VERSION ""

NS_ :

BS_:

BU_: Turbocharger OnBoardDataLogger OffBoardDiagnosticTool2 OffBoardDiagnosticTool1 FileServer ParkingBrakeController SeatControl2 FanDriveController SteeringColumnUnit CommunicationUnitRadio CommunicationUnitSatellite CommunicationUnitCellular PropulsionBatteryCharger ChassisController2 ChassisController1 EngineValveControl AuxiliaryHeater2 AuxiliaryHeater1 ClutchUnit RampControl InformationSystem1 SuspensionSystemController2 OilSensor VehicleDynamicStability ExhaustEmissionController TransmissionDisplay2 TransmissionDisplay1 ClimateControl2 WaterPumpController RearAxleSteeringController LightingOperatorControl SeatController1 IgnitionController2 IgnitionController1 TirePressureController CabController2 CabController1 PneumaticSystemController SuspensionSystemController1 HydraulicPumpController EnduranceBrakingSystem RetarderExhaustEngine2 OnBoardDiagnosticUnit HeadwayController RetarderExhaustEngine1 CabDisplay1 ManagementComputer VirtualTerminal OffVehicleGateway PowerTakeOffFront HitchControl AuxiliaryValveControl BodyController TractorTrailerBridge1 StarterSystem ElectricalSystem VehicleSecurity VehicleNavigation AerodynamicControl ElectricalChargingSystem ClimateControl1 TripRecorder InstrumentCluster SuspensionDriveAxle2 SuspensionDriveAxle1 SuspensionSteerAxle SteeringController FuelSystem CruiseControl RetarderDriveline RetarderEngine BrakesDriveAxle2 BrakesDriveAxle1 BrakesSystemController BrakesSteerAxle AxleDrive2 AxleDrive1 AxleSteering PowerTakeOff ShiftConsoleSecondary ShiftConsolePrimary Transmission2 Transmission1 Engine2 Engine1

BO_ 0000000000 DoS: 8 Vector__XXX
 SG_ DenialofService : 0|16@1+ (0.0025,0) [0|160.6375] "%" Vector__XXX

BO_ 3221225472 VECTOR__INDEPENDENT_SIG_MSG: 0 Vector__XXX
 SG_ TrailerWeight : 0|16@1+ (2,0) [0|128510] "kg" Vector__XXX
 SG_ ReferenceTirePressSetting : 0|8@1+ (8,0) [0|2000] "kPa" Vector__XXX
 SG_ ReferenceTirePress : 0|8@1+ (8,0) [0|2000] "kPa" Vector__XXX
 SG_ TirePressThresholdDetection : 0|3@1+ (1,0) [0|7] "" Vector__XXX
 SG_ TireAirLeakageRate : 0|16@1+ (0.1,0) [0|6425.5] "Pa/s" Vector__XXX
 SG_ CTIWheelEndElectricalFault : 0|2@1+ (1,0) [0|3] "" Vector__XXX
 SG_ CTITireStatus : 0|2@1+ (1,0) [0|3] "" Vector__XXX
 SG_ CTIWheelSensorStatus : 0|2@1+ (1,0) [0|3] "" Vector__XXX
 SG_ TireTemp : 0|16@1+ (0.03125,-273) [-273|1734.96875] "deg C" Vector__XXX
 SG_ TirePress : 0|8@1+ (4,0) [0|1000] "kPa" Vector__XXX

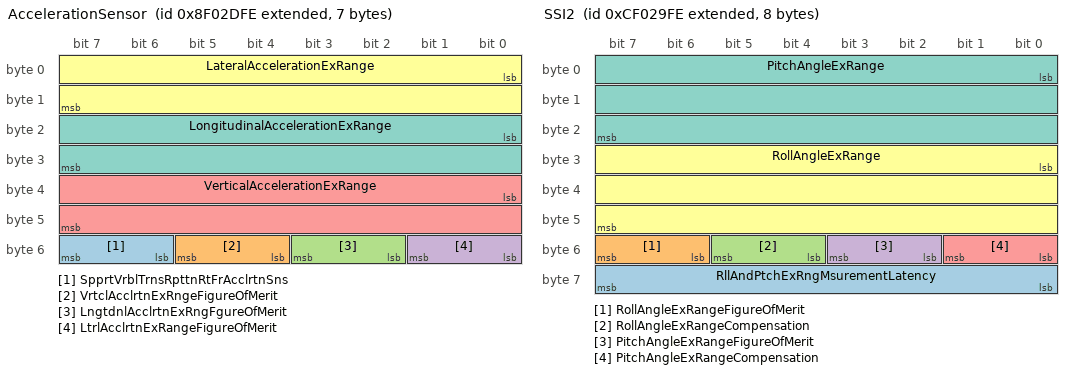
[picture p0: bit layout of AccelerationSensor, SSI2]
BO_ 2297441790 AccelerationSensor: 7 Vector__XXX
 SG_ SpprtVrblTrnsRpttnRtFrAcclrtnSns : 54|2@1+ (1,0) [0|3] "" Vector__XXX
 SG_ VrtclAcclrtnExRngeFigureOfMerit : 52|2@1+ (1,0) [0|3] "" Vector__XXX
 SG_ LngtdnlAcclrtnExRngFgureOfMerit : 50|2@1+ (1,0) [0|3] "" Vector__XXX
 SG_ LtrlAcclrtnExRangeFigureOfMerit : 48|2@1+ (1,0) [0|3] "" Vector__XXX
 SG_ VerticalAccelerationExRange : 32|16@1+ (0.01,-320) [-320|322.55] "m/s/s" Vector__XXX
 SG_ LateralAccelerationExRange : 0|16@1+ (0.01,-320) [-320|322.55] "m/s/s" Vector__XXX
 SG_ LongitudinalAccelerationExRange : 16|16@1+ (0.01,-320) [-320|322.55] "m/s/s" Vector__XXX

BO_ 2566712062 VEP4: 8 Vector__XXX
 SG_ HybrdBatteryPackRemainingCharge : 0|16@1+ (0.0025,0) [0|160.6375] "%" Vector__XXX

BO_ 2364549630 SSI2: 8 Vector__XXX
 SG_ RllAndPtchExRngMsurementLatency : 56|8@1+ (0.5,0) [0|125] "ms" Vector__XXX
 SG_ RollAngleExRangeFigureOfMerit : 54|2@1+ (1,0) [0|3] "" Vector__XXX
 SG_ RollAngleExRangeCompensation : 52|2@1+ (1,0) [0|3] "" Vector__XXX
 SG_ PitchAngleExRangeFigureOfMerit : 50|2@1+ (1,0) [0|3] "" Vector__XXX
 SG_ PitchAngleExRangeCompensation : 48|2@1+ (1,0) [0|3] "" Vector__XXX
 SG_ RollAngleExRange : 24|24@1+ (3.0517578125E-005,-250) [-250|250.9999] "deg" Vector__XXX
 SG_ PitchAngleExRange : 0|24@1+ (3.0517578125E-005,-250) [-250|250.9999] "deg" Vector__XXX

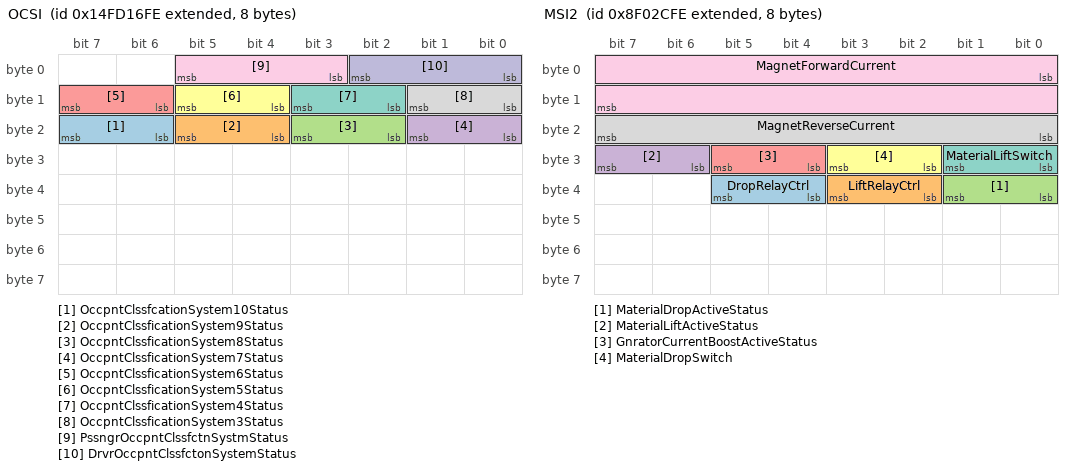
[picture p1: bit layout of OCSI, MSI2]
BO_ 2499614462 OCSI: 8 Vector__XXX
 SG_ OccpntClssfcationSystem10Status : 22|2@1+ (1,0) [0|3] "" Vector__XXX
 SG_ OccpntClssficationSystem9Status : 20|2@1+ (1,0) [0|3] "" Vector__XXX
 SG_ OccpntClssficationSystem8Status : 18|2@1+ (1,0) [0|3] "" Vector__XXX
 SG_ OccpntClssficationSystem7Status : 16|2@1+ (1,0) [0|3] "" Vector__XXX
 SG_ OccpntClssficationSystem6Status : 14|2@1+ (1,0) [0|3] "" Vector__XXX
 SG_ OccpntClssficationSystem5Status : 12|2@1+ (1,0) [0|3] "" Vector__XXX
 SG_ OccpntClssficationSystem4Status : 10|2@1+ (1,0) [0|3] "" Vector__XXX
 SG_ OccpntClssficationSystem3Status : 8|2@1+ (1,0) [0|3] "" Vector__XXX
 SG_ PssngrOccpntClssfctnSystmStatus : 3|3@1+ (1,0) [0|7] "" Vector__XXX
 SG_ DrvrOccpntClssfctonSystemStatus : 0|3@1+ (1,0) [0|7] "" Vector__XXX

BO_ 2560098046 NCS: 8 Vector__XXX
 SG_ CabNoiseCtrlTuningStatus : 2|4@1+ (1,0) [0|15] "" Vector__XXX
 SG_ CabNoiseCtrlStatus : 0|2@1+ (1,0) [0|3] "" Vector__XXX

BO_ 2560163582 NC1: 8 Vector__XXX
 SG_ CabNoiseCtrlTuningState : 2|3@1+ (1,0) [0|7] "" Vector__XXX
 SG_ CabNoiseCtrlState : 0|2@1+ (1,0) [0|3] "" Vector__XXX

BO_ 2297441534 MSI2: 8 Vector__XXX
 SG_ DropRelayCtrl : 36|2@1+ (1,0) [0|3] "" Vector__XXX
 SG_ LiftRelayCtrl : 34|2@1+ (1,0) [0|3] "" Vector__XXX
 SG_ MaterialDropActiveStatus : 32|2@1+ (1,0) [0|3] "" Vector__XXX
 SG_ MaterialLiftActiveStatus : 30|2@1+ (1,0) [0|3] "" Vector__XXX
 SG_ GnratorCurrentBoostActiveStatus : 28|2@1+ (1,0) [0|3] "" Vector__XXX
 SG_ MaterialDropSwitch : 26|2@1+ (1,0) [0|3] "" Vector__XXX
 SG_ MaterialLiftSwitch : 24|2@1+ (1,0) [0|3] "" Vector__XXX
 SG_ MagnetReverseCurrent : 16|8@1+ (1,0) [0|250] "A" Vector__XXX
 SG_ MagnetForwardCurrent : 0|16@1+ (1,0) [0|64255] "Amps" Vector__XXX

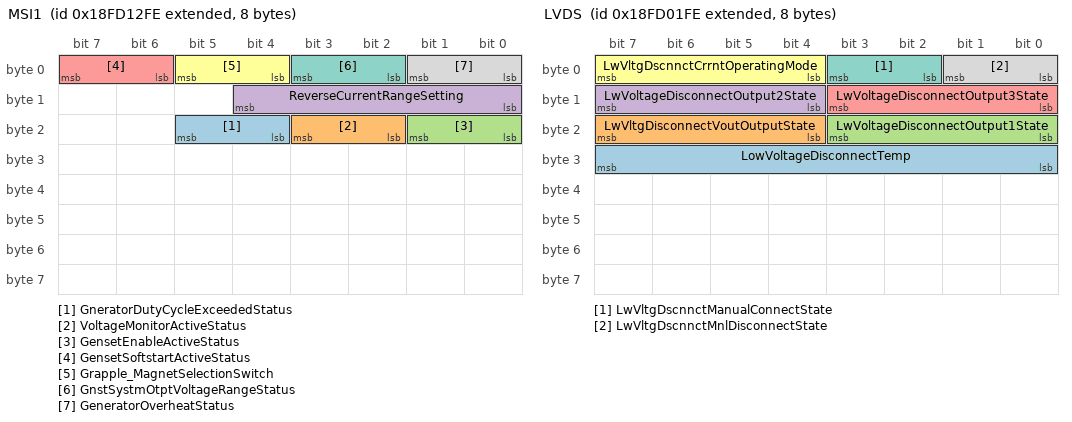
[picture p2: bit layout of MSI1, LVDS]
BO_ 2566722302 MSI1: 8 Vector__XXX
 SG_ GneratorDutyCycleExceededStatus : 20|2@1+ (1,0) [0|3] "" Vector__XXX
 SG_ VoltageMonitorActiveStatus : 18|2@1+ (1,0) [0|3] "" Vector__XXX
 SG_ GensetEnableActiveStatus : 16|2@1+ (1,0) [0|3] "" Vector__XXX
 SG_ ReverseCurrentRangeSetting : 8|5@1+ (1,0) [0|31] "" Vector__XXX
 SG_ GensetSoftstartActiveStatus : 6|2@1+ (1,0) [0|3] "" Vector__XXX
 SG_ Grapple_MagnetSelectionSwitch : 4|2@1+ (1,0) [0|3] "" Vector__XXX
 SG_ GnstSystmOtptVoltageRangeStatus : 2|2@1+ (1,0) [0|3] "" Vector__XXX
 SG_ GeneratorOverheatStatus : 0|2@1+ (1,0) [0|3] "" Vector__XXX

BO_ 2566722558 MSCI: 8 Vector__XXX
 SG_ MagnetRatedPower : 8|16@1+ (0.5,0) [0|32127.5] "kW" Vector__XXX
 SG_ MagnetBoostTime : 0|8@1+ (0.25,0) [0|62.5] "s" Vector__XXX

BO_ 2560032510 LVDSOM: 8 Vector__XXX
 SG_ LwVltgDscnnctDsredOperatingMode : 0|4@1+ (1,0) [0|15] "" Vector__XXX

BO_ 2566717950 LVDS: 8 Vector__XXX
 SG_ LowVoltageDisconnectTemp : 24|8@1+ (1,-40) [-40|210] "deg C" Vector__XXX
 SG_ LwVltgDisconnectVoutOutputState : 20|4@1+ (1,0) [0|15] "" Vector__XXX
 SG_ LwVoltageDisconnectOutput1State : 16|4@1+ (1,0) [0|15] "" Vector__XXX
 SG_ LwVoltageDisconnectOutput2State : 12|4@1+ (1,0) [0|15] "" Vector__XXX
 SG_ LwVoltageDisconnectOutput3State : 8|4@1+ (1,0) [0|15] "" Vector__XXX
 SG_ LwVltgDscnnctCrrntOperatingMode : 4|4@1+ (1,0) [0|15] "" Vector__XXX
 SG_ LwVltgDscnnctManualConnectState : 2|2@1+ (1,0) [0|3] "" Vector__XXX
 SG_ LwVltgDscnnctMnlDisconnectState : 0|2@1+ (1,0) [0|3] "" Vector__XXX

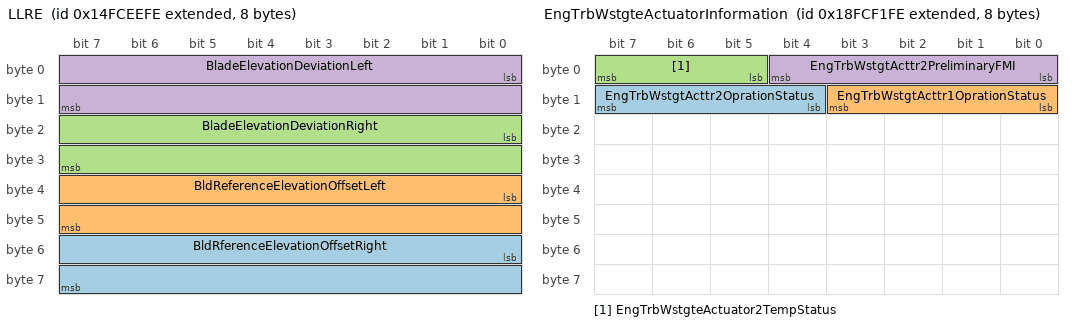
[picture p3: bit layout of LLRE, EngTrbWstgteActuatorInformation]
BO_ 2499604222 LLRE: 8 Vector__XXX
 SG_ BldRferenceElevationOffsetRight : 48|16@1+ (1,-32000) [-32000|32255] "mm" Vector__XXX
 SG_ BldReferenceElevationOffsetLeft : 32|16@1+ (1,-32000) [-32000|32255] "mm" Vector__XXX
 SG_ BladeElevationDeviationRight : 16|16@1+ (1,-32000) [-32000|32255] "mm" Vector__XXX
 SG_ BladeElevationDeviationLeft : 0|16@1+ (1,-32000) [-32000|32255] "mm" Vector__XXX

BO_ 2358902526 JLCM: 8 Vector__XXX
 SG_ Joystick3Lamp10Cmd : 58|2@1+ (1,0) [0|3] "" Vector__XXX
 SG_ Joystick3Lamp9Cmd : 56|2@1+ (1,0) [0|3] "" Vector__XXX
 SG_ Joystick3Lamp8Cmd : 54|2@1+ (1,0) [0|3] "" Vector__XXX
 SG_ Joystick3Lamp7Cmd : 52|2@1+ (1,0) [0|3] "" Vector__XXX
 SG_ Joystick3Lamp6Cmd : 50|2@1+ (1,0) [0|3] "" Vector__XXX
 SG_ Joystick3Lamp5Cmd : 48|2@1+ (1,0) [0|3] "" Vector__XXX
 SG_ Joystick3Lamp4Cmd : 46|2@1+ (1,0) [0|3] "" Vector__XXX
 SG_ Joystick3Lamp3Cmd : 44|2@1+ (1,0) [0|3] "" Vector__XXX
 SG_ Joystick3Lamp2Cmd : 42|2@1+ (1,0) [0|3] "" Vector__XXX
 SG_ Joystick3Lamp1Cmd : 40|2@1+ (1,0) [0|3] "" Vector__XXX
 SG_ Joystick2Lamp10Cmd : 38|2@1+ (1,0) [0|3] "" Vector__XXX
 SG_ Joystick2Lamp9Cmd : 36|2@1+ (1,0) [0|3] "" Vector__XXX
 SG_ Joystick2Lamp8Cmd : 34|2@1+ (1,0) [0|3] "" Vector__XXX
 SG_ Joystick2Lamp7Cmd : 32|2@1+ (1,0) [0|3] "" Vector__XXX
 SG_ Joystick2Lamp6Cmd : 30|2@1+ (1,0) [0|3] "" Vector__XXX
 SG_ Joystick2Lamp5Cmd : 28|2@1+ (1,0) [0|3] "" Vector__XXX
 SG_ Joystick2Lamp4Cmd : 26|2@1+ (1,0) [0|3] "" Vector__XXX
 SG_ Joystick2Lamp3Cmd : 24|2@1+ (1,0) [0|3] "" Vector__XXX
 SG_ Joystick2Lamp2Cmd : 22|2@1+ (1,0) [0|3] "" Vector__XXX
 SG_ Joystick2Lamp1Cmd : 20|2@1+ (1,0) [0|3] "" Vector__XXX
 SG_ Joystick1Lamp10Cmd : 18|2@1+ (1,0) [0|3] "" Vector__XXX
 SG_ Joystick1Lamp9Cmd : 16|2@1+ (1,0) [0|3] "" Vector__XXX
 SG_ Joystick1Lamp8Cmd : 14|2@1+ (1,0) [0|3] "" Vector__XXX
 SG_ Joystick1Lamp7Cmd : 12|2@1+ (1,0) [0|3] "" Vector__XXX
 SG_ Joystick1Lamp6Cmd : 10|2@1+ (1,0) [0|3] "" Vector__XXX
 SG_ Joystick1Lamp5Cmd : 8|2@1+ (1,0) [0|3] "" Vector__XXX
 SG_ Joystick1Lamp4Cmd : 6|2@1+ (1,0) [0|3] "" Vector__XXX
 SG_ Joystick1Lamp3Cmd : 4|2@1+ (1,0) [0|3] "" Vector__XXX
 SG_ Joystick1Lamp2Cmd : 2|2@1+ (1,0) [0|3] "" Vector__XXX
 SG_ Joystick1Lamp1Cmd : 0|2@1+ (1,0) [0|3] "" Vector__XXX

BO_ 2566711550 IVAC: 8 Vector__XXX
 SG_ IntkVlvActtnSystmOlPrss2SlndCtrl : 2|2@1+ (1,0) [0|3] "" Vector__XXX
 SG_ IntkVlvActtnSystmOlPrss1SlndCtrl : 0|2@1+ (1,0) [0|3] "" Vector__XXX

BO_ 2633832958 ILI: 200 Vector__XXX
 SG_ SpecialIgnitorLoop90Resistance : 1584|16@1+ (0.1,0) [0|6425.5] "ohm" Vector__XXX
 SG_ SpecialIgnitorLoop89Resistance : 1568|16@1+ (0.1,0) [0|6425.5] "ohm" Vector__XXX
 SG_ SpecialIgnitorLoop88Resistance : 1552|16@1+ (0.1,0) [0|6425.5] "ohm" Vector__XXX
 SG_ SpecialIgnitorLoop87Resistance : 1536|16@1+ (0.1,0) [0|6425.5] "ohm" Vector__XXX
 SG_ SpecialIgnitorLoop86Resistance : 1520|16@1+ (0.1,0) [0|6425.5] "ohm" Vector__XXX
 SG_ SpecialIgnitorLoop85Resistance : 1504|16@1+ (0.1,0) [0|6425.5] "ohm" Vector__XXX
 SG_ SpecialIgnitorLoop84Resistance : 1488|16@1+ (0.1,0) [0|6425.5] "ohm" Vector__XXX
 SG_ SpecialIgnitorLoop83Resistance : 1472|16@1+ (0.1,0) [0|6425.5] "ohm" Vector__XXX
 SG_ SpecialIgnitorLoop82Resistance : 1456|16@1+ (0.1,0) [0|6425.5] "ohm" Vector__XXX
 SG_ SpecialIgnitorLoop81Resistance : 1440|16@1+ (0.1,0) [0|6425.5] "ohm" Vector__XXX
 SG_ SpecialIgnitorLoop80Resistance : 1424|16@1+ (0.1,0) [0|6425.5] "ohm" Vector__XXX
 SG_ SpecialIgnitorLoop79Resistance : 1408|16@1+ (0.1,0) [0|6425.5] "ohm" Vector__XXX
 SG_ SpecialIgnitorLoop78Resistance : 1392|16@1+ (0.1,0) [0|6425.5] "ohm" Vector__XXX
 SG_ SpecialIgnitorLoop77Resistance : 1376|16@1+ (0.1,0) [0|6425.5] "ohm" Vector__XXX
 SG_ SpecialIgnitorLoop76Resistance : 1360|16@1+ (0.1,0) [0|6425.5] "ohm" Vector__XXX
 SG_ SpecialIgnitorLoop75Resistance : 1344|16@1+ (0.1,0) [0|6425.5] "ohm" Vector__XXX
 SG_ SpecialIgnitorLoop74Resistance : 1328|16@1+ (0.1,0) [0|6425.5] "ohm" Vector__XXX
 SG_ SpecialIgnitorLoop73Resistance : 1312|16@1+ (0.1,0) [0|6425.5] "ohm" Vector__XXX
 SG_ SpecialIgnitorLoop72Resistance : 1296|16@1+ (0.1,0) [0|6425.5] "ohm" Vector__XXX
 SG_ SpecialIgnitorLoop71Resistance : 1280|16@1+ (0.1,0) [0|6425.5] "ohm" Vector__XXX
 SG_ SpecialIgnitorLoop70Resistance : 1264|16@1+ (0.1,0) [0|6425.5] "ohm" Vector__XXX
 SG_ SpecialIgnitorLoop69Resistance : 1248|16@1+ (0.1,0) [0|6425.5] "ohm" Vector__XXX
 SG_ SpecialIgnitorLoop68Resistance : 1232|16@1+ (0.1,0) [0|6425.5] "ohm" Vector__XXX
 SG_ SpecialIgnitorLoop67Resistance : 1216|16@1+ (0.1,0) [0|6425.5] "ohm" Vector__XXX
 SG_ SpecialIgnitorLoop66Resistance : 1200|16@1+ (0.1,0) [0|6425.5] "ohm" Vector__XXX
 SG_ SpecialIgnitorLoop65Resistance : 1184|16@1+ (0.1,0) [0|6425.5] "ohm" Vector__XXX
 SG_ SpecialIgnitorLoop64Resistance : 1168|16@1+ (0.1,0) [0|6425.5] "ohm" Vector__XXX
 SG_ SpecialIgnitorLoop63Resistance : 1152|16@1+ (0.1,0) [0|6425.5] "ohm" Vector__XXX
 SG_ SpecialIgnitorLoop61Resistance : 1120|16@1+ (0.1,0) [0|6425.5] "ohm" Vector__XXX
 SG_ SpecialIgnitorLoop60Resistance : 1104|16@1+ (0.1,0) [0|6425.5] "ohm" Vector__XXX
 SG_ SpecialIgnitorLoop59Resistance : 1088|16@1+ (0.1,0) [0|6425.5] "ohm" Vector__XXX
 SG_ SpecialIgnitorLoop58Resistance : 1072|16@1+ (0.1,0) [0|6425.5] "ohm" Vector__XXX
 SG_ SpecialIgnitorLoop57Resistance : 1056|16@1+ (0.1,0) [0|6425.5] "ohm" Vector__XXX
 SG_ SpecialIgnitorLoop56Resistance : 1040|16@1+ (0.1,0) [0|6425.5] "ohm" Vector__XXX
 SG_ SpecialIgnitorLoop55Resistance : 1024|16@1+ (0.1,0) [0|6425.5] "ohm" Vector__XXX
 SG_ SpecialIgnitorLoop54Resistance : 1008|16@1+ (0.1,0) [0|6425.5] "ohm" Vector__XXX
 SG_ SpecialIgnitorLoop53Resistance : 992|16@1+ (0.1,0) [0|6425.5] "ohm" Vector__XXX
 SG_ SpecialIgnitorLoop52Resistance : 976|16@1+ (0.1,0) [0|6425.5] "ohm" Vector__XXX
 SG_ SpecialIgnitorLoop51Resistance : 960|16@1+ (0.1,0) [0|6425.5] "ohm" Vector__XXX
 SG_ SpecialIgnitorLoop50Resistance : 944|16@1+ (0.1,0) [0|6425.5] "ohm" Vector__XXX
 SG_ SpecialIgnitorLoop49Resistance : 928|16@1+ (0.1,0) [0|6425.5] "ohm" Vector__XXX
 SG_ SpecialIgnitorLoop48Resistance : 912|16@1+ (0.1,0) [0|6425.5] "ohm" Vector__XXX
 SG_ SpecialIgnitorLoop47Resistance : 896|16@1+ (0.1,0) [0|6425.5] "ohm" Vector__XXX
 SG_ SpecialIgnitorLoop46Resistance : 880|16@1+ (0.1,0) [0|6425.5] "ohm" Vector__XXX
 SG_ SpecialIgnitorLoop45Resistance : 864|16@1+ (0.1,0) [0|6425.5] "ohm" Vector__XXX
 SG_ SpecialIgnitorLoop44Resistance : 848|16@1+ (0.1,0) [0|6425.5] "ohm" Vector__XXX
 SG_ SpecialIgnitorLoop43Resistance : 832|16@1+ (0.1,0) [0|6425.5] "ohm" Vector__XXX
 SG_ SpecialIgnitorLoop42Resistance : 816|16@1+ (0.1,0) [0|6425.5] "ohm" Vector__XXX
 SG_ SpecialIgnitorLoop41Resistance : 800|16@1+ (0.1,0) [0|6425.5] "ohm" Vector__XXX
 SG_ SpecialIgnitorLoop40Resistance : 784|16@1+ (0.1,0) [0|6425.5] "ohm" Vector__XXX
 SG_ SpecialIgnitorLoop39Resistance : 768|16@1+ (0.1,0) [0|6425.5] "ohm" Vector__XXX
 SG_ SpecialIgnitorLoop38Resistance : 752|16@1+ (0.1,0) [0|6425.5] "ohm" Vector__XXX
 SG_ SpecialIgnitorLoop37Resistance : 736|16@1+ (0.1,0) [0|6425.5] "ohm" Vector__XXX
 SG_ SpecialIgnitorLoop36Resistance : 720|16@1+ (0.1,0) [0|6425.5] "ohm" Vector__XXX
 SG_ SpecialIgnitorLoop35Resistance : 704|16@1+ (0.1,0) [0|6425.5] "ohm" Vector__XXX
 SG_ SpecialIgnitorLoop34Resistance : 688|16@1+ (0.1,0) [0|6425.5] "ohm" Vector__XXX
 SG_ SpecialIgnitorLoop33Resistance : 672|16@1+ (0.1,0) [0|6425.5] "ohm" Vector__XXX
 SG_ SpecialIgnitorLoop32Resistance : 656|16@1+ (0.1,0) [0|6425.5] "ohm" Vector__XXX
 SG_ SpecialIgnitorLoop31Resistance : 640|16@1+ (0.1,0) [0|6425.5] "ohm" Vector__XXX
 SG_ SpecialIgnitorLoop30Resistance : 624|16@1+ (0.1,0) [0|6425.5] "ohm" Vector__XXX
 SG_ SpecialIgnitorLoop29Resistance : 608|16@1+ (0.1,0) [0|6425.5] "ohm" Vector__XXX
 SG_ SpecialIgnitorLoop28Resistance : 592|16@1+ (0.1,0) [0|6425.5] "ohm" Vector__XXX
 SG_ SpecialIgnitorLoop27Resistance : 576|16@1+ (0.1,0) [0|6425.5] "ohm" Vector__XXX
 SG_ SpecialIgnitorLoop26Resistance : 560|16@1+ (0.1,0) [0|6425.5] "ohm" Vector__XXX
 SG_ SpecialIgnitorLoop25Resistance : 544|16@1+ (0.1,0) [0|6425.5] "ohm" Vector__XXX
 SG_ SpecialIgnitorLoop24Resistance : 528|16@1+ (0.1,0) [0|6425.5] "ohm" Vector__XXX
 SG_ SpecialIgnitorLoop23Resistance : 512|16@1+ (0.1,0) [0|6425.5] "ohm" Vector__XXX
 SG_ SpecialIgnitorLoop22Resistance : 496|16@1+ (0.1,0) [0|6425.5] "ohm" Vector__XXX
 SG_ SpecialIgnitorLoop21Resistance : 480|16@1+ (0.1,0) [0|6425.5] "ohm" Vector__XXX
 SG_ SpecialIgnitorLoop20Resistance : 464|16@1+ (0.1,0) [0|6425.5] "ohm" Vector__XXX
 SG_ SpecialIgnitorLoop19Resistance : 448|16@1+ (0.1,0) [0|6425.5] "ohm" Vector__XXX
 SG_ SpecialIgnitorLoop18Resistance : 432|16@1+ (0.1,0) [0|6425.5] "ohm" Vector__XXX
 SG_ SpecialIgnitorLoop17Resistance : 416|16@1+ (0.1,0) [0|6425.5] "ohm" Vector__XXX
 SG_ SpecialIgnitorLoop16Resistance : 400|16@1+ (0.1,0) [0|6425.5] "ohm" Vector__XXX
 SG_ SpecialIgnitorLoop15Resistance : 384|16@1+ (0.1,0) [0|6425.5] "ohm" Vector__XXX
 SG_ SpecialIgnitorLoop14Resistance : 368|16@1+ (0.1,0) [0|6425.5] "ohm" Vector__XXX
 SG_ SpecialIgnitorLoop13Resistance : 352|16@1+ (0.1,0) [0|6425.5] "ohm" Vector__XXX
 SG_ SpecialIgnitorLoop12Resistance : 336|16@1+ (0.1,0) [0|6425.5] "ohm" Vector__XXX
 SG_ SpecialIgnitorLoop11Resistance : 320|16@1+ (0.1,0) [0|6425.5] "ohm" Vector__XXX
 SG_ SpecialIgnitorLoop10Resistance : 304|16@1+ (0.1,0) [0|6425.5] "ohm" Vector__XXX
 SG_ SpecialIgnitorLoop9Resistance : 288|16@1+ (0.1,0) [0|6425.5] "ohm" Vector__XXX
 SG_ SpecialIgnitorLoop8Resistance : 272|16@1+ (0.1,0) [0|6425.5] "ohm" Vector__XXX
 SG_ SpecialIgnitorLoop7Resistance : 256|16@1+ (0.1,0) [0|6425.5] "ohm" Vector__XXX
 SG_ SpecialIgnitorLoop6Resistance : 240|16@1+ (0.1,0) [0|6425.5] "ohm" Vector__XXX
 SG_ SpecialIgnitorLoop5Resistance : 224|16@1+ (0.1,0) [0|6425.5] "ohm" Vector__XXX
 SG_ SpecialIgnitorLoop4Resistance : 208|16@1+ (0.1,0) [0|6425.5] "ohm" Vector__XXX
 SG_ SpecialIgnitorLoop3Resistance : 192|16@1+ (0.1,0) [0|6425.5] "ohm" Vector__XXX
 SG_ SpecialIgnitorLoop2Resistance : 176|16@1+ (0.1,0) [0|6425.5] "ohm" Vector__XXX
 SG_ SpecialIgnitorLoop1Resistance : 160|16@1+ (0.1,0) [0|6425.5] "ohm" Vector__XXX
 SG_ SdBgIgnitorLoop2RightResistance : 144|16@1+ (0.1,0) [0|6425.5] "ohm" Vector__XXX
 SG_ SdBgIgnitorLoop1RightResistance : 128|16@1+ (0.1,0) [0|6425.5] "ohm" Vector__XXX
 SG_ SdBagIgnitorLoop2LeftResistance : 112|16@1+ (0.1,0) [0|6425.5] "ohm" Vector__XXX
 SG_ SdBagIgnitorLoop1LeftResistance : 96|16@1+ (0.1,0) [0|6425.5] "ohm" Vector__XXX
 SG_ PssngrBltTnsnrIgntrLpResistance : 80|16@1+ (0.1,0) [0|6425.5] "ohm" Vector__XXX
 SG_ DrvrBltTnsnrIgntrLoopResistance : 64|16@1+ (0.1,0) [0|6425.5] "ohm" Vector__XXX
 SG_ PssngrArbgIgntrLp2ndStgRsstance : 48|16@1+ (0.1,0) [0|6425.5] "ohm" Vector__XXX
 SG_ DrvrArbgIgntrLp2ndStgResistance : 32|16@1+ (0.1,0) [0|6425.5] "ohm" Vector__XXX
 SG_ PssngrArbgIgntrLp1stStgRsstance : 16|16@1+ (0.1,0) [0|6425.5] "ohm" Vector__XXX
 SG_ DrvrArbgIgntrLp1stStgResistance : 0|16@1+ (0.1,0) [0|6425.5] "ohm" Vector__XXX

BO_ 2566719998 HRLFC: 8 Vector__XXX
 SG_ HighResolutionEngTotalFuelUsed : 32|32@1+ (0.001,0) [0|4211081.215] "L" Vector__XXX
 SG_ HighResolutionEngTripFuel : 0|32@1+ (0.001,0) [0|4211081.215] "L" Vector__XXX

BO_ 2565877502 EngTrboWastegateActuatorCtrlCmd: 8 Vector__XXX
 SG_ EngTurboWastegateActuator2Cmd : 16|16@1+ (0.0025,0) [0|160.6375] "%" Vector__XXX
 SG_ EngTurboWastegateActuator1Cmd : 0|16@1+ (0.0025,0) [0|160.6375] "%" Vector__XXX

BO_ 2566713854 EngTrbWstgteActuatorInformation: 8 Vector__XXX
 SG_ EngTrbWstgtActtr2OprationStatus : 12|4@1+ (1,0) [0|15] "" Vector__XXX
 SG_ EngTrbWstgtActtr1OprationStatus : 8|4@1+ (1,0) [0|15] "" Vector__XXX
 SG_ EngTrbWstgteActuator2TempStatus : 5|3@1+ (1,0) [0|7] "" Vector__XXX
 SG_ EngTrbWstgtActtr2PreliminaryFMI : 0|5@1+ (1,0) [0|31] "" Vector__XXX

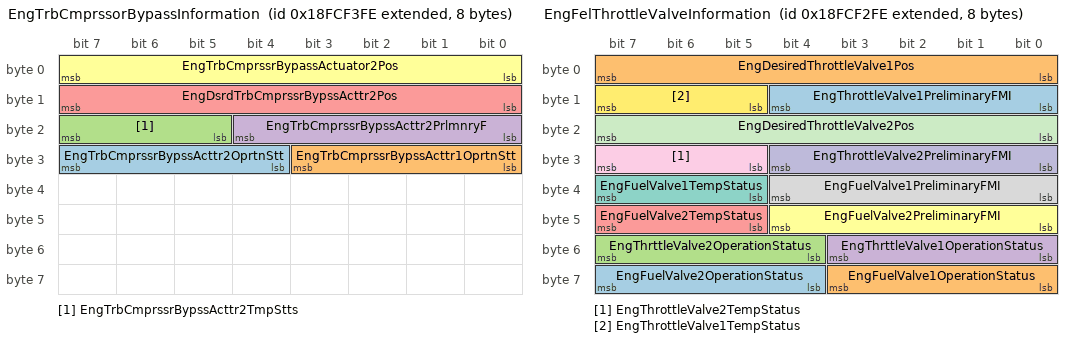
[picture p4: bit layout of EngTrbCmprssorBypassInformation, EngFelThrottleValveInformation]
BO_ 2566714366 EngTrbCmprssorBypassInformation: 8 Vector__XXX
 SG_ EngTrbCmprssrBypssActtr2OprtnStt : 28|4@1+ (1,0) [0|15] "" Vector__XXX
 SG_ EngTrbCmprssrBypssActtr1OprtnStt : 24|4@1+ (1,0) [0|15] "" Vector__XXX
 SG_ EngTrbCmprssrBypssActtr2TmpStts : 21|3@1+ (1,0) [0|7] "" Vector__XXX
 SG_ EngTrbCmprssrBypssActtr2PrlmnryF : 16|5@1+ (1,0) [0|31] "" Vector__XXX
 SG_ EngDsrdTrbCmprssrBypssActtr2Pos : 8|8@1+ (0.4,0) [0|100] "%" Vector__XXX
 SG_ EngTrbCmprssrBypassActuator2Pos : 0|8@1+ (0.4,0) [0|100] "%" Vector__XXX

BO_ 2566714110 EngFelThrottleValveInformation: 8 Vector__XXX
 SG_ EngFuelValve2OperationStatus : 60|4@1+ (1,0) [0|15] "" Vector__XXX
 SG_ EngFuelValve1OperationStatus : 56|4@1+ (1,0) [0|15] "" Vector__XXX
 SG_ EngThrttleValve2OperationStatus : 52|4@1+ (1,0) [0|15] "" Vector__XXX
 SG_ EngThrttleValve1OperationStatus : 48|4@1+ (1,0) [0|15] "" Vector__XXX
 SG_ EngFuelValve2TempStatus : 45|3@1+ (1,0) [0|7] "" Vector__XXX
 SG_ EngFuelValve2PreliminaryFMI : 40|5@1+ (1,0) [0|31] "" Vector__XXX
 SG_ EngFuelValve1TempStatus : 37|3@1+ (1,0) [0|7] "" Vector__XXX
 SG_ EngFuelValve1PreliminaryFMI : 32|5@1+ (1,0) [0|31] "" Vector__XXX
 SG_ EngThrottleValve2TempStatus : 29|3@1+ (1,0) [0|7] "" Vector__XXX
 SG_ EngThrottleValve2PreliminaryFMI : 24|5@1+ (1,0) [0|31] "" Vector__XXX
 SG_ EngDesiredThrottleValve2Pos : 16|8@1+ (0.4,0) [0|100] "%" Vector__XXX
 SG_ EngThrottleValve1TempStatus : 13|3@1+ (1,0) [0|7] "" Vector__XXX
 SG_ EngThrottleValve1PreliminaryFMI : 8|5@1+ (1,0) [0|31] "" Vector__XXX
 SG_ EngDesiredThrottleValve1Pos : 0|8@1+ (0.4,0) [0|100] "%" Vector__XXX

BO_ 2566717438 ET5: 8 Vector__XXX
 SG_ EngExhstGsRcrcltn2MxrIntakeTemp : 16|16@1+ (0.03125,-273) [-273|1734.96875] "deg C" Vector__XXX
 SG_ EngExhaustGasRecirculation2Temp : 0|16@1+ (0.03125,-273) [-273|1734.96875] "deg C" Vector__XXX

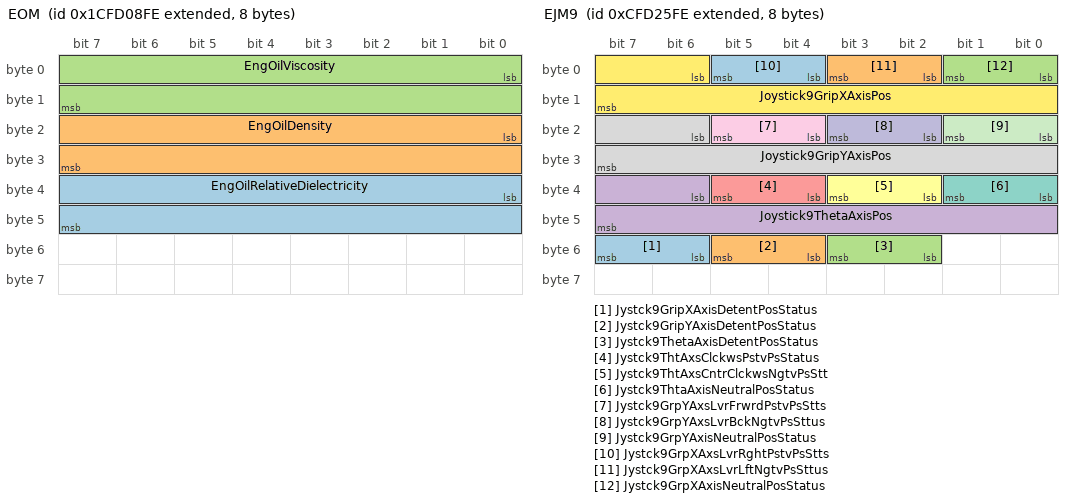
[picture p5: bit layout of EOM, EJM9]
BO_ 2633828606 EOM: 8 Vector__XXX
 SG_ EngOilRelativeDielectricity : 32|16@1+ (0.0001220703125,0) [0|7.844] "" Vector__XXX
 SG_ EngOilDensity : 16|16@1+ (3.052E-005,0) [0|1.961] "g/cc" Vector__XXX
 SG_ EngOilViscosity : 0|16@1+ (0.015625,0) [0|1003.984375] "Cp" Vector__XXX

BO_ 2499607550 EMAP: 8 Vector__XXX
 SG_ EngExhstMnfldBnk2FlwBlncVlvActtr : 16|16@1+ (0.0025,0) [0|160.6375] "%" Vector__XXX
 SG_ EngExhstMnfldBnk1FlwBlncVlvActtr : 0|16@1+ (0.0025,0) [0|160.6375] "%" Vector__XXX

BO_ 2633825534 EMAC: 8 Vector__XXX
 SG_ EngExhstMnfldBnk2FlwBlncVlv_0000 : 16|16@1+ (0.0025,0) [0|160.6375] "%" Vector__XXX
 SG_ EngExhstMnfldBnk1FlwBlncVlv_0000 : 0|16@1+ (0.0025,0) [0|160.6375] "%" Vector__XXX

BO_ 2365400574 EJM9: 8 Vector__XXX
 SG_ Jystck9GripXAxisDetentPosStatus : 54|2@1+ (1,0) [0|3] "" Vector__XXX
 SG_ Jystck9GripYAxisDetentPosStatus : 52|2@1+ (1,0) [0|3] "" Vector__XXX
 SG_ Jystck9ThetaAxisDetentPosStatus : 50|2@1+ (1,0) [0|3] "" Vector__XXX
 SG_ Joystick9ThetaAxisPos : 38|10@1+ (0.1,0) [0|102] "%" Vector__XXX
 SG_ Jystck9ThtAxsClckwsPstvPsStatus : 36|2@1+ (1,0) [0|3] "" Vector__XXX
 SG_ Jystck9ThtAxsCntrClckwsNgtvPsStt : 34|2@1+ (1,0) [0|3] "" Vector__XXX
 SG_ Jystck9ThtaAxisNeutralPosStatus : 32|2@1+ (1,0) [0|3] "" Vector__XXX
 SG_ Joystick9GripYAxisPos : 22|10@1+ (0.1,0) [0|102] "%" Vector__XXX
 SG_ Jystck9GrpYAxsLvrFrwrdPstvPsStts : 20|2@1+ (1,0) [0|3] "" Vector__XXX
 SG_ Jystck9GrpYAxsLvrBckNgtvPsSttus : 18|2@1+ (1,0) [0|3] "" Vector__XXX
 SG_ Jystck9GrpYAxisNeutralPosStatus : 16|2@1+ (1,0) [0|3] "" Vector__XXX
 SG_ Joystick9GripXAxisPos : 6|10@1+ (0.1,0) [0|102] "%" Vector__XXX
 SG_ Jystck9GrpXAxsLvrRghtPstvPsStts : 4|2@1+ (1,0) [0|3] "" Vector__XXX
 SG_ Jystck9GrpXAxsLvrLftNgtvPsSttus : 2|2@1+ (1,0) [0|3] "" Vector__XXX
 SG_ Jystck9GrpXAxisNeutralPosStatus : 0|2@1+ (1,0) [0|3] "" Vector__XXX

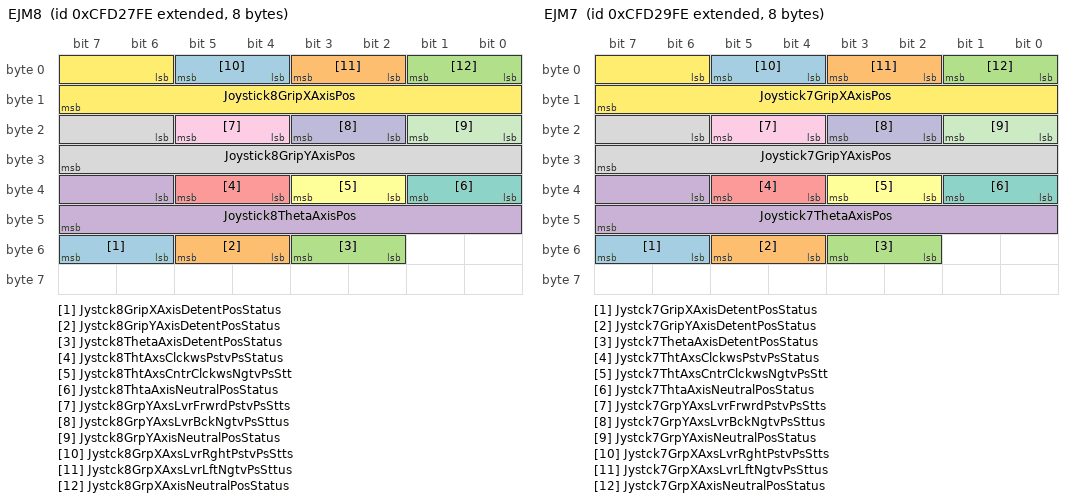
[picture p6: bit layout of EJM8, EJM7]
BO_ 2365401086 EJM8: 8 Vector__XXX
 SG_ Jystck8GripXAxisDetentPosStatus : 54|2@1+ (1,0) [0|3] "" Vector__XXX
 SG_ Jystck8GripYAxisDetentPosStatus : 52|2@1+ (1,0) [0|3] "" Vector__XXX
 SG_ Jystck8ThetaAxisDetentPosStatus : 50|2@1+ (1,0) [0|3] "" Vector__XXX
 SG_ Joystick8ThetaAxisPos : 38|10@1+ (0.1,0) [0|102] "%" Vector__XXX
 SG_ Jystck8ThtAxsClckwsPstvPsStatus : 36|2@1+ (1,0) [0|3] "" Vector__XXX
 SG_ Jystck8ThtAxsCntrClckwsNgtvPsStt : 34|2@1+ (1,0) [0|3] "" Vector__XXX
 SG_ Jystck8ThtaAxisNeutralPosStatus : 32|2@1+ (1,0) [0|3] "" Vector__XXX
 SG_ Joystick8GripYAxisPos : 22|10@1+ (0.1,0) [0|102] "%" Vector__XXX
 SG_ Jystck8GrpYAxsLvrFrwrdPstvPsStts : 20|2@1+ (1,0) [0|3] "" Vector__XXX
 SG_ Jystck8GrpYAxsLvrBckNgtvPsSttus : 18|2@1+ (1,0) [0|3] "" Vector__XXX
 SG_ Jystck8GrpYAxisNeutralPosStatus : 16|2@1+ (1,0) [0|3] "" Vector__XXX
 SG_ Joystick8GripXAxisPos : 6|10@1+ (0.1,0) [0|102] "%" Vector__XXX
 SG_ Jystck8GrpXAxsLvrRghtPstvPsStts : 4|2@1+ (1,0) [0|3] "" Vector__XXX
 SG_ Jystck8GrpXAxsLvrLftNgtvPsSttus : 2|2@1+ (1,0) [0|3] "" Vector__XXX
 SG_ Jystck8GrpXAxisNeutralPosStatus : 0|2@1+ (1,0) [0|3] "" Vector__XXX

BO_ 2365401598 EJM7: 8 Vector__XXX
 SG_ Jystck7GripXAxisDetentPosStatus : 54|2@1+ (1,0) [0|3] "" Vector__XXX
 SG_ Jystck7GripYAxisDetentPosStatus : 52|2@1+ (1,0) [0|3] "" Vector__XXX
 SG_ Jystck7ThetaAxisDetentPosStatus : 50|2@1+ (1,0) [0|3] "" Vector__XXX
 SG_ Joystick7ThetaAxisPos : 38|10@1+ (0.1,0) [0|102] "%" Vector__XXX
 SG_ Jystck7ThtAxsClckwsPstvPsStatus : 36|2@1+ (1,0) [0|3] "" Vector__XXX
 SG_ Jystck7ThtAxsCntrClckwsNgtvPsStt : 34|2@1+ (1,0) [0|3] "" Vector__XXX
 SG_ Jystck7ThtaAxisNeutralPosStatus : 32|2@1+ (1,0) [0|3] "" Vector__XXX
 SG_ Joystick7GripYAxisPos : 22|10@1+ (0.1,0) [0|102] "%" Vector__XXX
 SG_ Jystck7GrpYAxsLvrFrwrdPstvPsStts : 20|2@1+ (1,0) [0|3] "" Vector__XXX
 SG_ Jystck7GrpYAxsLvrBckNgtvPsSttus : 18|2@1+ (1,0) [0|3] "" Vector__XXX
 SG_ Jystck7GrpYAxisNeutralPosStatus : 16|2@1+ (1,0) [0|3] "" Vector__XXX
 SG_ Joystick7GripXAxisPos : 6|10@1+ (0.1,0) [0|102] "%" Vector__XXX
 SG_ Jystck7GrpXAxsLvrRghtPstvPsStts : 4|2@1+ (1,0) [0|3] "" Vector__XXX
 SG_ Jystck7GrpXAxsLvrLftNgtvPsSttus : 2|2@1+ (1,0) [0|3] "" Vector__XXX
 SG_ Jystck7GrpXAxisNeutralPosStatus : 0|2@1+ (1,0) [0|3] "" Vector__XXX

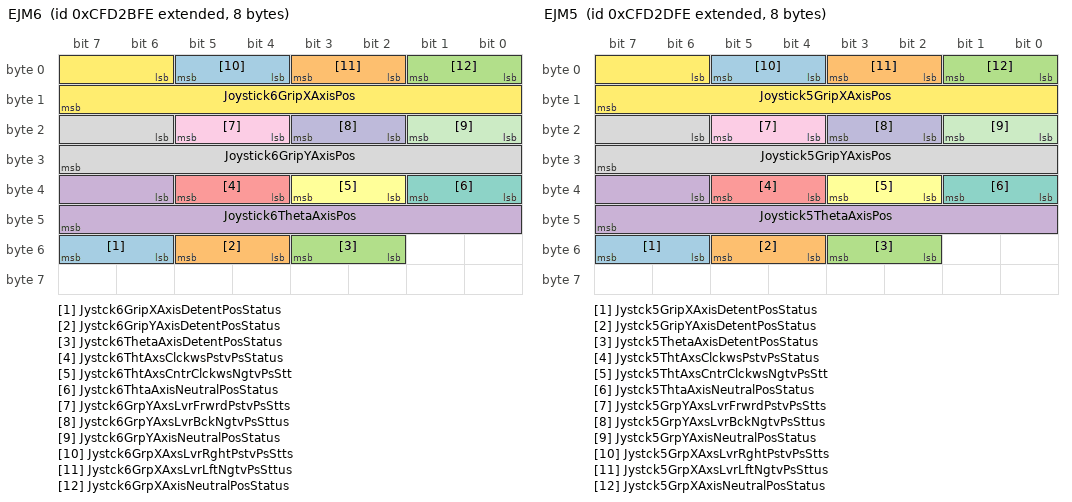
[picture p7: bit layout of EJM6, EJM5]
BO_ 2365402110 EJM6: 8 Vector__XXX
 SG_ Jystck6GripXAxisDetentPosStatus : 54|2@1+ (1,0) [0|3] "" Vector__XXX
 SG_ Jystck6GripYAxisDetentPosStatus : 52|2@1+ (1,0) [0|3] "" Vector__XXX
 SG_ Jystck6ThetaAxisDetentPosStatus : 50|2@1+ (1,0) [0|3] "" Vector__XXX
 SG_ Joystick6ThetaAxisPos : 38|10@1+ (0.1,0) [0|102] "%" Vector__XXX
 SG_ Jystck6ThtAxsClckwsPstvPsStatus : 36|2@1+ (1,0) [0|3] "" Vector__XXX
 SG_ Jystck6ThtAxsCntrClckwsNgtvPsStt : 34|2@1+ (1,0) [0|3] "" Vector__XXX
 SG_ Jystck6ThtaAxisNeutralPosStatus : 32|2@1+ (1,0) [0|3] "" Vector__XXX
 SG_ Joystick6GripYAxisPos : 22|10@1+ (0.1,0) [0|102] "%" Vector__XXX
 SG_ Jystck6GrpYAxsLvrFrwrdPstvPsStts : 20|2@1+ (1,0) [0|3] "" Vector__XXX
 SG_ Jystck6GrpYAxsLvrBckNgtvPsSttus : 18|2@1+ (1,0) [0|3] "" Vector__XXX
 SG_ Jystck6GrpYAxisNeutralPosStatus : 16|2@1+ (1,0) [0|3] "" Vector__XXX
 SG_ Joystick6GripXAxisPos : 6|10@1+ (0.1,0) [0|102] "%" Vector__XXX
 SG_ Jystck6GrpXAxsLvrRghtPstvPsStts : 4|2@1+ (1,0) [0|3] "" Vector__XXX
 SG_ Jystck6GrpXAxsLvrLftNgtvPsSttus : 2|2@1+ (1,0) [0|3] "" Vector__XXX
 SG_ Jystck6GrpXAxisNeutralPosStatus : 0|2@1+ (1,0) [0|3] "" Vector__XXX

BO_ 2365402622 EJM5: 8 Vector__XXX
 SG_ Jystck5GripXAxisDetentPosStatus : 54|2@1+ (1,0) [0|3] "" Vector__XXX
 SG_ Jystck5GripYAxisDetentPosStatus : 52|2@1+ (1,0) [0|3] "" Vector__XXX
 SG_ Jystck5ThetaAxisDetentPosStatus : 50|2@1+ (1,0) [0|3] "" Vector__XXX
 SG_ Joystick5ThetaAxisPos : 38|10@1+ (0.1,0) [0|102] "%" Vector__XXX
 SG_ Jystck5ThtAxsClckwsPstvPsStatus : 36|2@1+ (1,0) [0|3] "" Vector__XXX
 SG_ Jystck5ThtAxsCntrClckwsNgtvPsStt : 34|2@1+ (1,0) [0|3] "" Vector__XXX
 SG_ Jystck5ThtaAxisNeutralPosStatus : 32|2@1+ (1,0) [0|3] "" Vector__XXX
 SG_ Joystick5GripYAxisPos : 22|10@1+ (0.1,0) [0|102] "%" Vector__XXX
 SG_ Jystck5GrpYAxsLvrFrwrdPstvPsStts : 20|2@1+ (1,0) [0|3] "" Vector__XXX
 SG_ Jystck5GrpYAxsLvrBckNgtvPsSttus : 18|2@1+ (1,0) [0|3] "" Vector__XXX
 SG_ Jystck5GrpYAxisNeutralPosStatus : 16|2@1+ (1,0) [0|3] "" Vector__XXX
 SG_ Joystick5GripXAxisPos : 6|10@1+ (0.1,0) [0|102] "%" Vector__XXX
 SG_ Jystck5GrpXAxsLvrRghtPstvPsStts : 4|2@1+ (1,0) [0|3] "" Vector__XXX
 SG_ Jystck5GrpXAxsLvrLftNgtvPsSttus : 2|2@1+ (1,0) [0|3] "" Vector__XXX
 SG_ Jystck5GrpXAxisNeutralPosStatus : 0|2@1+ (1,0) [0|3] "" Vector__XXX

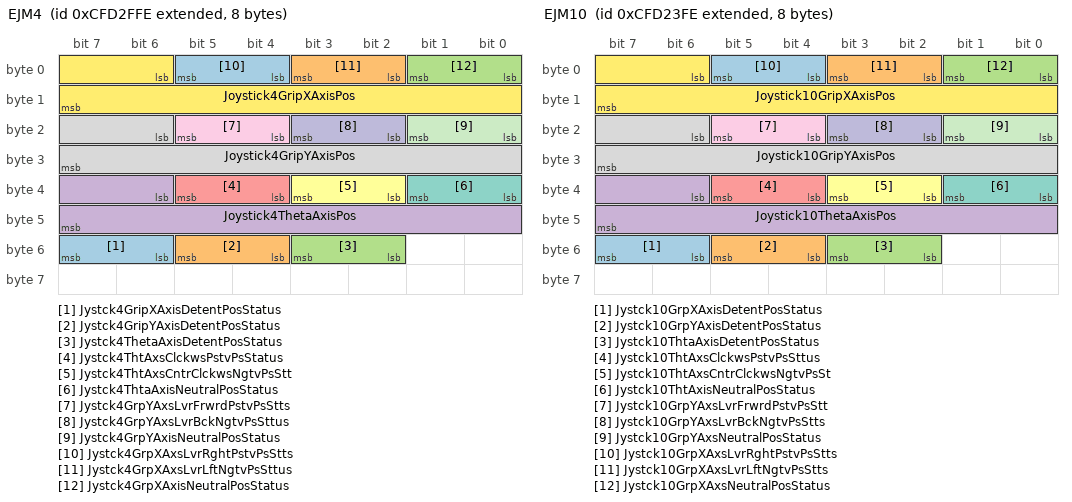
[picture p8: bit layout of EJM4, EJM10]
BO_ 2365403134 EJM4: 8 Vector__XXX
 SG_ Jystck4GripXAxisDetentPosStatus : 54|2@1+ (1,0) [0|3] "" Vector__XXX
 SG_ Jystck4GripYAxisDetentPosStatus : 52|2@1+ (1,0) [0|3] "" Vector__XXX
 SG_ Jystck4ThetaAxisDetentPosStatus : 50|2@1+ (1,0) [0|3] "" Vector__XXX
 SG_ Joystick4ThetaAxisPos : 38|10@1+ (0.1,0) [0|102] "%" Vector__XXX
 SG_ Jystck4ThtAxsClckwsPstvPsStatus : 36|2@1+ (1,0) [0|3] "" Vector__XXX
 SG_ Jystck4ThtAxsCntrClckwsNgtvPsStt : 34|2@1+ (1,0) [0|3] "" Vector__XXX
 SG_ Jystck4ThtaAxisNeutralPosStatus : 32|2@1+ (1,0) [0|3] "" Vector__XXX
 SG_ Joystick4GripYAxisPos : 22|10@1+ (0.1,0) [0|102] "%" Vector__XXX
 SG_ Jystck4GrpYAxsLvrFrwrdPstvPsStts : 20|2@1+ (1,0) [0|3] "" Vector__XXX
 SG_ Jystck4GrpYAxsLvrBckNgtvPsSttus : 18|2@1+ (1,0) [0|3] "" Vector__XXX
 SG_ Jystck4GrpYAxisNeutralPosStatus : 16|2@1+ (1,0) [0|3] "" Vector__XXX
 SG_ Joystick4GripXAxisPos : 6|10@1+ (0.1,0) [0|102] "%" Vector__XXX
 SG_ Jystck4GrpXAxsLvrRghtPstvPsStts : 4|2@1+ (1,0) [0|3] "" Vector__XXX
 SG_ Jystck4GrpXAxsLvrLftNgtvPsSttus : 2|2@1+ (1,0) [0|3] "" Vector__XXX
 SG_ Jystck4GrpXAxisNeutralPosStatus : 0|2@1+ (1,0) [0|3] "" Vector__XXX

BO_ 2365400062 EJM10: 8 Vector__XXX
 SG_ Jystck10GrpXAxisDetentPosStatus : 54|2@1+ (1,0) [0|3] "" Vector__XXX
 SG_ Jystck10GrpYAxisDetentPosStatus : 52|2@1+ (1,0) [0|3] "" Vector__XXX
 SG_ Jystck10ThtaAxisDetentPosStatus : 50|2@1+ (1,0) [0|3] "" Vector__XXX
 SG_ Joystick10ThetaAxisPos : 38|10@1+ (0.1,0) [0|102] "%" Vector__XXX
 SG_ Jystck10ThtAxsClckwsPstvPsSttus : 36|2@1+ (1,0) [0|3] "" Vector__XXX
 SG_ Jystck10ThtAxsCntrClckwsNgtvPsSt : 34|2@1+ (1,0) [0|3] "" Vector__XXX
 SG_ Jystck10ThtAxisNeutralPosStatus : 32|2@1+ (1,0) [0|3] "" Vector__XXX
 SG_ Joystick10GripYAxisPos : 22|10@1+ (0.1,0) [0|102] "%" Vector__XXX
 SG_ Jystck10GrpYAxsLvrFrwrdPstvPsStt : 20|2@1+ (1,0) [0|3] "" Vector__XXX
 SG_ Jystck10GrpYAxsLvrBckNgtvPsStts : 18|2@1+ (1,0) [0|3] "" Vector__XXX
 SG_ Jystck10GrpYAxsNeutralPosStatus : 16|2@1+ (1,0) [0|3] "" Vector__XXX
 SG_ Joystick10GripXAxisPos : 6|10@1+ (0.1,0) [0|102] "%" Vector__XXX
 SG_ Jystck10GrpXAxsLvrRghtPstvPsStts : 4|2@1+ (1,0) [0|3] "" Vector__XXX
 SG_ Jystck10GrpXAxsLvrLftNgtvPsStts : 2|2@1+ (1,0) [0|3] "" Vector__XXX
 SG_ Jystck10GrpXAxsNeutralPosStatus : 0|2@1+ (1,0) [0|3] "" Vector__XXX

BO_ 2566713598 EFS2: 8 Vector__XXX
 SG_ EngFuelFilterIntakeAbsPress : 0|8@1+ (2,0) [0|500] "kPa" Vector__XXX

BO_ 2499604478 EFL_P11: 8 Vector__XXX
 SG_ EngExhstGsRcrcltn1IntkeAbsPress : 0|16@1+ (0.1,0) [0|6425.5] "kPa" Vector__XXX

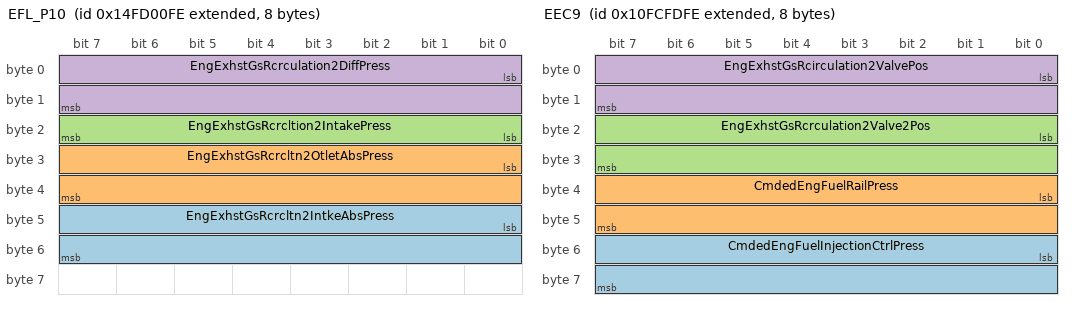
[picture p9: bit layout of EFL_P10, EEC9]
BO_ 2499608830 EFL_P10: 8 Vector__XXX
 SG_ EngExhstGsRcrcltn2IntkeAbsPress : 40|16@1+ (0.1,0) [0|6425.5] "kPa" Vector__XXX
 SG_ EngExhstGsRcrcltn2OtletAbsPress : 24|16@1+ (0.1,0) [0|6425.5] "kPa" Vector__XXX
 SG_ EngExhstGsRcrcltion2IntakePress : 16|8@1+ (2,0) [0|500] "kPa" Vector__XXX
 SG_ EngExhstGsRcrculation2DiffPress : 0|16@1+ (0.0078125,-250) [-250|251.99] "kPa" Vector__XXX

BO_ 2432499198 EEC9: 8 Vector__XXX
 SG_ CmdedEngFuelInjectionCtrlPress : 48|16@1+ (0.00390625,0) [0|251] "MPa" Vector__XXX
 SG_ CmdedEngFuelRailPress : 32|16@1+ (0.00390625,0) [0|251] "MPa" Vector__XXX
 SG_ EngExhstGsRcrculation2Valve2Pos : 16|16@1+ (0.0025,0) [0|160.6375] "%" Vector__XXX
 SG_ EngExhstGsRcirculation2ValvePos : 0|16@1+ (0.0025,0) [0|160.6375] "%" Vector__XXX

BO_ 2633825022 EEC11: 8 Vector__XXX
 SG_ EngExhstGsRcrclation2Valve2Ctrl : 16|16@1+ (0.0025,0) [0|160.6375] "%" Vector__XXX
 SG_ EngExhstGsRcrculation2ValveCtrl : 0|16@1+ (0.0025,0) [0|160.6375] "%" Vector__XXX

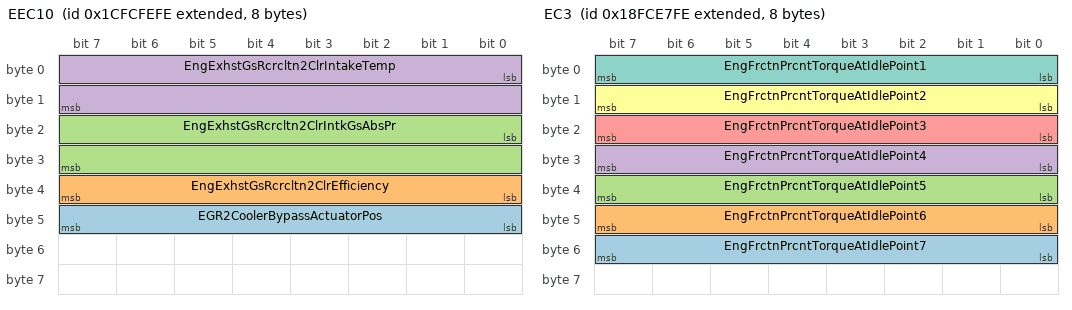
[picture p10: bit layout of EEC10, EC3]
BO_ 2633826046 EEC10: 8 Vector__XXX
 SG_ EGR2CoolerBypassActuatorPos : 40|8@1+ (0.4,0) [0|100] "%" Vector__XXX
 SG_ EngExhstGsRcrcltn2ClrEfficiency : 32|8@1+ (0.4,0) [0|100] "%" Vector__XXX
 SG_ EngExhstGsRcrcltn2ClrIntkGsAbsPr : 16|16@1+ (0.5,0) [0|32127.5] "kPa" Vector__XXX
 SG_ EngExhstGsRcrcltn2ClrIntakeTemp : 0|16@1+ (0.03125,-273) [-273|1734.96875] "deg C" Vector__XXX

BO_ 2566711294 EC3: 8 Vector__XXX
 SG_ EngFrctnPrcntTorqueAtIdlePoint7 : 48|8@1+ (1,-125) [-125|125] "%" Vector__XXX
 SG_ EngFrctnPrcntTorqueAtIdlePoint6 : 40|8@1+ (1,-125) [-125|125] "%" Vector__XXX
 SG_ EngFrctnPrcntTorqueAtIdlePoint5 : 32|8@1+ (1,-125) [-125|125] "%" Vector__XXX
 SG_ EngFrctnPrcntTorqueAtIdlePoint4 : 24|8@1+ (1,-125) [-125|125] "%" Vector__XXX
 SG_ EngFrctnPrcntTorqueAtIdlePoint3 : 16|8@1+ (1,-125) [-125|125] "%" Vector__XXX
 SG_ EngFrctnPrcntTorqueAtIdlePoint2 : 8|8@1+ (1,-125) [-125|125] "%" Vector__XXX
 SG_ EngFrctnPrcntTorqueAtIdlePoint1 : 0|8@1+ (1,-125) [-125|125] "%" Vector__XXX

BO_ 2566749438 DPFC1: 8 Vector__XXX
 SG_ DslPrtcltFltrActvRgnrtnFrcdStts : 53|3@1+ (1,0) [0|7] "" Vector__XXX
 SG_ ExhaustSystemHighTempLampCmd : 50|3@1+ (1,0) [0|7] "" Vector__XXX
 SG_ DslPrtcltFltrAtmtcActvRgnrtnIntt : 48|2@1+ (1,0) [0|3] "" Vector__XXX
 SG_ DslPrtcltFltrActvRgnrtnInhbtdDTV : 46|2@1+ (1,0) [0|3] "" Vector__XXX
 SG_ DslPrtcltFltrActvRgnrtnInhbtdDTE : 44|2@1+ (1,0) [0|3] "" Vector__XXX
 SG_ DslPrtcltFltrActvRgnrtnInhbtdDTP : 42|2@1+ (1,0) [0|3] "" Vector__XXX
 SG_ DslPrtcltFltrActvRgnrtnInhbtdDTT : 40|2@1+ (1,0) [0|3] "" Vector__XXX
 SG_ DslPrtcltFltrActvRgnrtnInhbtdDTS : 38|2@1+ (1,0) [0|3] "" Vector__XXX
 SG_ DslPrtcltFltrActvRgnrtnInhb_0000 : 36|2@1+ (1,0) [0|3] "" Vector__XXX
 SG_ DslPrtcltFltrActvRgnrtnInhbtdDTL : 34|2@1+ (1,0) [0|3] "" Vector__XXX
 SG_ DslPrtcltFltrActvRgnrtnInhb_0001 : 32|2@1+ (1,0) [0|3] "" Vector__XXX
 SG_ DslPrtcltFltrActvRgnrtnInhb_0002 : 30|2@1+ (1,0) [0|3] "" Vector__XXX
 SG_ DslPrtcltFltrActvRgnrtnInhbtdDTO : 28|2@1+ (1,0) [0|3] "" Vector__XXX
 SG_ DslPrtcltFltrActvRgnrtnInhbtdDTA : 26|2@1+ (1,0) [0|3] "" Vector__XXX
 SG_ DslPrtcltFltrActvRgnrtnInhb_0003 : 24|2@1+ (1,0) [0|3] "" Vector__XXX
 SG_ DslPrtcltFltrActvRgnrtnInhb_0004 : 22|2@1+ (1,0) [0|3] "" Vector__XXX
 SG_ DslPrtcltFltrActvRgnrtnInhbtdDTC : 20|2@1+ (1,0) [0|3] "" Vector__XXX
 SG_ DslPrtcltFltrActvRgnrtnInhbtdDTI : 18|2@1+ (1,0) [0|3] "" Vector__XXX
 SG_ DslPrtcltFltrActvRgnrtnInhbtdStt : 16|2@1+ (1,0) [0|3] "" Vector__XXX
 SG_ DieselParticulateFilterStatus : 12|3@1+ (1,0) [0|7] "" Vector__XXX
 SG_ DslPrtcltFltrActvRgnrtionStatus : 10|2@1+ (1,0) [0|3] "" Vector__XXX
 SG_ DslPrtcltFltrPssvRgnrtionStatus : 8|2@1+ (1,0) [0|3] "" Vector__XXX
 SG_ DieselParticulateFilterLampCmd : 0|3@1+ (1,0) [0|7] "" Vector__XXX

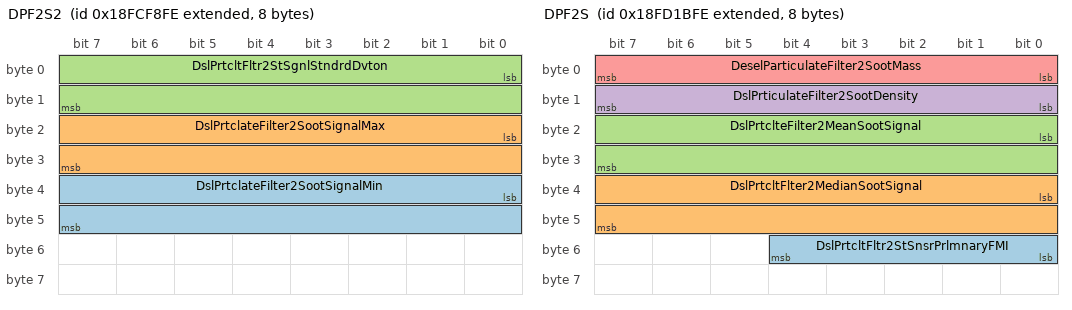
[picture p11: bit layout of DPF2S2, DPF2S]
BO_ 2566715646 DPF2S2: 8 Vector__XXX
 SG_ DslPrtclateFilter2SootSignalMin : 32|16@1+ (0.0025,0) [0|160.6375] "%" Vector__XXX
 SG_ DslPrtclateFilter2SootSignalMax : 16|16@1+ (0.0025,0) [0|160.6375] "%" Vector__XXX
 SG_ DslPrtcltFltr2StSgnlStndrdDvton : 0|16@1+ (0.0025,0) [0|160.6375] "%" Vector__XXX

BO_ 2566724606 DPF2S: 8 Vector__XXX
 SG_ DslPrtcltFltr2StSnsrPrlmnaryFMI : 48|5@1+ (1,0) [0|31] "" Vector__XXX
 SG_ DslPrtcltFlter2MedianSootSignal : 32|16@1+ (0.0025,0) [0|160.6375] "%" Vector__XXX
 SG_ DslPrtclteFilter2MeanSootSignal : 16|16@1+ (0.0025,0) [0|160.6375] "%" Vector__XXX
 SG_ DslPrticulateFilter2SootDensity : 8|8@1+ (0.08,0) [0|20] "g/L" Vector__XXX
 SG_ DeselParticulateFilter2SootMass : 0|8@1+ (4,0) [0|1000] "g" Vector__XXX

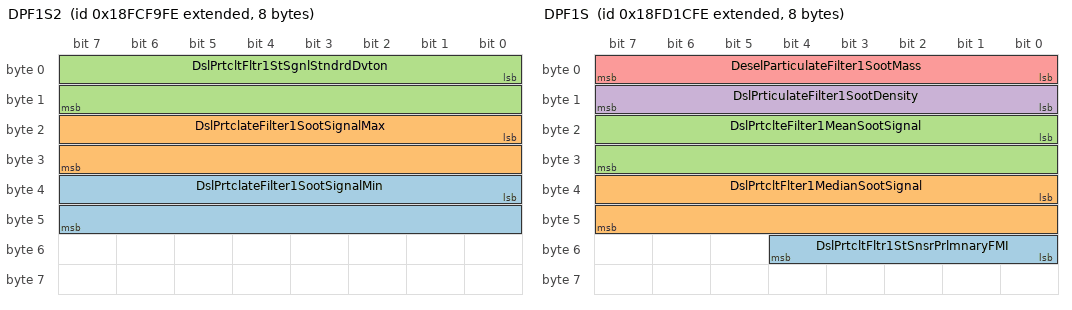
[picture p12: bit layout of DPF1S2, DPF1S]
BO_ 2566715902 DPF1S2: 8 Vector__XXX
 SG_ DslPrtclateFilter1SootSignalMin : 32|16@1+ (0.0025,0) [0|160.6375] "%" Vector__XXX
 SG_ DslPrtclateFilter1SootSignalMax : 16|16@1+ (0.0025,0) [0|160.6375] "%" Vector__XXX
 SG_ DslPrtcltFltr1StSgnlStndrdDvton : 0|16@1+ (0.0025,0) [0|160.6375] "%" Vector__XXX

BO_ 2566724862 DPF1S: 8 Vector__XXX
 SG_ DslPrtcltFltr1StSnsrPrlmnaryFMI : 48|5@1+ (1,0) [0|31] "" Vector__XXX
 SG_ DslPrtcltFlter1MedianSootSignal : 32|16@1+ (0.0025,0) [0|160.6375] "%" Vector__XXX
 SG_ DslPrtclteFilter1MeanSootSignal : 16|16@1+ (0.0025,0) [0|160.6375] "%" Vector__XXX
 SG_ DslPrticulateFilter1SootDensity : 8|8@1+ (0.08,0) [0|20] "g/L" Vector__XXX
 SG_ DeselParticulateFilter1SootMass : 0|8@1+ (4,0) [0|1000] "g" Vector__XXX

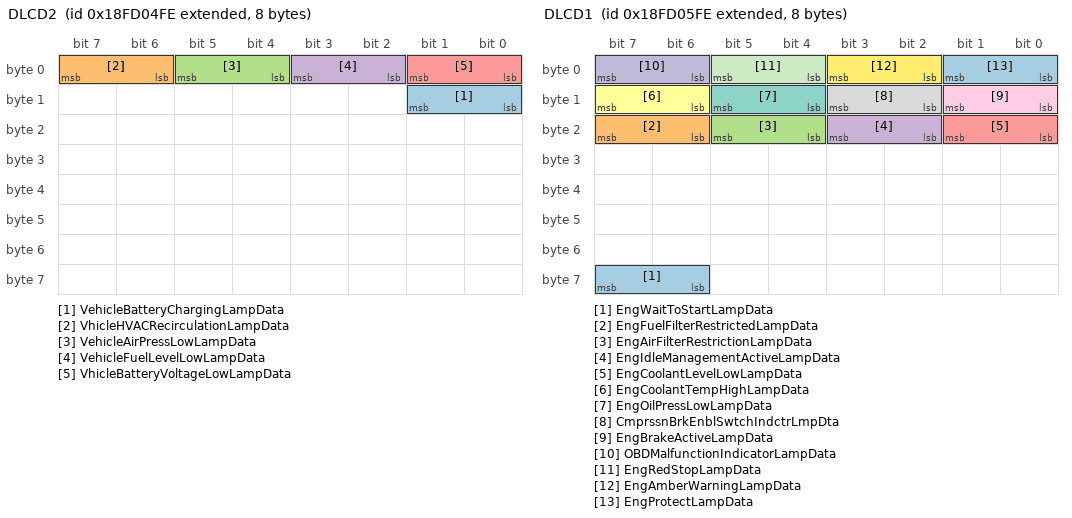
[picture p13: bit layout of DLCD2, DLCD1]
BO_ 2566718718 DLCD2: 8 Vector__XXX
 SG_ VehicleBatteryChargingLampData : 8|2@1+ (1,0) [0|3] "" Vector__XXX
 SG_ VhicleHVACRecirculationLampData : 6|2@1+ (1,0) [0|3] "" Vector__XXX
 SG_ VehicleAirPressLowLampData : 4|2@1+ (1,0) [0|3] "" Vector__XXX
 SG_ VehicleFuelLevelLowLampData : 2|2@1+ (1,0) [0|3] "" Vector__XXX
 SG_ VhicleBatteryVoltageLowLampData : 0|2@1+ (1,0) [0|3] "" Vector__XXX

BO_ 2566718974 DLCD1: 8 Vector__XXX
 SG_ EngWaitToStartLampData : 62|2@1+ (1,0) [0|3] "" Vector__XXX
 SG_ EngFuelFilterRestrictedLampData : 22|2@1+ (1,0) [0|3] "" Vector__XXX
 SG_ EngAirFilterRestrictionLampData : 20|2@1+ (1,0) [0|3] "" Vector__XXX
 SG_ EngIdleManagementActiveLampData : 18|2@1+ (1,0) [0|3] "" Vector__XXX
 SG_ EngCoolantLevelLowLampData : 16|2@1+ (1,0) [0|3] "" Vector__XXX
 SG_ EngCoolantTempHighLampData : 14|2@1+ (1,0) [0|3] "" Vector__XXX
 SG_ EngOilPressLowLampData : 12|2@1+ (1,0) [0|3] "" Vector__XXX
 SG_ CmprssnBrkEnblSwtchIndctrLmpDta : 10|2@1+ (1,0) [0|3] "" Vector__XXX
 SG_ EngBrakeActiveLampData : 8|2@1+ (1,0) [0|3] "" Vector__XXX
 SG_ OBDMalfunctionIndicatorLampData : 6|2@1+ (1,0) [0|3] "" Vector__XXX
 SG_ EngRedStopLampData : 4|2@1+ (1,0) [0|3] "" Vector__XXX
 SG_ EngAmberWarningLampData : 2|2@1+ (1,0) [0|3] "" Vector__XXX
 SG_ EngProtectLampData : 0|2@1+ (1,0) [0|3] "" Vector__XXX

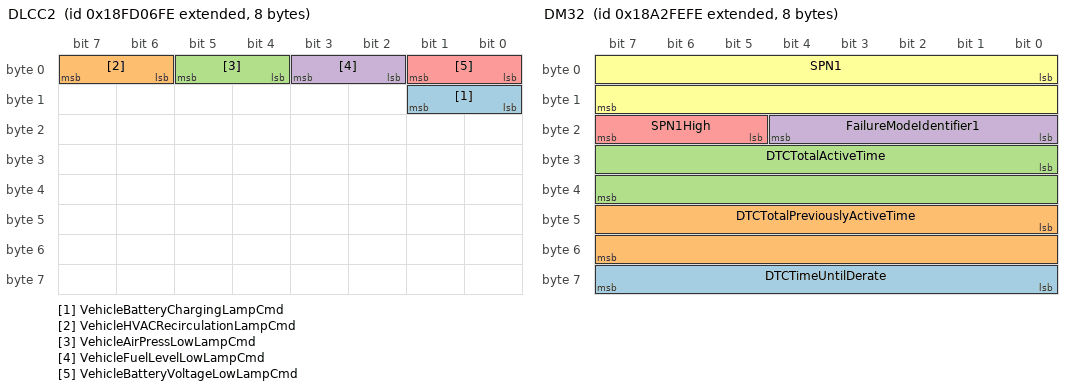
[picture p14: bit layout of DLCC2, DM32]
BO_ 2566719230 DLCC2: 8 Vector__XXX
 SG_ VehicleBatteryChargingLampCmd : 8|2@1+ (1,0) [0|3] "" Vector__XXX
 SG_ VehicleHVACRecirculationLampCmd : 6|2@1+ (1,0) [0|3] "" Vector__XXX
 SG_ VehicleAirPressLowLampCmd : 4|2@1+ (1,0) [0|3] "" Vector__XXX
 SG_ VehicleFuelLevelLowLampCmd : 2|2@1+ (1,0) [0|3] "" Vector__XXX
 SG_ VehicleBatteryVoltageLowLampCmd : 0|2@1+ (1,0) [0|3] "" Vector__XXX

BO_ 2560818942 DM32: 8 Vector__XXX
 SG_ DTCTimeUntilDerate : 56|8@1+ (0.25,0) [0|62.5] "hr" Vector__XXX
 SG_ DTCTotalPreviouslyActiveTime : 40|16@1+ (0.2,0) [0|12851] "hr" Vector__XXX
 SG_ DTCTotalActiveTime : 24|16@1+ (0.2,0) [0|12851] "hr" Vector__XXX
 SG_ FailureModeIdentifier1 : 16|5@1+ (1,0) [0|0] "" Vector__XXX
 SG_ SPN1High : 21|3@1+ (1,0) [0|7] "" Vector__XXX
 SG_ SPN1 : 0|16@1+ (1,0) [0|65536] "" Vector__XXX

CM_ BO_ 3221225472 "This is a message for not used signals, created by Vector CANdb++ DBC OLE DB Provider.";
CM_ SG_ 3221225472 TrailerWeight "Total mass of freight-carrying vehicle designed to be pulled by truck, including the weight of the contents.";
CM_ SG_ 3221225472 ReferenceTirePressSetting "Reference value of the tire pressure setting as basis for the tire pressure monitoring";
CM_ SG_ 3221225472 ReferenceTirePress "Reference value of the tire pressure as basis for the tire pressure monitoring";
CM_ SG_ 3221225472 TirePressThresholdDetection "Signal indicating the pressure level of the tire.";
CM_ SG_ 3221225472 TireAirLeakageRate "The pressure loss rate of a tire.";
CM_ SG_ 3221225472 CTIWheelEndElectricalFault "Indicates the status of electrical fault on CTI wheel interface.";
CM_ SG_ 3221225472 CTITireStatus "Indicates the status of the tire.";
CM_ SG_ 3221225472 CTIWheelSensorStatus "Indicates whether the wheel is being monitored by the CTI controller.";
CM_ SG_ 3221225472 TireTemp "Temperature at the surface of the tire sidewall.";
CM_ SG_ 3221225472 TirePress "Pressure at which air is contained in cavity formed by tire and rim.";
CM_ BO_ 2297441790 "The acceleration sensor message shall provide a measurement of the vehicle's acceleration in the lateral, longitudinal,
and vertical axes.";
CM_ SG_ 2297441790 SpprtVrblTrnsRpttnRtFrAcclrtnSns "Indicates which acceleration transmission rate are supported by the ECU in addition to the required 10 ms transmission";
CM_ SG_ 2297441790 VrtclAcclrtnExRngeFigureOfMerit "Figure of merit for vertical acceleration measurement.";
CM_ SG_ 2297441790 LngtdnlAcclrtnExRngFgureOfMerit "Figure of merit for longitudinal acceleration measurement.";
CM_ SG_ 2297441790 LtrlAcclrtnExRangeFigureOfMerit "Figure of merit for lateral acceleration measurement.";
CM_ SG_ 2297441790 VerticalAccelerationExRange "Indicates vertical acceleration of the vehicle and the effect of gravity.";
CM_ SG_ 2297441790 LateralAccelerationExRange "Indicates lateral acceleration of the vehicle.";
CM_ SG_ 2297441790 LongitudinalAccelerationExRange "Indicates longitudinal acceleration of the vehicle.";
CM_ BO_ 2566712062 "Vehicle Electrical Power #4";
CM_ SG_ 2566712062 HybrdBatteryPackRemainingCharge "Indicates the hybrid battery pack remaining charge.";
CM_ BO_ 2364549630 "Slope Sensor Information 2";
CM_ SG_ 2364549630 RllAndPtchExRngMsurementLatency "Time between start of sensor processing and CAN transmission";
CM_ SG_ 2364549630 RollAngleExRangeFigureOfMerit "Figure of merit for roll angle measurement.";
CM_ SG_ 2364549630 RollAngleExRangeCompensation "Compensated mode for the roll measurement.";
CM_ SG_ 2364549630 PitchAngleExRangeFigureOfMerit "Figure of merit for pitch angle measurement.";
CM_ SG_ 2364549630 PitchAngleExRangeCompensation "Compensated mode for the pitch measurement.";
CM_ SG_ 2364549630 RollAngleExRange "The angle between the vehicle y-axis and the ground plane.";
CM_ SG_ 2364549630 PitchAngleExRange "The angle between the vehicle x-axis and the ground plane.";
CM_ BO_ 2499614462 "Occupant Classification System Information";
CM_ SG_ 2499614462 OccpntClssfcationSystem10Status "State of Occupant Classification System for seat position 10.";
CM_ SG_ 2499614462 OccpntClssficationSystem9Status "State of Occupant Classification System for seat position 9.";
CM_ SG_ 2499614462 OccpntClssficationSystem8Status "State of Occupant Classification System for seat position 8.";
CM_ SG_ 2499614462 OccpntClssficationSystem7Status "State of Occupant Classification System for seat position 7.";
CM_ SG_ 2499614462 OccpntClssficationSystem6Status "State of Occupant Classification System for seat position 6.";
CM_ SG_ 2499614462 OccpntClssficationSystem5Status "State of Occupant Classification System for seat position 5.";
CM_ SG_ 2499614462 OccpntClssficationSystem4Status "State of Occupant Classification System for seat position 4.";
CM_ SG_ 2499614462 OccpntClssficationSystem3Status "State of Occupant Classification System for seat position 3.";
CM_ SG_ 2499614462 PssngrOccpntClssfctnSystmStatus "State of Occupant Classification System for passenger.";
CM_ SG_ 2499614462 DrvrOccpntClssfctonSystemStatus "State of Occupant Classification System for driver.";
CM_ BO_ 2560098046 "Noise Control Status";
CM_ SG_ 2560098046 CabNoiseCtrlTuningStatus "This parameter returns the current status of tuning function of the Cab Noise Control system.";
CM_ SG_ 2560098046 CabNoiseCtrlStatus "This parameter returns the current status of the Cab Noise Control system.";
CM_ BO_ 2560163582 "Noise Control 1";
CM_ SG_ 2560163582 CabNoiseCtrlTuningState "Command values for the Tuning State of the Cab Noise Control System.";
CM_ SG_ 2560163582 CabNoiseCtrlState "Command signal to change the state of the Cab Noise Control System to on-line or off-line";
CM_ BO_ 2297441534 "Magnet Status Information 2";
CM_ SG_ 2297441534 DropRelayCtrl "Command signal used to Engage and Disengage the Drop Relay controlling a Steady-State Magnet.";
CM_ SG_ 2297441534 LiftRelayCtrl "Command signal used to Engage and Disengage the Lift Relay controlling a Steady-State Magnet.";
CM_ SG_ 2297441534 MaterialDropActiveStatus "The status of Material Drop Relay.";
CM_ SG_ 2297441534 MaterialLiftActiveStatus "The status of Material Lift Relay.";
CM_ SG_ 2297441534 GnratorCurrentBoostActiveStatus "Status of generator current boost relay that can boost the generator output current for picking-up material operations.";
CM_ SG_ 2297441534 MaterialDropSwitch "This is a switch that can be used to enable the drop functionality of the Material Handler machine.";
CM_ SG_ 2297441534 MaterialLiftSwitch "This is a switch that can be used to enable the lift functionality of the Material Handler machine.";
CM_ SG_ 2297441534 MagnetReverseCurrent "A reverse current being supplied to the electric magnet to reduce the forward current generated magnet field as quick as";
CM_ SG_ 2297441534 MagnetForwardCurrent "The forward current being supplied by the generator to the electric magnet to create a magnet field to lift material.";
CM_ BO_ 2566722302 "Magnet Status Information 1";
CM_ SG_ 2566722302 GneratorDutyCycleExceededStatus "The status of the duty cycle of the generator usage, indicating if the generator has been on for too much time within a";
CM_ SG_ 2566722302 VoltageMonitorActiveStatus "Status of Voltage Monitor Relay.";
CM_ SG_ 2566722302 GensetEnableActiveStatus "Status of the Genset Enable Relay that enables or disables the Genset.";
CM_ SG_ 2566722302 ReverseCurrentRangeSetting "The operator setting for the Reverse Current.";
CM_ SG_ 2566722302 GensetSoftstartActiveStatus "The Genset Softstart Active Status refers to the status of the genset softstart relay.";
CM_ SG_ 2566722302 Grapple_MagnetSelectionSwitch "This is a switch that can be used to select either the Grapple or Magnet function of the material handler machine.";
CM_ SG_ 2566722302 GnstSystmOtptVoltageRangeStatus "Status of generator voltage in or out of desired operating range.";
CM_ SG_ 2566722302 GeneratorOverheatStatus "The Status of Generator being Overheated.";
CM_ BO_ 2566722558 "Magnet System Configuration Information";
CM_ SG_ 2566722558 MagnetRatedPower "The rated power that the magnet can accept during material holding operations.";
CM_ SG_ 2566722558 MagnetBoostTime "The duration of time after the activation of the magnet circuit that a relatively high current is sent to the magnet for";
CM_ BO_ 2560032510 "Low Voltage Disconnect Set Operating Mode";
CM_ SG_ 2560032510 LwVltgDscnnctDsredOperatingMode "Desired Operating Mode of the LVD.";
CM_ BO_ 2566717950 "Low Voltage Disconnect Status";
CM_ SG_ 2566717950 LowVoltageDisconnectTemp "Internal temperature of the LVD.";
CM_ SG_ 2566717950 LwVltgDisconnectVoutOutputState "State of the Vout Output from the LVD.";
CM_ SG_ 2566717950 LwVoltageDisconnectOutput1State "State of the Output #1 from the LVD.";
CM_ SG_ 2566717950 LwVoltageDisconnectOutput2State "State of the Output #2 from the LVD.";
CM_ SG_ 2566717950 LwVoltageDisconnectOutput3State "State of the Output #3 from the LVD.";
CM_ SG_ 2566717950 LwVltgDscnnctCrrntOperatingMode "Current operating mode of the LVD.";
CM_ SG_ 2566717950 LwVltgDscnnctManualConnectState "State of the Manual Connect hardwired input to the LVD.";
CM_ SG_ 2566717950 LwVltgDscnnctMnlDisconnectState "State of the Manual Disconnect hardwired input to the LVD.";
CM_ BO_ 2499604222 "Land Leveling System Reference Elevation Data";
CM_ SG_ 2499604222 BldRferenceElevationOffsetRight "Indicates the blade's right elevation offset with respect to the reference elevation.";
CM_ SG_ 2499604222 BldReferenceElevationOffsetLeft "Indicates the blade's left elevation offset with respect to the reference elevation.";
CM_ SG_ 2499604222 BladeElevationDeviationRight "Indicate the blade's right elevation deviation with respect to the reference elevation.";
CM_ SG_ 2499604222 BladeElevationDeviationLeft "Indicate the blade's left elevation deviation with respect to the reference elevation.";
CM_ BO_ 2358902526 "Joystick Lamp Command Message";
CM_ SG_ 2358902526 Joystick3Lamp10Cmd "Tells joystick 3 to switch on/off/blinking lamp 10.";
CM_ SG_ 2358902526 Joystick3Lamp9Cmd "Tells joystick 3 to switch on/off/blinking lamp 9.";
CM_ SG_ 2358902526 Joystick3Lamp8Cmd "Tells joystick 3 to switch on/off/blinking lamp 8.";
CM_ SG_ 2358902526 Joystick3Lamp7Cmd "Tells joystick 3 to switch on/off/blinking lamp 7.";
CM_ SG_ 2358902526 Joystick3Lamp6Cmd "Tells joystick 3 to switch on/off/blinking lamp 6.";
CM_ SG_ 2358902526 Joystick3Lamp5Cmd "Tells joystick 3 to switch on/off/blinking lamp 5.";
CM_ SG_ 2358902526 Joystick3Lamp4Cmd "Tells joystick 3 to switch on/off/blinking lamp 4.";
CM_ SG_ 2358902526 Joystick3Lamp3Cmd "Tells joystick 3 to switch on/off/blinking lamp 3.";
CM_ SG_ 2358902526 Joystick3Lamp2Cmd "Tells joystick 3 to switch on/off/blinking lamp 2.";
CM_ SG_ 2358902526 Joystick3Lamp1Cmd "Tells joystick 3 to switch on/off/blinking lamp 1.";
CM_ SG_ 2358902526 Joystick2Lamp10Cmd "Tells joystick 2 to switch on/off/blinking lamp 10.";
CM_ SG_ 2358902526 Joystick2Lamp9Cmd "Tells joystick 2 to switch on/off/blinking lamp 9.";
CM_ SG_ 2358902526 Joystick2Lamp8Cmd "Tells joystick 2 to switch on/off/blinking lamp 8.";
CM_ SG_ 2358902526 Joystick2Lamp7Cmd "Tells joystick 2 to switch on/off/blinking lamp 7.";
CM_ SG_ 2358902526 Joystick2Lamp6Cmd "Tells joystick 2 to switch on/off/blinking lamp 6.";
CM_ SG_ 2358902526 Joystick2Lamp5Cmd "Tells joystick 2 to switch on/off/blinking lamp 5.";
CM_ SG_ 2358902526 Joystick2Lamp4Cmd "Tells joystick 2 to switch on/off/blinking lamp 4.";
CM_ SG_ 2358902526 Joystick2Lamp3Cmd "Tells joystick 2 to switch on/off/blinking lamp 3.";
CM_ SG_ 2358902526 Joystick2Lamp2Cmd "Tells joystick 2 to switch on/off/blinking lamp 2.";
CM_ SG_ 2358902526 Joystick2Lamp1Cmd "Tells joystick 2 to switch on/off/blinking lamp 1.";
CM_ SG_ 2358902526 Joystick1Lamp10Cmd "Tells joystick 1 to switch on/off/blinking lamp 10.";
CM_ SG_ 2358902526 Joystick1Lamp9Cmd "Tells joystick 1 to switch on/off/blinking lamp 9.";
CM_ SG_ 2358902526 Joystick1Lamp8Cmd "Tells joystick 1 to switch on/off/blinking lamp 8.";
CM_ SG_ 2358902526 Joystick1Lamp7Cmd "Tells joystick 1 to switch on/off/blinking lamp 7.";
CM_ SG_ 2358902526 Joystick1Lamp6Cmd "Tells joystick 1 to switch on/off/blinking lamp 6.";
CM_ SG_ 2358902526 Joystick1Lamp5Cmd "Tells joystick 1 to switch on/off/blinking lamp 5.";
CM_ SG_ 2358902526 Joystick1Lamp4Cmd "Tells joystick 1 to switch on/off/blinking lamp 4.";
CM_ SG_ 2358902526 Joystick1Lamp3Cmd "Tells joystick 1 to switch on/off/blinking lamp 3.";
CM_ SG_ 2358902526 Joystick1Lamp2Cmd "Tells joystick 1 to switch on/off/blinking lamp 2.";
CM_ SG_ 2358902526 Joystick1Lamp1Cmd "Tells joystick 1 to switch on/off/blinking lamp 1.";
CM_ BO_ 2566711550 "Intake Valve Actuation Control";
CM_ SG_ 2566711550 IntkVlvActtnSystmOlPrss2SlndCtrl "Indicates the current command to the solenoid that controls the intake valve actuation system oil pressure 2 valve.";
CM_ SG_ 2566711550 IntkVlvActtnSystmOlPrss1SlndCtrl "Indicates the current command to the solenoid that controls the intake valve actuation system oil pressure 1 valve.";
CM_ BO_ 2633832958 "Ignitor Loop Information";
CM_ SG_ 2633832958 SpecialIgnitorLoop90Resistance "Resistance of Special Ignitor Loop 90.";
CM_ SG_ 2633832958 SpecialIgnitorLoop89Resistance "Resistance of Special Ignitor Loop 89.";
CM_ SG_ 2633832958 SpecialIgnitorLoop88Resistance "Resistance of Special Ignitor Loop 88.";
CM_ SG_ 2633832958 SpecialIgnitorLoop87Resistance "Resistance of Special Ignitor Loop 87.";
CM_ SG_ 2633832958 SpecialIgnitorLoop86Resistance "Resistance of Special Ignitor Loop 86.";
CM_ SG_ 2633832958 SpecialIgnitorLoop85Resistance "Resistance of Special Ignitor Loop 85.";
CM_ SG_ 2633832958 SpecialIgnitorLoop84Resistance "Resistance of Special Ignitor Loop 84.";
CM_ SG_ 2633832958 SpecialIgnitorLoop83Resistance "Resistance of Special Ignitor Loop 83.";
CM_ SG_ 2633832958 SpecialIgnitorLoop82Resistance "Resistance of Special Ignitor Loop 82.";
CM_ SG_ 2633832958 SpecialIgnitorLoop81Resistance "Resistance of Special Ignitor Loop 81.";
CM_ SG_ 2633832958 SpecialIgnitorLoop80Resistance "Resistance of Special Ignitor Loop 80.";
CM_ SG_ 2633832958 SpecialIgnitorLoop79Resistance "Resistance of Special Ignitor Loop 79.";
CM_ SG_ 2633832958 SpecialIgnitorLoop78Resistance "Resistance of Special Ignitor Loop 78.";
CM_ SG_ 2633832958 SpecialIgnitorLoop77Resistance "Resistance of Special Ignitor Loop 77.";
CM_ SG_ 2633832958 SpecialIgnitorLoop76Resistance "Resistance of Special Ignitor Loop 76.";
CM_ SG_ 2633832958 SpecialIgnitorLoop75Resistance "Resistance of Special Ignitor Loop 75.";
CM_ SG_ 2633832958 SpecialIgnitorLoop74Resistance "Resistance of Special Ignitor Loop 74.";
CM_ SG_ 2633832958 SpecialIgnitorLoop73Resistance "Resistance of Special Ignitor Loop 73.";
CM_ SG_ 2633832958 SpecialIgnitorLoop72Resistance "Resistance of Special Ignitor Loop 72.";
CM_ SG_ 2633832958 SpecialIgnitorLoop71Resistance "Resistance of Special Ignitor Loop 71.";
CM_ SG_ 2633832958 SpecialIgnitorLoop70Resistance "Resistance of Special Ignitor Loop 70.";
CM_ SG_ 2633832958 SpecialIgnitorLoop69Resistance "Resistance of Special Ignitor Loop 69.";
CM_ SG_ 2633832958 SpecialIgnitorLoop68Resistance "Resistance of Special Ignitor Loop 68.";
CM_ SG_ 2633832958 SpecialIgnitorLoop67Resistance "Resistance of Special Ignitor Loop 67.";
CM_ SG_ 2633832958 SpecialIgnitorLoop66Resistance "Resistance of Special Ignitor Loop 66.";
CM_ SG_ 2633832958 SpecialIgnitorLoop65Resistance "Resistance of Special Ignitor Loop 65.";
CM_ SG_ 2633832958 SpecialIgnitorLoop64Resistance "Resistance of Special Ignitor Loop 64.";
CM_ SG_ 2633832958 SpecialIgnitorLoop63Resistance "Resistance of Special Ignitor Loop 63.";
CM_ SG_ 2633832958 SpecialIgnitorLoop61Resistance "Resistance of Special Ignitor Loop 61.";
CM_ SG_ 2633832958 SpecialIgnitorLoop60Resistance "Resistance of Special Ignitor Loop 60.";
CM_ SG_ 2633832958 SpecialIgnitorLoop59Resistance "Resistance of Special Ignitor Loop 59.";
CM_ SG_ 2633832958 SpecialIgnitorLoop58Resistance "Resistance of Special Ignitor Loop 58.";
CM_ SG_ 2633832958 SpecialIgnitorLoop57Resistance "Resistance of Special Ignitor Loop 57.";
CM_ SG_ 2633832958 SpecialIgnitorLoop56Resistance "Resistance of Special Ignitor Loop 56.";
CM_ SG_ 2633832958 SpecialIgnitorLoop55Resistance "Resistance of Special Ignitor Loop 55.";
CM_ SG_ 2633832958 SpecialIgnitorLoop54Resistance "Resistance of Special Ignitor Loop 54.";
CM_ SG_ 2633832958 SpecialIgnitorLoop53Resistance "Resistance of Special Ignitor Loop 53.";
CM_ SG_ 2633832958 SpecialIgnitorLoop52Resistance "Resistance of Special Ignitor Loop 52.";
CM_ SG_ 2633832958 SpecialIgnitorLoop51Resistance "Resistance of Special Ignitor Loop 51.";
CM_ SG_ 2633832958 SpecialIgnitorLoop50Resistance "Resistance of Special Ignitor Loop 50.";
CM_ SG_ 2633832958 SpecialIgnitorLoop49Resistance "Resistance of Special Ignitor Loop 49.";
CM_ SG_ 2633832958 SpecialIgnitorLoop48Resistance "Resistance of Special Ignitor Loop 48.";
CM_ SG_ 2633832958 SpecialIgnitorLoop47Resistance "Resistance of Special Ignitor Loop 47.";
CM_ SG_ 2633832958 SpecialIgnitorLoop46Resistance "Resistance of Special Ignitor Loop 46.";
CM_ SG_ 2633832958 SpecialIgnitorLoop45Resistance "Resistance of Special Ignitor Loop 45.";
CM_ SG_ 2633832958 SpecialIgnitorLoop44Resistance "Resistance of Special Ignitor Loop 44.";
CM_ SG_ 2633832958 SpecialIgnitorLoop43Resistance "Resistance of Special Ignitor Loop 43.";
CM_ SG_ 2633832958 SpecialIgnitorLoop42Resistance "Resistance of Special Ignitor Loop 42.";
CM_ SG_ 2633832958 SpecialIgnitorLoop41Resistance "Resistance of Special Ignitor Loop 41.";
CM_ SG_ 2633832958 SpecialIgnitorLoop40Resistance "Resistance of Special Ignitor Loop 40.";
CM_ SG_ 2633832958 SpecialIgnitorLoop39Resistance "Resistance of Special Ignitor Loop 39.";
CM_ SG_ 2633832958 SpecialIgnitorLoop38Resistance "Resistance of Special Ignitor Loop 38.";
CM_ SG_ 2633832958 SpecialIgnitorLoop37Resistance "Resistance of Special Ignitor Loop 37.";
CM_ SG_ 2633832958 SpecialIgnitorLoop36Resistance "Resistance of Special Ignitor Loop 36.";
CM_ SG_ 2633832958 SpecialIgnitorLoop35Resistance "Resistance of Special Ignitor Loop 35.";
CM_ SG_ 2633832958 SpecialIgnitorLoop34Resistance "Resistance of Special Ignitor Loop 34.";
CM_ SG_ 2633832958 SpecialIgnitorLoop33Resistance "Resistance of Special Ignitor Loop 33.";
CM_ SG_ 2633832958 SpecialIgnitorLoop32Resistance "Resistance of Special Ignitor Loop 32.";
CM_ SG_ 2633832958 SpecialIgnitorLoop31Resistance "Resistance of Special Ignitor Loop 31.";
CM_ SG_ 2633832958 SpecialIgnitorLoop30Resistance "Resistance of Special Ignitor Loop 30.";
CM_ SG_ 2633832958 SpecialIgnitorLoop29Resistance "Resistance of Special Ignitor Loop 29.";
CM_ SG_ 2633832958 SpecialIgnitorLoop28Resistance "Resistance of Special Ignitor Loop 28.";
CM_ SG_ 2633832958 SpecialIgnitorLoop27Resistance "Resistance of Special Ignitor Loop 27.";
CM_ SG_ 2633832958 SpecialIgnitorLoop26Resistance "Resistance of Special Ignitor Loop 26.";
CM_ SG_ 2633832958 SpecialIgnitorLoop25Resistance "Resistance of Special Ignitor Loop 25.";
CM_ SG_ 2633832958 SpecialIgnitorLoop24Resistance "Resistance of Special Ignitor Loop 24.";
CM_ SG_ 2633832958 SpecialIgnitorLoop23Resistance "Resistance of Special Ignitor Loop 23.";
CM_ SG_ 2633832958 SpecialIgnitorLoop22Resistance "Resistance of Special Ignitor Loop 22.";
CM_ SG_ 2633832958 SpecialIgnitorLoop21Resistance "Resistance of Special Ignitor Loop 21.";
CM_ SG_ 2633832958 SpecialIgnitorLoop20Resistance "Resistance of Special Ignitor Loop 20.";
CM_ SG_ 2633832958 SpecialIgnitorLoop19Resistance "Resistance of Special Ignitor Loop 19.";
CM_ SG_ 2633832958 SpecialIgnitorLoop18Resistance "Resistance of Special Ignitor Loop 18.";
CM_ SG_ 2633832958 SpecialIgnitorLoop17Resistance "Resistance of Special Ignitor Loop 17.";
CM_ SG_ 2633832958 SpecialIgnitorLoop16Resistance "Resistance of Special Ignitor Loop 16.";
CM_ SG_ 2633832958 SpecialIgnitorLoop15Resistance "Resistance of Special Ignitor Loop 15.";
CM_ SG_ 2633832958 SpecialIgnitorLoop14Resistance "Resistance of Special Ignitor Loop 14.";
CM_ SG_ 2633832958 SpecialIgnitorLoop13Resistance "Resistance of Special Ignitor Loop 13.";
CM_ SG_ 2633832958 SpecialIgnitorLoop12Resistance "Resistance of Special Ignitor Loop 12.";
CM_ SG_ 2633832958 SpecialIgnitorLoop11Resistance "Resistance of Special Ignitor Loop 11.";
CM_ SG_ 2633832958 SpecialIgnitorLoop10Resistance "Resistance of Special Ignitor Loop 10.";
CM_ SG_ 2633832958 SpecialIgnitorLoop9Resistance "Resistance of Special Ignitor Loop 9.";
CM_ SG_ 2633832958 SpecialIgnitorLoop8Resistance "Resistance of Special Ignitor Loop 8.";
CM_ SG_ 2633832958 SpecialIgnitorLoop7Resistance "Resistance of Special Ignitor Loop 7.";
CM_ SG_ 2633832958 SpecialIgnitorLoop6Resistance "Resistance of Special Ignitor Loop 6.";
CM_ SG_ 2633832958 SpecialIgnitorLoop5Resistance "Resistance of Special Ignitor Loop 5.";
CM_ SG_ 2633832958 SpecialIgnitorLoop4Resistance "Resistance of Special Ignitor Loop 4.";
CM_ SG_ 2633832958 SpecialIgnitorLoop3Resistance "Resistance of Special Ignitor Loop 3.";
CM_ SG_ 2633832958 SpecialIgnitorLoop2Resistance "Resistance of Special Ignitor Loop 2.";
CM_ SG_ 2633832958 SpecialIgnitorLoop1Resistance "Resistance of Special Ignitor Loop 1.";
CM_ SG_ 2633832958 SdBgIgnitorLoop2RightResistance "Resistance of Side Bag Ignitor Loop 2 - Right.";
CM_ SG_ 2633832958 SdBgIgnitorLoop1RightResistance "Resistance of Side Bag Ignitor Loop 1 - Right.";
CM_ SG_ 2633832958 SdBagIgnitorLoop2LeftResistance "Resistance of Side Bag Ignitor Loop 2 - Left.";
CM_ SG_ 2633832958 SdBagIgnitorLoop1LeftResistance "Resistance of Side Bag Ignitor Loop 1 - Left.";
CM_ SG_ 2633832958 PssngrBltTnsnrIgntrLpResistance "Resistance of Passenger Belt Tensioner Ignitor Loop 1st Stage.";
CM_ SG_ 2633832958 DrvrBltTnsnrIgntrLoopResistance "Resistance of Driver Belt Tensioner Ignitor Loop 1st Stage.";
CM_ SG_ 2633832958 PssngrArbgIgntrLp2ndStgRsstance "Resistance of Passenger Airbag Ignitor Loop 2nd Stage.";
CM_ SG_ 2633832958 DrvrArbgIgntrLp2ndStgResistance "Resistance of Driver Airbag Ignitor Loop 2nd Stage.";
CM_ SG_ 2633832958 PssngrArbgIgntrLp1stStgRsstance "Resistance of Passenger Airbag Ignitor Loop 1st Stage.";
CM_ SG_ 2633832958 DrvrArbgIgntrLp1stStgResistance "Resistance of Driver Airbag Ignitor Loop 1st Stage.";
CM_ BO_ 2566719998 "High Resolution Fuel Consumption (Liquid)";
CM_ SG_ 2566719998 HighResolutionEngTotalFuelUsed "Accumulated amount of fuel used during vehicle operation.";
CM_ SG_ 2566719998 HighResolutionEngTripFuel "Fuel consumed during all or part of a journey.";
CM_ BO_ 2565877502 "Engine Turbocharger Wastegate Actuator Control Command";
CM_ SG_ 2565877502 EngTurboWastegateActuator2Cmd "The command to a Turbocharger Wastegate actuator 2, normalized to percent, where 0% nominally represents fully";
CM_ SG_ 2565877502 EngTurboWastegateActuator1Cmd "The ccommand to a Turbocharger Wastegate actuator 1, normalized to percent, where 0% nominally represents fully";
CM_ BO_ 2566713854 "Engine Turbocharger Wastegate Actuator Information";
CM_ SG_ 2566713854 EngTrbWstgtActtr2OprationStatus "Used to identify the status of Engine Turbocharger Wastegate Actuator 2";
CM_ SG_ 2566713854 EngTrbWstgtActtr1OprationStatus "Used to identify the status of Engine Turbocharger Wastegate Actuator 1";
CM_ SG_ 2566713854 EngTrbWstgteActuator2TempStatus "Used to identify the status of the Engine Turbocharger Wastegate Actuator 2 drive circuitry temperature.";
CM_ SG_ 2566713854 EngTrbWstgtActtr2PreliminaryFMI "Used to identify the applicable J1939-73 FMI detected in the Engine Turbocharger Wastegate Actuator 2 by the";
CM_ BO_ 2566714366 "Engine Turbocharger Compressor Bypass Information";
CM_ SG_ 2566714366 EngTrbCmprssrBypssActtr2OprtnStt "Used to identify the status of Engine Turbocharger Compressor Bypass Actuator 2";
CM_ SG_ 2566714366 EngTrbCmprssrBypssActtr1OprtnStt "Used to identify the status of Engine Turbocharger Compressor Bypass Actuator 1";
CM_ SG_ 2566714366 EngTrbCmprssrBypssActtr2TmpStts "Used to identify the status of the Engine Turbocharger Compresssor Bypass Actuator 2 drive circuitry temperature.";
CM_ SG_ 2566714366 EngTrbCmprssrBypssActtr2PrlmnryF "Used to identify the applicable J1939-73 FMI detected in the Engine Turbocharger Compressor Bypass Actuator 1 by the";
CM_ SG_ 2566714366 EngDsrdTrbCmprssrBypssActtr2Pos "The desired position of the Engine Turbocharger Compressor Bypass actuator 2 by the engine ECM, where 0%";
CM_ SG_ 2566714366 EngTrbCmprssrBypassActuator2Pos "Measures the position of the turbocharger compressor bypass actuator 2, where 0% represents bypass fully closed and";
CM_ BO_ 2566714110 "Engine Fuel/Throttle Valve Information";
CM_ SG_ 2566714110 EngFuelValve2OperationStatus "Used to identify the status of Engine Fuel Valve 2";
CM_ SG_ 2566714110 EngFuelValve1OperationStatus "Used to identify the status of Engine Fuel Valve 1";
CM_ SG_ 2566714110 EngThrttleValve2OperationStatus "Used to identify the status of Engine Throttle Valve 2";
CM_ SG_ 2566714110 EngThrttleValve1OperationStatus "Used to identify the status of Engine Throttle Valve 1";
CM_ SG_ 2566714110 EngFuelValve2TempStatus "Used to identify the status of the Engine Fuel valve 2 drive circuitry temperature.";
CM_ SG_ 2566714110 EngFuelValve2PreliminaryFMI "Used to identify the applicable J1939-73 FMI detected in the Engine Fuel Valve 2 by the manufacturers software.";
CM_ SG_ 2566714110 EngFuelValve1TempStatus "Used to identify the status of the Engine Fuel valve 1 drive circuitry temperature.";
CM_ SG_ 2566714110 EngFuelValve1PreliminaryFMI "Used to identify the applicable J1939-73 FMI detected in the Engine Fuel Valve 1 by the manufacturers software.";
CM_ SG_ 2566714110 EngThrottleValve2TempStatus "Used to identify the status of the Engine Throttle Valve 2 drive circuitry temperature.";
CM_ SG_ 2566714110 EngThrottleValve2PreliminaryFMI "Used to identify the applicable J1939-73 FMI detected in the Engine Throttle Valve 2 by the manufacturers software.";
CM_ SG_ 2566714110 EngDesiredThrottleValve2Pos "The desired position of the Throttle valve 2 that is regulating the fluid, usually air/fuel mixture to the engine as";
CM_ SG_ 2566714110 EngThrottleValve1TempStatus "Used to identify the status of the Engine Throttle Valve 1 drive circuitry temperature.";
CM_ SG_ 2566714110 EngThrottleValve1PreliminaryFMI "Used to identify the appplicable J1939-73 FMI detected in the Engine Throttle Valve 1 by the manufacturers software.";
CM_ SG_ 2566714110 EngDesiredThrottleValve1Pos "The desired position of the Throttle valve 1 that is regulating the fluid, usually air/fuel mixture to the engine as";
CM_ BO_ 2566717438 "Engine Temperature 5";
CM_ SG_ 2566717438 EngExhstGsRcrcltn2MxrIntakeTemp "The temperature of the EGR gas entering the intake of EGR2 system mixer.";
CM_ SG_ 2566717438 EngExhaustGasRecirculation2Temp "Temperature of Recirculated Exhaust Gas of EGR2";
CM_ BO_ 2633828606 "Engine oil message";
CM_ SG_ 2633828606 EngOilRelativeDielectricity "Engine oil relative dielectricity used to describe the engine oil quality.";
CM_ SG_ 2633828606 EngOilDensity "Density of the engine oil";
CM_ SG_ 2633828606 EngOilViscosity "Dynamic viscosity of the engine oil";
CM_ BO_ 2499607550 "Engine Manifold Actuator Position";
CM_ SG_ 2499607550 EngExhstMnfldBnk2FlwBlncVlvActtr "Actual percentage of maximum Engine Manifold Bank 2 Balance valve opening.";
CM_ SG_ 2499607550 EngExhstMnfldBnk1FlwBlncVlvActtr "Actual percentage of maximum Engine Exhaust Manifold Bank 1 Balance valve opening.";
CM_ BO_ 2633825534 "Engine Manifold Actuator Control";
CM_ SG_ 2633825534 EngExhstMnfldBnk2FlwBlncVlv_0000 "Commanded percentage of maximum Engine Ehaust Manifold Bank 2 Balance valve opening.";
CM_ SG_ 2633825534 EngExhstMnfldBnk1FlwBlncVlv_0000 "Commanded percentage of maximum Engine Exhaust Manifold Bank 1 Balance valve opening.";
CM_ BO_ 2365400574 "Extended Joystick Message 9";
CM_ SG_ 2365400574 Jystck9GripXAxisDetentPosStatus "Reports when the current joystick grip position is in the detent position for that axis of travel.";
CM_ SG_ 2365400574 Jystck9GripYAxisDetentPosStatus "Reports when the current joystick grip position is in the detent position for that axis of travel.";
CM_ SG_ 2365400574 Jystck9ThetaAxisDetentPosStatus "Reports when the current joystick position is in the detent position for that axis of travel.";
CM_ SG_ 2365400574 Joystick9ThetaAxisPos "The position of the joystick in the relative motion of travel from the neutral position.";
CM_ SG_ 2365400574 Jystck9ThtAxsClckwsPstvPsStatus "Reports when the current joystick position is on the positive travel side (forward, right, clockwise, up) relative to the";
CM_ SG_ 2365400574 Jystck9ThtAxsCntrClckwsNgtvPsStt "Reports when the current joystick position is on the negative travel side (back, left, counterclockwise, down) relative to the";
CM_ SG_ 2365400574 Jystck9ThtaAxisNeutralPosStatus "Reports when the current joystick position is in the neutral position for that axis of travel.";
CM_ SG_ 2365400574 Joystick9GripYAxisPos "The position of the joystick grip in the relative motion of travel from the neutral position.";
CM_ SG_ 2365400574 Jystck9GrpYAxsLvrFrwrdPstvPsStts "Reports when the current joystick grip position is on the positive travel side (forward, right, clockwise, up) relative to the";
CM_ SG_ 2365400574 Jystck9GrpYAxsLvrBckNgtvPsSttus "Reports when the current joystick grip position is on the negative travel side (back, left, counterclockwise, down) relative";
CM_ SG_ 2365400574 Jystck9GrpYAxisNeutralPosStatus "Reports when the current joystick grip position is in the neutral position for that axis of travel.";
CM_ SG_ 2365400574 Joystick9GripXAxisPos "The position of the joystick grip in the relative motion of travel from the neutral position.";
CM_ SG_ 2365400574 Jystck9GrpXAxsLvrRghtPstvPsStts "Reports when the current joystick grip position is on the positive travel side (forward, right, clockwise, up) relative to the";
CM_ SG_ 2365400574 Jystck9GrpXAxsLvrLftNgtvPsSttus "Reports when the current joystick grip position is on the negative travel side (back, left, counterclockwise, down) relative";
CM_ SG_ 2365400574 Jystck9GrpXAxisNeutralPosStatus "Reports when the current joystick grip position is in the neutral position for that axis of travel.";
CM_ BO_ 2365401086 "Extended Joystick Message 8";
CM_ SG_ 2365401086 Jystck8GripXAxisDetentPosStatus "Reports when the current joystick grip position is in the detent position for that axis of travel.";
CM_ SG_ 2365401086 Jystck8GripYAxisDetentPosStatus "Reports when the current joystick grip position is in the detent position for that axis of travel.";
CM_ SG_ 2365401086 Jystck8ThetaAxisDetentPosStatus "Reports when the current joystick position is in the detent position for that axis of travel.";
CM_ SG_ 2365401086 Joystick8ThetaAxisPos "The position of the joystick in the relative motion of travel from the neutral position.";
CM_ SG_ 2365401086 Jystck8ThtAxsClckwsPstvPsStatus "Reports when the current joystick position is on the positive travel side (forward, right, clockwise, up) relative to the";
CM_ SG_ 2365401086 Jystck8ThtAxsCntrClckwsNgtvPsStt "Reports when the current joystick position is on the negative travel side (back, left, counterclockwise, down) relative to the";
CM_ SG_ 2365401086 Jystck8ThtaAxisNeutralPosStatus "Reports when the current joystick position is in the neutral position for that axis of travel.";
CM_ SG_ 2365401086 Joystick8GripYAxisPos "The position of the joystick grip in the relative motion of travel from the neutral position.";
CM_ SG_ 2365401086 Jystck8GrpYAxsLvrFrwrdPstvPsStts "Reports when the current joystick grip position is on the positive travel side (forward, right, clockwise, up) relative to the";
CM_ SG_ 2365401086 Jystck8GrpYAxsLvrBckNgtvPsSttus "Reports when the current joystick grip position is on the negative travel side (back, left, counterclockwise, down) relative";
CM_ SG_ 2365401086 Jystck8GrpYAxisNeutralPosStatus "Reports when the current joystick grip position is in the neutral position for that axis of travel.";
CM_ SG_ 2365401086 Joystick8GripXAxisPos "The position of the joystick grip in the relative motion of travel from the neutral position.";
CM_ SG_ 2365401086 Jystck8GrpXAxsLvrRghtPstvPsStts "Reports when the current joystick grip position is on the positive travel side (forward, right, clockwise, up) relative to the";
CM_ SG_ 2365401086 Jystck8GrpXAxsLvrLftNgtvPsSttus "Reports when the current joystick grip position is on the negative travel side (back, left, counterclockwise, down) relative";
CM_ SG_ 2365401086 Jystck8GrpXAxisNeutralPosStatus "Reports when the current joystick grip position is in the neutral position for that axis of travel.";
CM_ BO_ 2365401598 "Extended Joystick Message 7";
CM_ SG_ 2365401598 Jystck7GripXAxisDetentPosStatus "Reports when the current joystick grip position is in the detent position for that axis of travel.";
CM_ SG_ 2365401598 Jystck7GripYAxisDetentPosStatus "Reports when the current joystick grip position is in the detent position for that axis of travel.";
CM_ SG_ 2365401598 Jystck7ThetaAxisDetentPosStatus "Reports when the current joystick position is in the detent position for that axis of travel.";
CM_ SG_ 2365401598 Joystick7ThetaAxisPos "The position of the joystick in the relative motion of travel from the neutral position.";
CM_ SG_ 2365401598 Jystck7ThtAxsClckwsPstvPsStatus "Reports when the current joystick position is on the positive travel side (forward, right, clockwise, up) relative to the";
CM_ SG_ 2365401598 Jystck7ThtAxsCntrClckwsNgtvPsStt "Reports when the current joystick position is on the negative travel side (back, left, counterclockwise, down) relative to the";
CM_ SG_ 2365401598 Jystck7ThtaAxisNeutralPosStatus "Reports when the current joystick position is in the neutral position for that axis of travel.";
CM_ SG_ 2365401598 Joystick7GripYAxisPos "The position of the joystick grip in the relative motion of travel from the neutral position.";
CM_ SG_ 2365401598 Jystck7GrpYAxsLvrFrwrdPstvPsStts "Reports when the current joystick grip position is on the positive travel side (forward, right, clockwise, up) relative to the";
CM_ SG_ 2365401598 Jystck7GrpYAxsLvrBckNgtvPsSttus "Reports when the current joystick grip position is on the negative travel side (back, left, counterclockwise, down) relative";
CM_ SG_ 2365401598 Jystck7GrpYAxisNeutralPosStatus "Reports when the current joystick grip position is in the neutral position for that axis of travel.";
CM_ SG_ 2365401598 Joystick7GripXAxisPos "The position of the joystick grip in the relative motion of travel from the neutral position.";
CM_ SG_ 2365401598 Jystck7GrpXAxsLvrRghtPstvPsStts "Reports when the current joystick grip position is on the positive travel side (forward, right, clockwise, up) relative to the";
CM_ SG_ 2365401598 Jystck7GrpXAxsLvrLftNgtvPsSttus "Reports when the current joystick grip position is on the negative travel side (back, left, counterclockwise, down) relative";
CM_ SG_ 2365401598 Jystck7GrpXAxisNeutralPosStatus "Reports when the current joystick grip position is in the neutral position for that axis of travel.";
CM_ BO_ 2365402110 "Extended Joystick Message 6";
CM_ SG_ 2365402110 Jystck6GripXAxisDetentPosStatus "Reports when the current joystick grip position is in the detent position for that axis of travel.";
CM_ SG_ 2365402110 Jystck6GripYAxisDetentPosStatus "Reports when the current joystick grip position is in the detent position for that axis of travel.";
CM_ SG_ 2365402110 Jystck6ThetaAxisDetentPosStatus "Reports when the current joystick position is in the detent position for that axis of travel.";
CM_ SG_ 2365402110 Joystick6ThetaAxisPos "The position of the joystick in the relative motion of travel from the neutral position.";
CM_ SG_ 2365402110 Jystck6ThtAxsClckwsPstvPsStatus "Reports when the current joystick position is on the positive travel side (forward, right, clockwise, up) relative to the";
CM_ SG_ 2365402110 Jystck6ThtAxsCntrClckwsNgtvPsStt "Reports when the current joystick position is on the negative travel side (back, left, counterclockwise, down) relative to the";
CM_ SG_ 2365402110 Jystck6ThtaAxisNeutralPosStatus "Reports when the current joystick position is in the neutral position for that axis of travel.";
CM_ SG_ 2365402110 Joystick6GripYAxisPos "The position of the joystick grip in the relative motion of travel from the neutral position.";
CM_ SG_ 2365402110 Jystck6GrpYAxsLvrFrwrdPstvPsStts "Reports when the current joystick grip position is on the positive travel side (forward, right, clockwise, up) relative to the";
CM_ SG_ 2365402110 Jystck6GrpYAxsLvrBckNgtvPsSttus "Reports when the current joystick grip position is on the negative travel side (back, left, counterclockwise, down) relative";
CM_ SG_ 2365402110 Jystck6GrpYAxisNeutralPosStatus "Reports when the current joystick grip position is in the neutral position for that axis of travel.";
CM_ SG_ 2365402110 Joystick6GripXAxisPos "The position of the joystick grip in the relative motion of travel from the neutral position.";
CM_ SG_ 2365402110 Jystck6GrpXAxsLvrRghtPstvPsStts "Reports when the current joystick grip position is on the positive travel side (forward, right, clockwise, up) relative to the";
CM_ SG_ 2365402110 Jystck6GrpXAxsLvrLftNgtvPsSttus "Reports when the current joystick grip position is on the negative travel side (back, left, counterclockwise, down) relative";
CM_ SG_ 2365402110 Jystck6GrpXAxisNeutralPosStatus "Reports when the current joystick grip position is in the neutral position for that axis of travel.";
CM_ BO_ 2365402622 "Extended Joystick Message 5";
CM_ SG_ 2365402622 Jystck5GripXAxisDetentPosStatus "Reports when the current joystick grip position is in the detent position for that axis of travel.";
CM_ SG_ 2365402622 Jystck5GripYAxisDetentPosStatus "Reports when the current joystick grip position is in the detent position for that axis of travel.";
CM_ SG_ 2365402622 Jystck5ThetaAxisDetentPosStatus "Reports when the current joystick position is in the detent position for that axis of travel.";
CM_ SG_ 2365402622 Joystick5ThetaAxisPos "The position of the joystick in the relative motion of travel from the neutral position.";
CM_ SG_ 2365402622 Jystck5ThtAxsClckwsPstvPsStatus "Reports when the current joystick position is on the positive travel side (forward, right, clockwise, up) relative to the";
CM_ SG_ 2365402622 Jystck5ThtAxsCntrClckwsNgtvPsStt "Reports when the current joystick position is on the negative travel side (back, left, counterclockwise, down) relative to the";
CM_ SG_ 2365402622 Jystck5ThtaAxisNeutralPosStatus "Reports when the current joystick position is in the neutral position for that axis of travel.";
CM_ SG_ 2365402622 Joystick5GripYAxisPos "The position of the joystick grip in the relative motion of travel from the neutral position.";
CM_ SG_ 2365402622 Jystck5GrpYAxsLvrFrwrdPstvPsStts "Reports when the current joystick grip position is on the positive travel side (forward, right, clockwise, up) relative to the";
CM_ SG_ 2365402622 Jystck5GrpYAxsLvrBckNgtvPsSttus "Reports when the current joystick grip position is on the negative travel side (back, left, counterclockwise, down) relative";
CM_ SG_ 2365402622 Jystck5GrpYAxisNeutralPosStatus "Reports when the current joystick grip position is in the neutral position for that axis of travel.";
CM_ SG_ 2365402622 Joystick5GripXAxisPos "The position of the joystick grip in the relative motion of travel from the neutral position.";
CM_ SG_ 2365402622 Jystck5GrpXAxsLvrRghtPstvPsStts "Reports when the current joystick grip position is on the positive travel side (forward, right, clockwise, up) relative to the";
CM_ SG_ 2365402622 Jystck5GrpXAxsLvrLftNgtvPsSttus "Reports when the current joystick grip position is on the negative travel side (back, left, counterclockwise, down) relative";
CM_ SG_ 2365402622 Jystck5GrpXAxisNeutralPosStatus "Reports when the current joystick grip position is in the neutral position for that axis of travel.";
CM_ BO_ 2365403134 "Extended Joystick Message 4";
CM_ SG_ 2365403134 Jystck4GripXAxisDetentPosStatus "Reports when the current joystick grip position is in the detent position for that axis of travel.";
CM_ SG_ 2365403134 Jystck4GripYAxisDetentPosStatus "Reports when the current joystick grip position is in the detent position for that axis of travel.";
CM_ SG_ 2365403134 Jystck4ThetaAxisDetentPosStatus "Reports when the current joystick position is in the detent position for that axis of travel.";
CM_ SG_ 2365403134 Joystick4ThetaAxisPos "The position of the joystick in the relative motion of travel from the neutral position.";
CM_ SG_ 2365403134 Jystck4ThtAxsClckwsPstvPsStatus "Reports when the current joystick position is on the positive travel side (forward, right, clockwise, up) relative to the";
CM_ SG_ 2365403134 Jystck4ThtAxsCntrClckwsNgtvPsStt "Reports when the current joystick position is on the negative travel side (back, left, counterclockwise, down) relative to the";
CM_ SG_ 2365403134 Jystck4ThtaAxisNeutralPosStatus "Reports when the current joystick position is in the neutral position for that axis of travel.";
CM_ SG_ 2365403134 Joystick4GripYAxisPos "The position of the joystick grip in the relative motion of travel from the neutral position.";
CM_ SG_ 2365403134 Jystck4GrpYAxsLvrFrwrdPstvPsStts "Reports when the current joystick grip position is on the positive travel side (forward, right, clockwise, up) relative to the";
CM_ SG_ 2365403134 Jystck4GrpYAxsLvrBckNgtvPsSttus "Reports when the current joystick grip position is on the negative travel side (back, left, counterclockwise, down) relative";
CM_ SG_ 2365403134 Jystck4GrpYAxisNeutralPosStatus "Reports when the current joystick grip position is in the neutral position for that axis of travel.";
CM_ SG_ 2365403134 Joystick4GripXAxisPos "The position of the joystick grip in the relative motion of travel from the neutral position.";
CM_ SG_ 2365403134 Jystck4GrpXAxsLvrRghtPstvPsStts "Reports when the current joystick grip position is on the positive travel side (forward, right, clockwise, up) relative to the";
CM_ SG_ 2365403134 Jystck4GrpXAxsLvrLftNgtvPsSttus "Reports when the current joystick grip position is on the negative travel side (back, left, counterclockwise, down) relative";
CM_ SG_ 2365403134 Jystck4GrpXAxisNeutralPosStatus "Reports when the current joystick grip position is in the neutral position for that axis of travel.";
CM_ BO_ 2365400062 "Extended Joystick Message 10";
CM_ SG_ 2365400062 Jystck10GrpXAxisDetentPosStatus "Reports when the current joystick grip position is in the detent position for that axis of travel.";
CM_ SG_ 2365400062 Jystck10GrpYAxisDetentPosStatus "Reports when the current joystick grip position is in the detent position for that axis of travel.";
CM_ SG_ 2365400062 Jystck10ThtaAxisDetentPosStatus "Reports when the current joystick position is in the detent position for that axis of travel.";
CM_ SG_ 2365400062 Joystick10ThetaAxisPos "The position of the joystick in the relative motion of travel from the neutral position.";
CM_ SG_ 2365400062 Jystck10ThtAxsClckwsPstvPsSttus "Reports when the current joystick position is on the positive travel side (forward, right, clockwise, up) relative to the";
CM_ SG_ 2365400062 Jystck10ThtAxsCntrClckwsNgtvPsSt "Reports when the current joystick position is on the negative travel side (back, left, counterclockwise, down) relative to the";
CM_ SG_ 2365400062 Jystck10ThtAxisNeutralPosStatus "Reports when the current joystick position is in the neutral position for that axis of travel.";
CM_ SG_ 2365400062 Joystick10GripYAxisPos "The position of the joystick grip in the relative motion of travel from the neutral position.";
CM_ SG_ 2365400062 Jystck10GrpYAxsLvrFrwrdPstvPsStt "Reports when the current joystick grip position is on the positive travel side (forward, right, clockwise, up) relative to the";
CM_ SG_ 2365400062 Jystck10GrpYAxsLvrBckNgtvPsStts "Reports when the current joystick grip position is on the negative travel side (back, left, counterclockwise, down) relative";
CM_ SG_ 2365400062 Jystck10GrpYAxsNeutralPosStatus "Reports when the current joystick grip position is in the neutral position for that axis of travel.";
CM_ SG_ 2365400062 Joystick10GripXAxisPos "The position of the joystick grip in the relative motion of travel from the neutral position.";
CM_ SG_ 2365400062 Jystck10GrpXAxsLvrRghtPstvPsStts "Reports when the current joystick grip position is on the positive travel side (forward, right, clockwise, up) relative to the";
CM_ SG_ 2365400062 Jystck10GrpXAxsLvrLftNgtvPsStts "Reports when the current joystick grip position is on the negative travel side (back, left, counterclockwise, down) relative";
CM_ SG_ 2365400062 Jystck10GrpXAxsNeutralPosStatus "Reports when the current joystick grip position is in the neutral position for that axis of travel.";
CM_ BO_ 2566713598 "Engine Fuel/lube systems 2";
CM_ SG_ 2566713598 EngFuelFilterIntakeAbsPress "Absolute pressure of fuel at the intake of the fuel filter (suction side) located between the fuel tank and the fuel supply";
CM_ BO_ 2499604478 "Engine Fluid/Pressure 11";
CM_ SG_ 2499604478 EngExhstGsRcrcltn1IntkeAbsPress "EGR intake absolute pressure measured before the EGR 1 valve.";
CM_ BO_ 2499608830 "Engine Fluid/Pressure 10";
CM_ SG_ 2499608830 EngExhstGsRcrcltn2IntkeAbsPress "EGR intake absolute pressure measured before the EGR 2 valve.";
CM_ SG_ 2499608830 EngExhstGsRcrcltn2OtletAbsPress "Absolute Pressure immediately after the EGR2 valve";
CM_ SG_ 2499608830 EngExhstGsRcrcltion2IntakePress "EGR2 intake gauge pressure is measured after EGR2 cooler and before EGR2 valve";
CM_ SG_ 2499608830 EngExhstGsRcrculation2DiffPress "Differential Pressure across the Exhaust Gas Recirculation 2 (EGR2) system.";
CM_ BO_ 2432499198 "Electronic Engine Controller 9";
CM_ SG_ 2432499198 CmdedEngFuelInjectionCtrlPress "Provides the commanded set point value for the engine fuel injection control pressure.";
CM_ SG_ 2432499198 CmdedEngFuelRailPress "Provides the commanded set point value for the engine fuel rail pressure";
CM_ SG_ 2432499198 EngExhstGsRcrculation2Valve2Pos "The position of the second exhaust gas recirculation valve of EGR 2 expressed as a percentage of full travel.";
CM_ SG_ 2432499198 EngExhstGsRcirculation2ValvePos "Position of EGR2 valve expressed as a percentage of full travel.";
CM_ BO_ 2633825022 "Electronic Engine Controller 11";
CM_ SG_ 2633825022 EngExhstGsRcrclation2Valve2Ctrl "Desired percentage of maximum Exhaust Gas Recirculation 2 (EGR2) valve 2 opening.";
CM_ SG_ 2633825022 EngExhstGsRcrculation2ValveCtrl "Desired percentage of maximum Exhaust Gas Recirculation 2 (EGR2) valve opening.";
CM_ BO_ 2633826046 "Electronic Engine Controller 10";
CM_ SG_ 2633826046 EGR2CoolerBypassActuatorPos "EGR2 Cooler Bypass Actuator position, where 0% = Fully Closed (no gas flowing through the bypass), and 100% = Fully";
CM_ SG_ 2633826046 EngExhstGsRcrcltn2ClrEfficiency "Exhaust Gas Recirculation 2 cooler efficiency is an indication of the cooler's ability to reduce the temperature of the";
CM_ SG_ 2633826046 EngExhstGsRcrcltn2ClrIntkGsAbsPr "Exhaust Gas Recirculation 2 gas absolute pressure is measured at EGR2 cooler intake.";
CM_ SG_ 2633826046 EngExhstGsRcrcltn2ClrIntakeTemp "Exhaust Gas Recirculation 2 (EGR2) Temperature measured at EGR2 cooler intake.";
CM_ BO_ 2566711294 "Engine Configuration 3";
CM_ SG_ 2566711294 EngFrctnPrcntTorqueAtIdlePoint7 "The static portion of the friction torque at speed point 7 (SPN 533) of the engine torque map in the engine configuration";
CM_ SG_ 2566711294 EngFrctnPrcntTorqueAtIdlePoint6 "For engine configuration map modes 1 and 2, this is the static portion of the friction torque at speed point 6 (SPN 532) of";
CM_ SG_ 2566711294 EngFrctnPrcntTorqueAtIdlePoint5 "The static portion of the friction torque at speed point 5 (SPN 531) of the engine torque map in the engine configuration";
CM_ SG_ 2566711294 EngFrctnPrcntTorqueAtIdlePoint4 "The static portion of the friction torque at speed point 4 (SPN 530) of the engine torque map in the engine configuration";
CM_ SG_ 2566711294 EngFrctnPrcntTorqueAtIdlePoint3 "The static portion of the friction torque at speed point 3 (SPN 529) of the engine torque map in the engine configuration";
CM_ SG_ 2566711294 EngFrctnPrcntTorqueAtIdlePoint2 "The static portion of the friction torque at speed point 2 (SPN 528) of the engine torque map in the engine configuration";
CM_ SG_ 2566711294 EngFrctnPrcntTorqueAtIdlePoint1 "The static portion of the friction torque at speed point 1 (SPN 188) of the engine torque map in the engine configuration";
CM_ BO_ 2566749438 "Diesel Particulate Filter Control 1";
CM_ SG_ 2566749438 DslPrtcltFltrActvRgnrtnFrcdStts "Indicates the forced execution status of diesel particulate filter regeneration.";
CM_ SG_ 2566749438 ExhaustSystemHighTempLampCmd "Command to control the exhaust system high temperature lamp.";
CM_ SG_ 2566749438 DslPrtcltFltrAtmtcActvRgnrtnIntt "Indicates the configuration of diesel particulate filter active regeneration automatic initiation.";
CM_ SG_ 2566749438 DslPrtcltFltrActvRgnrtnInhbtdDTV "Speed";
CM_ SG_ 2566749438 DslPrtcltFltrActvRgnrtnInhbtdDTE "Indicates the state of diesel particulate filter active regeneration inhibition due to the engine not being warmed up.";
CM_ SG_ 2566749438 DslPrtcltFltrActvRgnrtnInhbtdDTP "Indicates the state of diesel particulate filter active regeneration inhibition due to a permanent system lockout.";
CM_ SG_ 2566749438 DslPrtcltFltrActvRgnrtnInhbtdDTT "Indicates the state of diesel particulate filter active regeneration inhibition due to a temporary system lockout.";
CM_ SG_ 2566749438 DslPrtcltFltrActvRgnrtnInhbtdDTS "Indicates the state of diesel particulate filter active regeneration inhibition due to a system timeout.";
CM_ SG_ 2566749438 DslPrtcltFltrActvRgnrtnInhb_0000 "Indicates the state of diesel particulate filter active regeneration inhibition due to a system fault being active.";
CM_ SG_ 2566749438 DslPrtcltFltrActvRgnrtnInhbtdDTL "Indicates the state of diesel particulate filter active regeneration inhibition due to the exhaust gas temperature being too";
CM_ SG_ 2566749438 DslPrtcltFltrActvRgnrtnInhb_0001 "Indicates the state of diesel particulate filter active regeneration inhibition due to the parking brake being not set.";
CM_ SG_ 2566749438 DslPrtcltFltrActvRgnrtnInhb_0002 "Speed";
CM_ SG_ 2566749438 DslPrtcltFltrActvRgnrtnInhbtdDTO "Indicates the state of diesel particulate filter active regeneration inhibition due to the transmission being out of neutral.";
CM_ SG_ 2566749438 DslPrtcltFltrActvRgnrtnInhbtdDTA "Indicates the state of diesel particulate filter active regeneration inhibition due to the accelerator pedal being off idle.";
CM_ SG_ 2566749438 DslPrtcltFltrActvRgnrtnInhb_0003 "Indicates the state of diesel particulate filter active regeneration inhibition due to the PTO being active.";
CM_ SG_ 2566749438 DslPrtcltFltrActvRgnrtnInhb_0004 "Indicates the state of diesel particulate filter active regeneration inhibition due to the service brake being active.";
CM_ SG_ 2566749438 DslPrtcltFltrActvRgnrtnInhbtdDTC "Indicates the state of diesel particulate filter active regeneration inhibition due to the clutch being disengaged.";
CM_ SG_ 2566749438 DslPrtcltFltrActvRgnrtnInhbtdDTI "Indicates the state of diesel particulate filter active regeneration inhibition due to the Diesel Particulate Filter Regeneration";
CM_ SG_ 2566749438 DslPrtcltFltrActvRgnrtnInhbtdStt "Indicates the state of diesel particulate filter active regeneration inhibition.";
CM_ SG_ 2566749438 DieselParticulateFilterStatus "Indicates the state of the diesel particulate filter regeneration need and urgency.";
CM_ SG_ 2566749438 DslPrtcltFltrActvRgnrtionStatus "Indicates the state of diesel particulate filter active regeneration.";
CM_ SG_ 2566749438 DslPrtcltFltrPssvRgnrtionStatus "Indicates the state of diesel particulate filter passive regeneration.";
CM_ SG_ 2566749438 DieselParticulateFilterLampCmd "Command to control the diesel particulate filter lamp.";
CM_ BO_ 2566715646 "Diesel Particulate Filter 2 Soot 2";
CM_ SG_ 2566715646 DslPrtclateFilter2SootSignalMin "Minimum output signal level of the current soot measurement from diesel particulate filter 2 soot sensor.";
CM_ SG_ 2566715646 DslPrtclateFilter2SootSignalMax "Maximum output signal level of the current soot measurement from diesel particulate filter 2 soot sensor.";
CM_ SG_ 2566715646 DslPrtcltFltr2StSgnlStndrdDvton "Standard deviation of the soot measurement from diesel particulate filter 2 soot sensor.";
CM_ BO_ 2566724606 "Diesel Particulate Filter 2 Soot";
CM_ SG_ 2566724606 DslPrtcltFltr2StSnsrPrlmnaryFMI "Used to identify the applicable J1939-73 FMI detected in the soot sensor signal by the manufacturer's sensor control";
CM_ SG_ 2566724606 DslPrtcltFlter2MedianSootSignal "Median output signal level from diesel particulate filter 2 soot sensor.";
CM_ SG_ 2566724606 DslPrtclteFilter2MeanSootSignal "Mean output signal level from diesel particulate filter 2 soot sensor.";
CM_ SG_ 2566724606 DslPrticulateFilter2SootDensity "Soot density in diesel particulate filter 2.";
CM_ SG_ 2566724606 DeselParticulateFilter2SootMass "Soot mass in diesel particulate filter 2.";
CM_ BO_ 2566715902 "Diesel Particulate Filter 1 Soot 2";
CM_ SG_ 2566715902 DslPrtclateFilter1SootSignalMin "Minimum output signal level of the current soot measurement from diesel particulate filter 1 soot sensor.";
CM_ SG_ 2566715902 DslPrtclateFilter1SootSignalMax "Maximum output signal level of the current soot measurement from diesel particulate filter 1 soot sensor.";
CM_ SG_ 2566715902 DslPrtcltFltr1StSgnlStndrdDvton "Standard deviation of the soot measurement from diesel particulate filter 1 soot sensor.";
CM_ BO_ 2566724862 "Diesel Particulate Filter 1 Soot";
CM_ SG_ 2566724862 DslPrtcltFltr1StSnsrPrlmnaryFMI "Used to identify the applicable J1939-73 FMI detected in the soot sensor signal by the manufacturer's sensor control";
CM_ SG_ 2566724862 DslPrtcltFlter1MedianSootSignal "Median output signal level from diesel particulate filter 1 soot sensor.";
CM_ SG_ 2566724862 DslPrtclteFilter1MeanSootSignal "Mean output signal level from diesel particulate filter 1 soot sensor.";
CM_ SG_ 2566724862 DslPrticulateFilter1SootDensity "Soot density in diesel particulate filter 1.";
CM_ SG_ 2566724862 DeselParticulateFilter1SootMass "Soot mass in diesel particulate filter 1.";
CM_ BO_ 2566718718 "Direct Lamp Control Data 2";
CM_ SG_ 2566718718 VehicleBatteryChargingLampData "This parameter provides measured data from the Vehicle Battery Charging Lamp.";
CM_ SG_ 2566718718 VhicleHVACRecirculationLampData "This parameter provides measured data from the Vehicle HVAC Recirculation Lamp.";
CM_ SG_ 2566718718 VehicleAirPressLowLampData "This parameter provides measured data from the Vehicle Air Pressure Low Lamp.";
CM_ SG_ 2566718718 VehicleFuelLevelLowLampData "This parameter provides measured data from theVehicle Fuel Level Low Lamp.";
CM_ SG_ 2566718718 VhicleBatteryVoltageLowLampData "This parameter provides measured data from the Vehicle Battery Voltage Low Lamp.";
CM_ BO_ 2566718974 "Direct Lamp Control Data 1";
CM_ SG_ 2566718974 EngWaitToStartLampData "This parameter provides measured data from the Engine Wait To Start Lamp.";
CM_ SG_ 2566718974 EngFuelFilterRestrictedLampData "Command signal directly controlling the Vehicle Fuel Filter Restricted Lamp.";
CM_ SG_ 2566718974 EngAirFilterRestrictionLampData "This parameter provides measured data from the Engine Air Filter Restriction Lamp.";
CM_ SG_ 2566718974 EngIdleManagementActiveLampData "This parameter provides measured data from the Engine Idle Management Active Lamp.";
CM_ SG_ 2566718974 EngCoolantLevelLowLampData "This parameter provides measured data from the Engine Coolant Level Low Lamp.";
CM_ SG_ 2566718974 EngCoolantTempHighLampData "This parameter provides measured data from the Engine Coolant Temperature High Lamp.";
CM_ SG_ 2566718974 EngOilPressLowLampData "This parameter provides measured data from the Engine Oil Pressure Low Lamp.";
CM_ SG_ 2566718974 CmprssnBrkEnblSwtchIndctrLmpDta "This parameter provides measured data from the Compression Brake Enable Switch Indicator Lamp.";
CM_ SG_ 2566718974 EngBrakeActiveLampData "This parameter provides measured data from the Engine Brake Active Lamp.";
CM_ SG_ 2566718974 OBDMalfunctionIndicatorLampData "This parameter provides measured data from the OBD Malfunction Indicator Lamp.";
CM_ SG_ 2566718974 EngRedStopLampData "This parameter provides measured data from the Engine Red Stop Lamp.";
CM_ SG_ 2566718974 EngAmberWarningLampData "This parameter provides measured data from the Engine Amber Warning Lamp.";
CM_ SG_ 2566718974 EngProtectLampData "This parameter provides measured data from the Engine Protect Lamp.";
CM_ BO_ 2566719230 "Direct Lamp Control Command 2";
CM_ SG_ 2566719230 VehicleBatteryChargingLampCmd "Command signal directly controlling the Vehicle Battery Charging Lamp.";
CM_ SG_ 2566719230 VehicleHVACRecirculationLampCmd "Command signal directly controlling the Vehicle HVAC Recirculation Lamp.";
CM_ SG_ 2566719230 VehicleAirPressLowLampCmd "Command signal directly controlling the Vehicle Air Pressure Low Lamp.";
CM_ SG_ 2566719230 VehicleFuelLevelLowLampCmd "Command signal directly controlling the Vehicle Fuel Level Low Lamp.";
CM_ SG_ 2566719230 VehicleBatteryVoltageLowLampCmd "Command signal directly controlling the Vehicle Battery Voltage Low Lamp.";
CM_ BO_ 2560818942 "DM32 provides the DTCs and associated timers";
CM_ SG_ 2560818942 DTCTimeUntilDerate "This timer provides the number of hours the malfunction has until the OBD required derate will occur";
CM_ SG_ 2560818942 DTCTotalPreviouslyActiveTime "This timer provides the number of hours the NOx malfunction has been confirmed and previously active";
CM_ SG_ 2560818942 DTCTotalActiveTime "This timer provides the total number of hours the DTC has been confirmed and active";
CM_ SG_ 2560818942 FailureModeIdentifier1 "The FMI defines the type of failure detected in the subsystem identified by an SPN.";
CM_ SG_ 2560818942 SPN1High "SPN #1 (Conversion Version 4)";
CM_ SG_ 2560818942 SPN1 "SPN #1 (Conversion Version 4)";
BA_DEF_ SG_  "SigType" ENUM  "Default","Range","RangeSigned","ASCII","Discrete","Control","ReferencePGN","DTC","StringDelimiter","StringLength","StringLengthControl";
BA_DEF_ SG_  "GenSigStartValue" INT 0 10000;
BA_DEF_ SG_  "GenSigSendType" ENUM  "Cyclic","OnWrite","reserved","OnChange","reserved","reserved","reserved","NoSigSendType";
BA_DEF_ SG_  "GenSigILSupport" ENUM  "Yes","No";
BA_DEF_ SG_  "GenSigEVName" STRING ;
BA_DEF_ SG_  "SPN" INT 0 524287;
BA_DEF_ BO_  "GenMsgStartDelayTime" INT 0 100000;
BA_DEF_ BO_  "GenMsgILSupport" ENUM  "Yes","No";
BA_DEF_ BO_  "GenMsgRequestable" INT 0 1;
BA_DEF_ BO_  "GenMsgSendType" ENUM  "cyclic","reserved","cyclicIfActive","reserved","reserved","reserved","reserved","reserved","noMsgSendType";
BA_DEF_ BO_  "VFrameFormat" ENUM  "StandardCAN","ExtendedCAN","reserved","J1939PG";
BA_DEF_ BO_  "GenMsgCycleTime" INT 0 3600000;
BA_DEF_ BU_  "NmStationAddress" INT 0 255;
BA_DEF_ BU_  "NmJ1939IndustryGroup" INT 0 7;
BA_DEF_ BU_  "NmJ1939System" INT 0 127;
BA_DEF_ BU_  "NmJ1939Function" INT 0 255;
BA_DEF_ BU_  "NmJ1939FunctionInstance" INT 0 7;
BA_DEF_ BU_  "NmJ1939ECUInstance" INT 0 3;
BA_DEF_  "DatabaseVersion" STRING ;
BA_DEF_  "BusType" STRING ;
BA_DEF_  "ProtocolType" STRING ;
BA_DEF_  "SAE_J1939_75_SpecVersion" STRING ;
BA_DEF_  "SAE_J1939_21_SpecVersion" STRING ;
BA_DEF_  "SAE_J1939_73_SpecVersion" STRING ;
BA_DEF_  "SAE_J1939_71_SpecVersion" STRING ;
BA_DEF_ SG_  "SystemSignalLongSymbol" STRING ;
BA_DEF_DEF_  "SigType" "Default";
BA_DEF_DEF_  "GenSigStartValue" 0;
BA_DEF_DEF_  "GenSigSendType" "NoSigSendType";
BA_DEF_DEF_  "GenSigILSupport" "Yes";
BA_DEF_DEF_  "GenSigEVName" "Env@Nodename_@Signame";
BA_DEF_DEF_  "SPN" 0;
BA_DEF_DEF_  "GenMsgStartDelayTime" 0;
BA_DEF_DEF_  "GenMsgILSupport" "Yes";
BA_DEF_DEF_  "GenMsgRequestable" 1;
BA_DEF_DEF_  "GenMsgSendType" "noMsgSendType";
BA_DEF_DEF_  "VFrameFormat" "J1939PG";
BA_DEF_DEF_  "GenMsgCycleTime" 0;
BA_DEF_DEF_  "NmStationAddress" 254;
BA_DEF_DEF_  "NmJ1939IndustryGroup" 0;
BA_DEF_DEF_  "NmJ1939System" 0;
BA_DEF_DEF_  "NmJ1939Function" 0;
BA_DEF_DEF_  "NmJ1939FunctionInstance" 0;
BA_DEF_DEF_  "NmJ1939ECUInstance" 0;
BA_DEF_DEF_  "DatabaseVersion" "";
BA_DEF_DEF_  "BusType" "";
BA_DEF_DEF_  "ProtocolType" "";
BA_DEF_DEF_  "SAE_J1939_75_SpecVersion" "";
BA_DEF_DEF_  "SAE_J1939_21_SpecVersion" "";
BA_DEF_DEF_  "SAE_J1939_73_SpecVersion" "";
BA_DEF_DEF_  "SAE_J1939_71_SpecVersion" "";
BA_DEF_DEF_  "SystemSignalLongSymbol" "";
BA_ "SAE_J1939_71_SpecVersion" "2009-09";
BA_ "SAE_J1939_73_SpecVersion" "2009-09";
BA_ "SAE_J1939_21_SpecVersion" "2006-10";
BA_ "SAE_J1939_75_SpecVersion" "2005-10";
BA_ "ProtocolType" "J1939";
BA_ "BusType" "CAN";
BA_ "DatabaseVersion" "7.2";
BA_ "NmJ1939Function" BU_ Turbocharger 133;
BA_ "NmStationAddress" BU_ Turbocharger 2;
BA_ "NmJ1939Function" BU_ OnBoardDataLogger 130;
BA_ "NmStationAddress" BU_ OnBoardDataLogger 251;
BA_ "NmJ1939FunctionInstance" BU_ OffBoardDiagnosticTool2 1;
BA_ "NmJ1939Function" BU_ OffBoardDiagnosticTool2 129;
BA_ "NmStationAddress" BU_ OffBoardDiagnosticTool2 250;
BA_ "NmJ1939Function" BU_ OffBoardDiagnosticTool1 129;
BA_ "NmStationAddress" BU_ OffBoardDiagnosticTool1 249;
BA_ "NmJ1939Function" BU_ FileServer 61;
BA_ "NmStationAddress" BU_ FileServer 248;
BA_ "NmJ1939Function" BU_ ParkingBrakeController 9;
BA_ "NmStationAddress" BU_ ParkingBrakeController 80;
BA_ "NmJ1939Function" BU_ SeatControl2 40;
BA_ "NmStationAddress" BU_ SeatControl2 79;
BA_ "NmJ1939Function" BU_ FanDriveController 58;
BA_ "NmStationAddress" BU_ FanDriveController 78;
BA_ "NmJ1939Function" BU_ SteeringColumnUnit 57;
BA_ "NmStationAddress" BU_ SteeringColumnUnit 77;
BA_ "NmJ1939Function" BU_ CommunicationUnitRadio 56;
BA_ "NmStationAddress" BU_ CommunicationUnitRadio 76;
BA_ "NmJ1939Function" BU_ CommunicationUnitSatellite 55;
BA_ "NmStationAddress" BU_ CommunicationUnitSatellite 75;
BA_ "NmJ1939Function" BU_ CommunicationUnitCellular 54;
BA_ "NmStationAddress" BU_ CommunicationUnitCellular 74;
BA_ "NmJ1939Function" BU_ PropulsionBatteryCharger 31;
BA_ "NmStationAddress" BU_ PropulsionBatteryCharger 73;
BA_ "NmJ1939FunctionInstance" BU_ ChassisController2 1;
BA_ "NmJ1939Function" BU_ ChassisController2 52;
BA_ "NmStationAddress" BU_ ChassisController2 72;
BA_ "NmJ1939Function" BU_ ChassisController1 52;
BA_ "NmStationAddress" BU_ ChassisController1 71;
BA_ "NmJ1939Function" BU_ EngineValveControl 63;
BA_ "NmStationAddress" BU_ EngineValveControl 70;
BA_ "NmJ1939FunctionInstance" BU_ AuxiliaryHeater2 1;
BA_ "NmJ1939Function" BU_ AuxiliaryHeater2 50;
BA_ "NmStationAddress" BU_ AuxiliaryHeater2 69;
BA_ "NmJ1939Function" BU_ AuxiliaryHeater1 50;
BA_ "NmStationAddress" BU_ AuxiliaryHeater1 68;
BA_ "NmJ1939Function" BU_ ClutchUnit 49;
BA_ "NmStationAddress" BU_ ClutchUnit 67;
BA_ "NmJ1939Function" BU_ RampControl 48;
BA_ "NmStationAddress" BU_ RampControl 66;
BA_ "NmJ1939Function" BU_ InformationSystem1 47;
BA_ "NmStationAddress" BU_ InformationSystem1 65;
BA_ "NmJ1939Function" BU_ SuspensionSystemController2 35;
BA_ "NmStationAddress" BU_ SuspensionSystemController2 64;
BA_ "NmJ1939Function" BU_ OilSensor 46;
BA_ "NmStationAddress" BU_ OilSensor 63;
BA_ "NmJ1939Function" BU_ VehicleDynamicStability 45;
BA_ "NmStationAddress" BU_ VehicleDynamicStability 62;
BA_ "NmJ1939Function" BU_ ExhaustEmissionController 44;
BA_ "NmStationAddress" BU_ ExhaustEmissionController 61;
BA_ "NmJ1939Function" BU_ TransmissionDisplay2 43;
BA_ "NmStationAddress" BU_ TransmissionDisplay2 60;
BA_ "NmJ1939Function" BU_ TransmissionDisplay1 43;
BA_ "NmStationAddress" BU_ TransmissionDisplay1 59;
BA_ "NmJ1939Function" BU_ ClimateControl2 21;
BA_ "NmStationAddress" BU_ ClimateControl2 58;
BA_ "NmJ1939Function" BU_ WaterPumpController 42;
BA_ "NmStationAddress" BU_ WaterPumpController 57;
BA_ "NmStationAddress" BU_ RearAxleSteeringController 56;
BA_ "NmJ1939Function" BU_ LightingOperatorControl 41;
BA_ "NmStationAddress" BU_ LightingOperatorControl 55;
BA_ "NmJ1939Function" BU_ SeatController1 40;
BA_ "NmStationAddress" BU_ SeatController1 54;
BA_ "NmJ1939FunctionInstance" BU_ IgnitionController2 1;
BA_ "NmJ1939Function" BU_ IgnitionController2 39;
BA_ "NmStationAddress" BU_ IgnitionController2 53;
BA_ "NmJ1939Function" BU_ IgnitionController1 39;
BA_ "NmStationAddress" BU_ IgnitionController1 52;
BA_ "NmJ1939Function" BU_ TirePressureController 38;
BA_ "NmStationAddress" BU_ TirePressureController 51;
BA_ "NmJ1939Function" BU_ CabController2 37;
BA_ "NmStationAddress" BU_ CabController2 50;
BA_ "NmJ1939Function" BU_ CabController1 37;
BA_ "NmStationAddress" BU_ CabController1 49;
BA_ "NmJ1939Function" BU_ PneumaticSystemController 36;
BA_ "NmStationAddress" BU_ PneumaticSystemController 48;
BA_ "NmJ1939Function" BU_ SuspensionSystemController1 35;
BA_ "NmStationAddress" BU_ SuspensionSystemController1 47;
BA_ "NmJ1939Function" BU_ HydraulicPumpController 34;
BA_ "NmStationAddress" BU_ HydraulicPumpController 46;
BA_ "NmJ1939Function" BU_ EnduranceBrakingSystem 64;
BA_ "NmStationAddress" BU_ EnduranceBrakingSystem 45;
BA_ "NmJ1939FunctionInstance" BU_ RetarderExhaustEngine2 1;
BA_ "NmJ1939Function" BU_ RetarderExhaustEngine2 12;
BA_ "NmStationAddress" BU_ RetarderExhaustEngine2 44;
BA_ "NmJ1939Function" BU_ OnBoardDiagnosticUnit 62;
BA_ "NmStationAddress" BU_ OnBoardDiagnosticUnit 43;
BA_ "NmJ1939Function" BU_ HeadwayController 32;
BA_ "NmStationAddress" BU_ HeadwayController 42;
BA_ "NmJ1939Function" BU_ RetarderExhaustEngine1 12;
BA_ "NmStationAddress" BU_ RetarderExhaustEngine1 41;
BA_ "NmJ1939Function" BU_ CabDisplay1 60;
BA_ "NmStationAddress" BU_ CabDisplay1 40;
BA_ "NmJ1939Function" BU_ ManagementComputer 30;
BA_ "NmStationAddress" BU_ ManagementComputer 39;
BA_ "NmJ1939Function" BU_ VirtualTerminal 29;
BA_ "NmStationAddress" BU_ VirtualTerminal 38;
BA_ "NmJ1939Function" BU_ OffVehicleGateway 28;
BA_ "NmStationAddress" BU_ OffVehicleGateway 37;
BA_ "NmJ1939Function" BU_ PowerTakeOffFront 27;
BA_ "NmStationAddress" BU_ PowerTakeOffFront 36;
BA_ "NmStationAddress" BU_ HitchControl 35;
BA_ "NmStationAddress" BU_ AuxiliaryValveControl 34;
BA_ "NmJ1939Function" BU_ BodyController 26;
BA_ "NmStationAddress" BU_ BodyController 33;
BA_ "NmStationAddress" BU_ TractorTrailerBridge1 32;
BA_ "NmJ1939Function" BU_ StarterSystem 59;
BA_ "NmStationAddress" BU_ StarterSystem 31;
BA_ "NmJ1939Function" BU_ ElectricalSystem 67;
BA_ "NmStationAddress" BU_ ElectricalSystem 30;
BA_ "NmJ1939Function" BU_ VehicleSecurity 24;
BA_ "NmStationAddress" BU_ VehicleSecurity 29;
BA_ "NmJ1939Function" BU_ VehicleNavigation 23;
BA_ "NmStationAddress" BU_ VehicleNavigation 28;
BA_ "NmJ1939Function" BU_ AerodynamicControl 22;
BA_ "NmStationAddress" BU_ AerodynamicControl 27;
BA_ "NmJ1939Function" BU_ ElectricalChargingSystem 53;
BA_ "NmStationAddress" BU_ ElectricalChargingSystem 26;
BA_ "NmJ1939Function" BU_ ClimateControl1 21;
BA_ "NmStationAddress" BU_ ClimateControl1 25;
BA_ "NmJ1939Function" BU_ TripRecorder 20;
BA_ "NmStationAddress" BU_ TripRecorder 24;
BA_ "NmJ1939Function" BU_ InstrumentCluster 19;
BA_ "NmStationAddress" BU_ InstrumentCluster 23;
BA_ "NmJ1939FunctionInstance" BU_ SuspensionDriveAxle2 1;
BA_ "NmJ1939Function" BU_ SuspensionDriveAxle2 18;
BA_ "NmStationAddress" BU_ SuspensionDriveAxle2 22;
BA_ "NmJ1939Function" BU_ SuspensionDriveAxle1 18;
BA_ "NmStationAddress" BU_ SuspensionDriveAxle1 21;
BA_ "NmJ1939Function" BU_ SuspensionSteerAxle 17;
BA_ "NmStationAddress" BU_ SuspensionSteerAxle 20;
BA_ "NmJ1939Function" BU_ SteeringController 16;
BA_ "NmStationAddress" BU_ SteeringController 19;
BA_ "NmJ1939Function" BU_ FuelSystem 15;
BA_ "NmStationAddress" BU_ FuelSystem 18;
BA_ "NmJ1939Function" BU_ CruiseControl 14;
BA_ "NmStationAddress" BU_ CruiseControl 17;
BA_ "NmJ1939Function" BU_ RetarderDriveline 13;
BA_ "NmStationAddress" BU_ RetarderDriveline 16;
BA_ "NmJ1939Function" BU_ RetarderEngine 12;
BA_ "NmStationAddress" BU_ RetarderEngine 15;
BA_ "NmJ1939FunctionInstance" BU_ BrakesDriveAxle2 1;
BA_ "NmJ1939Function" BU_ BrakesDriveAxle2 11;
BA_ "NmStationAddress" BU_ BrakesDriveAxle2 14;
BA_ "NmJ1939Function" BU_ BrakesDriveAxle1 11;
BA_ "NmStationAddress" BU_ BrakesDriveAxle1 13;
BA_ "NmJ1939Function" BU_ BrakesSystemController 9;
BA_ "NmStationAddress" BU_ BrakesSystemController 11;
BA_ "NmJ1939Function" BU_ BrakesSteerAxle 10;
BA_ "NmStationAddress" BU_ BrakesSteerAxle 12;
BA_ "NmJ1939FunctionInstance" BU_ AxleDrive2 1;
BA_ "NmJ1939Function" BU_ AxleDrive2 8;
BA_ "NmStationAddress" BU_ AxleDrive2 10;
BA_ "NmJ1939Function" BU_ AxleDrive1 8;
BA_ "NmStationAddress" BU_ AxleDrive1 9;
BA_ "NmJ1939Function" BU_ AxleSteering 7;
BA_ "NmStationAddress" BU_ AxleSteering 8;
BA_ "NmJ1939Function" BU_ PowerTakeOff 6;
BA_ "NmStationAddress" BU_ PowerTakeOff 7;
BA_ "NmJ1939FunctionInstance" BU_ ShiftConsoleSecondary 1;
BA_ "NmJ1939Function" BU_ ShiftConsoleSecondary 5;
BA_ "NmStationAddress" BU_ ShiftConsoleSecondary 6;
BA_ "NmJ1939Function" BU_ ShiftConsolePrimary 5;
BA_ "NmStationAddress" BU_ ShiftConsolePrimary 5;
BA_ "NmJ1939ECUInstance" BU_ Transmission2 1;
BA_ "NmJ1939Function" BU_ Transmission2 3;
BA_ "NmStationAddress" BU_ Transmission2 4;
BA_ "NmJ1939Function" BU_ Transmission1 3;
BA_ "NmStationAddress" BU_ Transmission1 3;
BA_ "NmJ1939FunctionInstance" BU_ Engine2 1;
BA_ "NmStationAddress" BU_ Engine2 1;
BA_ "NmStationAddress" BU_ Engine1 0;
BA_ "GenMsgCycleTime" BO_ 2297441790 10;
BA_ "GenMsgSendType" BO_ 2297441790 0;
BA_ "GenMsgCycleTime" BO_ 2364549630 10;
BA_ "GenMsgSendType" BO_ 2364549630 0;
BA_ "GenMsgCycleTime" BO_ 2297441534 50;
BA_ "GenMsgSendType" BO_ 2297441534 0;
BA_ "GenMsgCycleTime" BO_ 2566722302 500;
BA_ "GenMsgSendType" BO_ 2566722302 0;
BA_ "GenMsgCycleTime" BO_ 2566717950 500;
BA_ "GenMsgSendType" BO_ 2566717950 0;
BA_ "GenMsgCycleTime" BO_ 2499604222 200;
BA_ "GenMsgSendType" BO_ 2499604222 0;
BA_ "GenMsgCycleTime" BO_ 2358902526 100;
BA_ "GenMsgSendType" BO_ 2358902526 0;
BA_ "GenMsgCycleTime" BO_ 2566711550 500;
BA_ "GenMsgSendType" BO_ 2566711550 0;
BA_ "GenMsgCycleTime" BO_ 2566719998 1000;
BA_ "GenMsgSendType" BO_ 2566719998 0;
BA_ "GenMsgCycleTime" BO_ 2566713854 100;
BA_ "GenMsgSendType" BO_ 2566713854 0;
BA_ "GenMsgCycleTime" BO_ 2566714366 100;
BA_ "GenMsgSendType" BO_ 2566714366 0;
BA_ "GenMsgCycleTime" BO_ 2566714110 100;
BA_ "GenMsgSendType" BO_ 2566714110 0;
BA_ "GenMsgCycleTime" BO_ 2566717438 1000;
BA_ "GenMsgSendType" BO_ 2566717438 0;
BA_ "GenMsgCycleTime" BO_ 2633828606 30000;
BA_ "GenMsgSendType" BO_ 2633828606 0;
BA_ "GenMsgCycleTime" BO_ 2566713598 500;
BA_ "GenMsgSendType" BO_ 2566713598 0;
BA_ "GenMsgCycleTime" BO_ 2499604478 500;
BA_ "GenMsgSendType" BO_ 2499604478 0;
BA_ "GenMsgCycleTime" BO_ 2499608830 500;
BA_ "GenMsgSendType" BO_ 2499608830 0;
BA_ "GenMsgCycleTime" BO_ 2432499198 100;
BA_ "GenMsgSendType" BO_ 2432499198 0;
BA_ "GenMsgCycleTime" BO_ 2566715646 1000;
BA_ "GenMsgSendType" BO_ 2566715646 0;
BA_ "GenMsgCycleTime" BO_ 2566724606 1000;
BA_ "GenMsgSendType" BO_ 2566724606 0;
BA_ "GenMsgCycleTime" BO_ 2566715902 1000;
BA_ "GenMsgSendType" BO_ 2566715902 0;
BA_ "GenMsgCycleTime" BO_ 2566724862 1000;
BA_ "GenMsgSendType" BO_ 2566724862 0;
BA_ "GenMsgCycleTime" BO_ 2566718718 1000;
BA_ "GenMsgSendType" BO_ 2566718718 0;
BA_ "GenMsgCycleTime" BO_ 2566718974 1000;
BA_ "GenMsgSendType" BO_ 2566718974 0;
BA_ "SPN" SG_ 3221225472 TrailerWeight 180;
BA_ "SigType" SG_ 3221225472 TrailerWeight 1;
BA_ "SPN" SG_ 3221225472 ReferenceTirePressSetting 3193;
BA_ "SigType" SG_ 3221225472 ReferenceTirePressSetting 1;
BA_ "SPN" SG_ 3221225472 ReferenceTirePress 3191;
BA_ "SigType" SG_ 3221225472 ReferenceTirePress 1;
BA_ "SPN" SG_ 3221225472 TirePressThresholdDetection 2587;
BA_ "SigType" SG_ 3221225472 TirePressThresholdDetection 4;
BA_ "SPN" SG_ 3221225472 TireAirLeakageRate 2586;
BA_ "SigType" SG_ 3221225472 TireAirLeakageRate 1;
BA_ "SPN" SG_ 3221225472 CTIWheelEndElectricalFault 1697;
BA_ "SigType" SG_ 3221225472 CTIWheelEndElectricalFault 4;
BA_ "SPN" SG_ 3221225472 CTITireStatus 1698;
BA_ "SigType" SG_ 3221225472 CTITireStatus 4;
BA_ "SPN" SG_ 3221225472 CTIWheelSensorStatus 1699;
BA_ "SigType" SG_ 3221225472 CTIWheelSensorStatus 4;
BA_ "SPN" SG_ 3221225472 TireTemp 242;
BA_ "SigType" SG_ 3221225472 TireTemp 1;
BA_ "SPN" SG_ 3221225472 TirePress 241;
BA_ "SigType" SG_ 3221225472 TirePress 1;
BA_ "SPN" SG_ 2297441790 SpprtVrblTrnsRpttnRtFrAcclrtnSns 5353;
BA_ "SigType" SG_ 2297441790 SpprtVrblTrnsRpttnRtFrAcclrtnSns 4;
BA_ "SystemSignalLongSymbol" SG_ 2297441790 SpprtVrblTrnsRpttnRtFrAcclrtnSns "SpprtVrblTrnsRpttnRtFrAcclrtnSnsr";
BA_ "SPN" SG_ 2297441790 VrtclAcclrtnExRngeFigureOfMerit 5352;
BA_ "SigType" SG_ 2297441790 VrtclAcclrtnExRngeFigureOfMerit 4;
BA_ "SPN" SG_ 2297441790 LngtdnlAcclrtnExRngFgureOfMerit 5351;
BA_ "SigType" SG_ 2297441790 LngtdnlAcclrtnExRngFgureOfMerit 4;
BA_ "SPN" SG_ 2297441790 LtrlAcclrtnExRangeFigureOfMerit 5350;
BA_ "SigType" SG_ 2297441790 LtrlAcclrtnExRangeFigureOfMerit 4;
BA_ "SPN" SG_ 2297441790 VerticalAccelerationExRange 5349;
BA_ "SigType" SG_ 2297441790 VerticalAccelerationExRange 1;
BA_ "SPN" SG_ 2297441790 LateralAccelerationExRange 5347;
BA_ "SigType" SG_ 2297441790 LateralAccelerationExRange 1;
BA_ "SPN" SG_ 2297441790 LongitudinalAccelerationExRange 5348;
BA_ "SigType" SG_ 2297441790 LongitudinalAccelerationExRange 1;
BA_ "SPN" SG_ 2566712062 HybrdBatteryPackRemainingCharge 5464;
BA_ "SigType" SG_ 2566712062 HybrdBatteryPackRemainingCharge 1;
BA_ "SPN" SG_ 2364549630 RllAndPtchExRngMsurementLatency 4982;
BA_ "SigType" SG_ 2364549630 RllAndPtchExRngMsurementLatency 1;
BA_ "SPN" SG_ 2364549630 RollAngleExRangeFigureOfMerit 4981;
BA_ "SigType" SG_ 2364549630 RollAngleExRangeFigureOfMerit 4;
BA_ "SPN" SG_ 2364549630 RollAngleExRangeCompensation 4980;
BA_ "SigType" SG_ 2364549630 RollAngleExRangeCompensation 4;
BA_ "SPN" SG_ 2364549630 PitchAngleExRangeFigureOfMerit 4979;
BA_ "SigType" SG_ 2364549630 PitchAngleExRangeFigureOfMerit 4;
BA_ "SPN" SG_ 2364549630 PitchAngleExRangeCompensation 4978;
BA_ "SigType" SG_ 2364549630 PitchAngleExRangeCompensation 4;
BA_ "SPN" SG_ 2364549630 RollAngleExRange 4977;
BA_ "SigType" SG_ 2364549630 RollAngleExRange 1;
BA_ "SPN" SG_ 2364549630 PitchAngleExRange 4976;
BA_ "SigType" SG_ 2364549630 PitchAngleExRange 1;
BA_ "SPN" SG_ 2499614462 OccpntClssfcationSystem10Status 4972;
BA_ "SigType" SG_ 2499614462 OccpntClssfcationSystem10Status 4;
BA_ "SPN" SG_ 2499614462 OccpntClssficationSystem9Status 4971;
BA_ "SigType" SG_ 2499614462 OccpntClssficationSystem9Status 4;
BA_ "SPN" SG_ 2499614462 OccpntClssficationSystem8Status 4970;
BA_ "SigType" SG_ 2499614462 OccpntClssficationSystem8Status 4;
BA_ "SPN" SG_ 2499614462 OccpntClssficationSystem7Status 4969;
BA_ "SigType" SG_ 2499614462 OccpntClssficationSystem7Status 4;
BA_ "SPN" SG_ 2499614462 OccpntClssficationSystem6Status 4968;
BA_ "SigType" SG_ 2499614462 OccpntClssficationSystem6Status 4;
BA_ "SPN" SG_ 2499614462 OccpntClssficationSystem5Status 4967;
BA_ "SigType" SG_ 2499614462 OccpntClssficationSystem5Status 4;
BA_ "SPN" SG_ 2499614462 OccpntClssficationSystem4Status 4966;
BA_ "SigType" SG_ 2499614462 OccpntClssficationSystem4Status 4;
BA_ "SPN" SG_ 2499614462 OccpntClssficationSystem3Status 4965;
BA_ "SigType" SG_ 2499614462 OccpntClssficationSystem3Status 4;
BA_ "SPN" SG_ 2499614462 PssngrOccpntClssfctnSystmStatus 4964;
BA_ "SigType" SG_ 2499614462 PssngrOccpntClssfctnSystmStatus 4;
BA_ "SPN" SG_ 2499614462 DrvrOccpntClssfctonSystemStatus 4963;
BA_ "SigType" SG_ 2499614462 DrvrOccpntClssfctonSystemStatus 4;
BA_ "SPN" SG_ 2560098046 CabNoiseCtrlTuningStatus 5060;
BA_ "SigType" SG_ 2560098046 CabNoiseCtrlTuningStatus 4;
BA_ "SPN" SG_ 2560098046 CabNoiseCtrlStatus 5059;
BA_ "SigType" SG_ 2560098046 CabNoiseCtrlStatus 4;
BA_ "SPN" SG_ 2560163582 CabNoiseCtrlTuningState 5058;
BA_ "SigType" SG_ 2560163582 CabNoiseCtrlTuningState 4;
BA_ "SPN" SG_ 2560163582 CabNoiseCtrlState 5057;
BA_ "SigType" SG_ 2560163582 CabNoiseCtrlState 4;
BA_ "SPN" SG_ 2297441534 DropRelayCtrl 5403;
BA_ "SigType" SG_ 2297441534 DropRelayCtrl 4;
BA_ "SPN" SG_ 2297441534 LiftRelayCtrl 5402;
BA_ "SigType" SG_ 2297441534 LiftRelayCtrl 4;
BA_ "SPN" SG_ 2297441534 MaterialDropActiveStatus 5014;
BA_ "SigType" SG_ 2297441534 MaterialDropActiveStatus 4;
BA_ "SPN" SG_ 2297441534 MaterialLiftActiveStatus 5013;
BA_ "SigType" SG_ 2297441534 MaterialLiftActiveStatus 4;
BA_ "SPN" SG_ 2297441534 GnratorCurrentBoostActiveStatus 5012;
BA_ "SigType" SG_ 2297441534 GnratorCurrentBoostActiveStatus 4;
BA_ "SPN" SG_ 2297441534 MaterialDropSwitch 5011;
BA_ "SigType" SG_ 2297441534 MaterialDropSwitch 4;
BA_ "SPN" SG_ 2297441534 MaterialLiftSwitch 5010;
BA_ "SigType" SG_ 2297441534 MaterialLiftSwitch 4;
BA_ "SPN" SG_ 2297441534 MagnetReverseCurrent 5009;
BA_ "SigType" SG_ 2297441534 MagnetReverseCurrent 1;
BA_ "SPN" SG_ 2297441534 MagnetForwardCurrent 5008;
BA_ "SigType" SG_ 2297441534 MagnetForwardCurrent 1;
BA_ "SPN" SG_ 2566722302 GneratorDutyCycleExceededStatus 5007;
BA_ "SigType" SG_ 2566722302 GneratorDutyCycleExceededStatus 4;
BA_ "SPN" SG_ 2566722302 VoltageMonitorActiveStatus 5006;
BA_ "SigType" SG_ 2566722302 VoltageMonitorActiveStatus 4;
BA_ "SPN" SG_ 2566722302 GensetEnableActiveStatus 5005;
BA_ "SigType" SG_ 2566722302 GensetEnableActiveStatus 4;
BA_ "SPN" SG_ 2566722302 ReverseCurrentRangeSetting 5002;
BA_ "SigType" SG_ 2566722302 ReverseCurrentRangeSetting 4;
BA_ "SPN" SG_ 2566722302 GensetSoftstartActiveStatus 5004;
BA_ "SigType" SG_ 2566722302 GensetSoftstartActiveStatus 4;
BA_ "SPN" SG_ 2566722302 Grapple_MagnetSelectionSwitch 5003;
BA_ "SigType" SG_ 2566722302 Grapple_MagnetSelectionSwitch 4;
BA_ "SPN" SG_ 2566722302 GnstSystmOtptVoltageRangeStatus 5001;
BA_ "SigType" SG_ 2566722302 GnstSystmOtptVoltageRangeStatus 4;
BA_ "SPN" SG_ 2566722302 GeneratorOverheatStatus 5000;
BA_ "SigType" SG_ 2566722302 GeneratorOverheatStatus 4;
BA_ "SPN" SG_ 2566722558 MagnetRatedPower 4999;
BA_ "SigType" SG_ 2566722558 MagnetRatedPower 1;
BA_ "SPN" SG_ 2566722558 MagnetBoostTime 4998;
BA_ "SigType" SG_ 2566722558 MagnetBoostTime 1;
BA_ "SPN" SG_ 2560032510 LwVltgDscnnctDsredOperatingMode 5149;
BA_ "SigType" SG_ 2560032510 LwVltgDscnnctDsredOperatingMode 4;
BA_ "SPN" SG_ 2566717950 LowVoltageDisconnectTemp 5148;
BA_ "SigType" SG_ 2566717950 LowVoltageDisconnectTemp 1;
BA_ "SPN" SG_ 2566717950 LwVltgDisconnectVoutOutputState 5147;
BA_ "SigType" SG_ 2566717950 LwVltgDisconnectVoutOutputState 4;
BA_ "SPN" SG_ 2566717950 LwVoltageDisconnectOutput1State 5146;
BA_ "SigType" SG_ 2566717950 LwVoltageDisconnectOutput1State 4;
BA_ "SPN" SG_ 2566717950 LwVoltageDisconnectOutput2State 5145;
BA_ "SigType" SG_ 2566717950 LwVoltageDisconnectOutput2State 4;
BA_ "SPN" SG_ 2566717950 LwVoltageDisconnectOutput3State 5144;
BA_ "SigType" SG_ 2566717950 LwVoltageDisconnectOutput3State 4;
BA_ "SPN" SG_ 2566717950 LwVltgDscnnctCrrntOperatingMode 5143;
BA_ "SigType" SG_ 2566717950 LwVltgDscnnctCrrntOperatingMode 4;
BA_ "SPN" SG_ 2566717950 LwVltgDscnnctManualConnectState 5142;
BA_ "SigType" SG_ 2566717950 LwVltgDscnnctManualConnectState 4;
BA_ "SPN" SG_ 2566717950 LwVltgDscnnctMnlDisconnectState 5141;
BA_ "SigType" SG_ 2566717950 LwVltgDscnnctMnlDisconnectState 4;
BA_ "SPN" SG_ 2499604222 BldRferenceElevationOffsetRight 5413;
BA_ "SigType" SG_ 2499604222 BldRferenceElevationOffsetRight 1;
BA_ "SPN" SG_ 2499604222 BldReferenceElevationOffsetLeft 5412;
BA_ "SigType" SG_ 2499604222 BldReferenceElevationOffsetLeft 1;
BA_ "SPN" SG_ 2499604222 BladeElevationDeviationRight 5411;
BA_ "SigType" SG_ 2499604222 BladeElevationDeviationRight 1;
BA_ "SPN" SG_ 2499604222 BladeElevationDeviationLeft 5410;
BA_ "SigType" SG_ 2499604222 BladeElevationDeviationLeft 1;
BA_ "SPN" SG_ 2358902526 Joystick3Lamp10Cmd 4489;
BA_ "SigType" SG_ 2358902526 Joystick3Lamp10Cmd 4;
BA_ "SPN" SG_ 2358902526 Joystick3Lamp9Cmd 4488;
BA_ "SigType" SG_ 2358902526 Joystick3Lamp9Cmd 4;
BA_ "SPN" SG_ 2358902526 Joystick3Lamp8Cmd 4487;
BA_ "SigType" SG_ 2358902526 Joystick3Lamp8Cmd 4;
BA_ "SPN" SG_ 2358902526 Joystick3Lamp7Cmd 4486;
BA_ "SigType" SG_ 2358902526 Joystick3Lamp7Cmd 4;
BA_ "SPN" SG_ 2358902526 Joystick3Lamp6Cmd 4485;
BA_ "SigType" SG_ 2358902526 Joystick3Lamp6Cmd 4;
BA_ "SPN" SG_ 2358902526 Joystick3Lamp5Cmd 4484;
BA_ "SigType" SG_ 2358902526 Joystick3Lamp5Cmd 4;
BA_ "SPN" SG_ 2358902526 Joystick3Lamp4Cmd 4483;
BA_ "SigType" SG_ 2358902526 Joystick3Lamp4Cmd 4;
BA_ "SPN" SG_ 2358902526 Joystick3Lamp3Cmd 4482;
BA_ "SigType" SG_ 2358902526 Joystick3Lamp3Cmd 4;
BA_ "SPN" SG_ 2358902526 Joystick3Lamp2Cmd 4481;
BA_ "SigType" SG_ 2358902526 Joystick3Lamp2Cmd 4;
BA_ "SPN" SG_ 2358902526 Joystick3Lamp1Cmd 4480;
BA_ "SigType" SG_ 2358902526 Joystick3Lamp1Cmd 4;
BA_ "SPN" SG_ 2358902526 Joystick2Lamp10Cmd 4479;
BA_ "SigType" SG_ 2358902526 Joystick2Lamp10Cmd 4;
BA_ "SPN" SG_ 2358902526 Joystick2Lamp9Cmd 4478;
BA_ "SigType" SG_ 2358902526 Joystick2Lamp9Cmd 4;
BA_ "SPN" SG_ 2358902526 Joystick2Lamp8Cmd 4477;
BA_ "SigType" SG_ 2358902526 Joystick2Lamp8Cmd 4;
BA_ "SPN" SG_ 2358902526 Joystick2Lamp7Cmd 4476;
BA_ "SigType" SG_ 2358902526 Joystick2Lamp7Cmd 4;
BA_ "SPN" SG_ 2358902526 Joystick2Lamp6Cmd 4475;
BA_ "SigType" SG_ 2358902526 Joystick2Lamp6Cmd 4;
BA_ "SPN" SG_ 2358902526 Joystick2Lamp5Cmd 4474;
BA_ "SigType" SG_ 2358902526 Joystick2Lamp5Cmd 4;
BA_ "SPN" SG_ 2358902526 Joystick2Lamp4Cmd 4473;
BA_ "SigType" SG_ 2358902526 Joystick2Lamp4Cmd 4;
BA_ "SPN" SG_ 2358902526 Joystick2Lamp3Cmd 4472;
BA_ "SigType" SG_ 2358902526 Joystick2Lamp3Cmd 4;
BA_ "SPN" SG_ 2358902526 Joystick2Lamp2Cmd 4471;
BA_ "SigType" SG_ 2358902526 Joystick2Lamp2Cmd 4;
BA_ "SPN" SG_ 2358902526 Joystick2Lamp1Cmd 4470;
BA_ "SigType" SG_ 2358902526 Joystick2Lamp1Cmd 4;
BA_ "SPN" SG_ 2358902526 Joystick1Lamp10Cmd 4469;
BA_ "SigType" SG_ 2358902526 Joystick1Lamp10Cmd 4;
BA_ "SPN" SG_ 2358902526 Joystick1Lamp9Cmd 4468;
BA_ "SigType" SG_ 2358902526 Joystick1Lamp9Cmd 4;
BA_ "SPN" SG_ 2358902526 Joystick1Lamp8Cmd 4467;
BA_ "SigType" SG_ 2358902526 Joystick1Lamp8Cmd 4;
BA_ "SPN" SG_ 2358902526 Joystick1Lamp7Cmd 4466;
BA_ "SigType" SG_ 2358902526 Joystick1Lamp7Cmd 4;
BA_ "SPN" SG_ 2358902526 Joystick1Lamp6Cmd 4465;
BA_ "SigType" SG_ 2358902526 Joystick1Lamp6Cmd 4;
BA_ "SPN" SG_ 2358902526 Joystick1Lamp5Cmd 4464;
BA_ "SigType" SG_ 2358902526 Joystick1Lamp5Cmd 4;
BA_ "SPN" SG_ 2358902526 Joystick1Lamp4Cmd 4463;
BA_ "SigType" SG_ 2358902526 Joystick1Lamp4Cmd 4;
BA_ "SPN" SG_ 2358902526 Joystick1Lamp3Cmd 4462;
BA_ "SigType" SG_ 2358902526 Joystick1Lamp3Cmd 4;
BA_ "SPN" SG_ 2358902526 Joystick1Lamp2Cmd 4461;
BA_ "SigType" SG_ 2358902526 Joystick1Lamp2Cmd 4;
BA_ "SPN" SG_ 2358902526 Joystick1Lamp1Cmd 4460;
BA_ "SigType" SG_ 2358902526 Joystick1Lamp1Cmd 4;
BA_ "SPN" SG_ 2566711550 IntkVlvActtnSystmOlPrss2SlndCtrl 5500;
BA_ "SigType" SG_ 2566711550 IntkVlvActtnSystmOlPrss2SlndCtrl 4;
BA_ "SPN" SG_ 2566711550 IntkVlvActtnSystmOlPrss1SlndCtrl 5499;
BA_ "SigType" SG_ 2566711550 IntkVlvActtnSystmOlPrss1SlndCtrl 4;
BA_ "SPN" SG_ 2633832958 SpecialIgnitorLoop90Resistance 4917;
BA_ "SigType" SG_ 2633832958 SpecialIgnitorLoop90Resistance 1;
BA_ "SPN" SG_ 2633832958 SpecialIgnitorLoop89Resistance 4916;
BA_ "SigType" SG_ 2633832958 SpecialIgnitorLoop89Resistance 1;
BA_ "SPN" SG_ 2633832958 SpecialIgnitorLoop88Resistance 4915;
BA_ "SigType" SG_ 2633832958 SpecialIgnitorLoop88Resistance 1;
BA_ "SPN" SG_ 2633832958 SpecialIgnitorLoop87Resistance 4914;
BA_ "SigType" SG_ 2633832958 SpecialIgnitorLoop87Resistance 1;
BA_ "SPN" SG_ 2633832958 SpecialIgnitorLoop86Resistance 4913;
BA_ "SigType" SG_ 2633832958 SpecialIgnitorLoop86Resistance 1;
BA_ "SPN" SG_ 2633832958 SpecialIgnitorLoop85Resistance 4912;
BA_ "SigType" SG_ 2633832958 SpecialIgnitorLoop85Resistance 1;
BA_ "SPN" SG_ 2633832958 SpecialIgnitorLoop84Resistance 4911;
BA_ "SigType" SG_ 2633832958 SpecialIgnitorLoop84Resistance 1;
BA_ "SPN" SG_ 2633832958 SpecialIgnitorLoop83Resistance 4910;
BA_ "SigType" SG_ 2633832958 SpecialIgnitorLoop83Resistance 1;
BA_ "SPN" SG_ 2633832958 SpecialIgnitorLoop82Resistance 4909;
BA_ "SigType" SG_ 2633832958 SpecialIgnitorLoop82Resistance 1;
BA_ "SPN" SG_ 2633832958 SpecialIgnitorLoop81Resistance 4908;
BA_ "SigType" SG_ 2633832958 SpecialIgnitorLoop81Resistance 1;
BA_ "SPN" SG_ 2633832958 SpecialIgnitorLoop80Resistance 4907;
BA_ "SigType" SG_ 2633832958 SpecialIgnitorLoop80Resistance 1;
BA_ "SPN" SG_ 2633832958 SpecialIgnitorLoop79Resistance 4906;
BA_ "SigType" SG_ 2633832958 SpecialIgnitorLoop79Resistance 1;
BA_ "SPN" SG_ 2633832958 SpecialIgnitorLoop78Resistance 4905;
BA_ "SigType" SG_ 2633832958 SpecialIgnitorLoop78Resistance 1;
BA_ "SPN" SG_ 2633832958 SpecialIgnitorLoop77Resistance 4904;
BA_ "SigType" SG_ 2633832958 SpecialIgnitorLoop77Resistance 1;
BA_ "SPN" SG_ 2633832958 SpecialIgnitorLoop76Resistance 4903;
BA_ "SigType" SG_ 2633832958 SpecialIgnitorLoop76Resistance 1;
BA_ "SPN" SG_ 2633832958 SpecialIgnitorLoop75Resistance 4902;
BA_ "SigType" SG_ 2633832958 SpecialIgnitorLoop75Resistance 1;
BA_ "SPN" SG_ 2633832958 SpecialIgnitorLoop74Resistance 4901;
BA_ "SigType" SG_ 2633832958 SpecialIgnitorLoop74Resistance 1;
BA_ "SPN" SG_ 2633832958 SpecialIgnitorLoop73Resistance 4900;
BA_ "SigType" SG_ 2633832958 SpecialIgnitorLoop73Resistance 1;
BA_ "SPN" SG_ 2633832958 SpecialIgnitorLoop72Resistance 4899;
BA_ "SigType" SG_ 2633832958 SpecialIgnitorLoop72Resistance 1;
BA_ "SPN" SG_ 2633832958 SpecialIgnitorLoop71Resistance 4898;
BA_ "SigType" SG_ 2633832958 SpecialIgnitorLoop71Resistance 1;
BA_ "SPN" SG_ 2633832958 SpecialIgnitorLoop70Resistance 4897;
BA_ "SigType" SG_ 2633832958 SpecialIgnitorLoop70Resistance 1;
BA_ "SPN" SG_ 2633832958 SpecialIgnitorLoop69Resistance 4896;
BA_ "SigType" SG_ 2633832958 SpecialIgnitorLoop69Resistance 1;
BA_ "SPN" SG_ 2633832958 SpecialIgnitorLoop68Resistance 4895;
BA_ "SigType" SG_ 2633832958 SpecialIgnitorLoop68Resistance 1;
BA_ "SPN" SG_ 2633832958 SpecialIgnitorLoop67Resistance 4894;
BA_ "SigType" SG_ 2633832958 SpecialIgnitorLoop67Resistance 1;
BA_ "SPN" SG_ 2633832958 SpecialIgnitorLoop66Resistance 4893;
BA_ "SigType" SG_ 2633832958 SpecialIgnitorLoop66Resistance 1;
BA_ "SPN" SG_ 2633832958 SpecialIgnitorLoop65Resistance 4892;
BA_ "SigType" SG_ 2633832958 SpecialIgnitorLoop65Resistance 1;
BA_ "SPN" SG_ 2633832958 SpecialIgnitorLoop64Resistance 4891;
BA_ "SigType" SG_ 2633832958 SpecialIgnitorLoop64Resistance 1;
BA_ "SPN" SG_ 2633832958 SpecialIgnitorLoop63Resistance 4890;
BA_ "SigType" SG_ 2633832958 SpecialIgnitorLoop63Resistance 1;
BA_ "SPN" SG_ 2633832958 SpecialIgnitorLoop61Resistance 4888;
BA_ "SigType" SG_ 2633832958 SpecialIgnitorLoop61Resistance 1;
BA_ "SPN" SG_ 2633832958 SpecialIgnitorLoop60Resistance 4887;
BA_ "SigType" SG_ 2633832958 SpecialIgnitorLoop60Resistance 1;
BA_ "SPN" SG_ 2633832958 SpecialIgnitorLoop59Resistance 4886;
BA_ "SigType" SG_ 2633832958 SpecialIgnitorLoop59Resistance 1;
BA_ "SPN" SG_ 2633832958 SpecialIgnitorLoop58Resistance 4885;
BA_ "SigType" SG_ 2633832958 SpecialIgnitorLoop58Resistance 1;
BA_ "SPN" SG_ 2633832958 SpecialIgnitorLoop57Resistance 4884;
BA_ "SigType" SG_ 2633832958 SpecialIgnitorLoop57Resistance 1;
BA_ "SPN" SG_ 2633832958 SpecialIgnitorLoop56Resistance 4883;
BA_ "SigType" SG_ 2633832958 SpecialIgnitorLoop56Resistance 1;
BA_ "SPN" SG_ 2633832958 SpecialIgnitorLoop55Resistance 4882;
BA_ "SigType" SG_ 2633832958 SpecialIgnitorLoop55Resistance 1;
BA_ "SPN" SG_ 2633832958 SpecialIgnitorLoop54Resistance 4881;
BA_ "SigType" SG_ 2633832958 SpecialIgnitorLoop54Resistance 1;
BA_ "SPN" SG_ 2633832958 SpecialIgnitorLoop53Resistance 4880;
BA_ "SigType" SG_ 2633832958 SpecialIgnitorLoop53Resistance 1;
BA_ "SPN" SG_ 2633832958 SpecialIgnitorLoop52Resistance 4879;
BA_ "SigType" SG_ 2633832958 SpecialIgnitorLoop52Resistance 1;
BA_ "SPN" SG_ 2633832958 SpecialIgnitorLoop51Resistance 4878;
BA_ "SigType" SG_ 2633832958 SpecialIgnitorLoop51Resistance 1;
BA_ "SPN" SG_ 2633832958 SpecialIgnitorLoop50Resistance 4877;
BA_ "SigType" SG_ 2633832958 SpecialIgnitorLoop50Resistance 1;
BA_ "SPN" SG_ 2633832958 SpecialIgnitorLoop49Resistance 4876;
BA_ "SigType" SG_ 2633832958 SpecialIgnitorLoop49Resistance 1;
BA_ "SPN" SG_ 2633832958 SpecialIgnitorLoop48Resistance 4875;
BA_ "SigType" SG_ 2633832958 SpecialIgnitorLoop48Resistance 1;
BA_ "SPN" SG_ 2633832958 SpecialIgnitorLoop47Resistance 4874;
BA_ "SigType" SG_ 2633832958 SpecialIgnitorLoop47Resistance 1;
BA_ "SPN" SG_ 2633832958 SpecialIgnitorLoop46Resistance 4873;
BA_ "SigType" SG_ 2633832958 SpecialIgnitorLoop46Resistance 1;
BA_ "SPN" SG_ 2633832958 SpecialIgnitorLoop45Resistance 4872;
BA_ "SigType" SG_ 2633832958 SpecialIgnitorLoop45Resistance 1;
BA_ "SPN" SG_ 2633832958 SpecialIgnitorLoop44Resistance 4871;
BA_ "SigType" SG_ 2633832958 SpecialIgnitorLoop44Resistance 1;
BA_ "SPN" SG_ 2633832958 SpecialIgnitorLoop43Resistance 4870;
BA_ "SigType" SG_ 2633832958 SpecialIgnitorLoop43Resistance 1;
BA_ "SPN" SG_ 2633832958 SpecialIgnitorLoop42Resistance 4869;
BA_ "SigType" SG_ 2633832958 SpecialIgnitorLoop42Resistance 1;
BA_ "SPN" SG_ 2633832958 SpecialIgnitorLoop41Resistance 4868;
BA_ "SigType" SG_ 2633832958 SpecialIgnitorLoop41Resistance 1;
BA_ "SPN" SG_ 2633832958 SpecialIgnitorLoop40Resistance 4867;
BA_ "SigType" SG_ 2633832958 SpecialIgnitorLoop40Resistance 1;
BA_ "SPN" SG_ 2633832958 SpecialIgnitorLoop39Resistance 4866;
BA_ "SigType" SG_ 2633832958 SpecialIgnitorLoop39Resistance 1;
BA_ "SPN" SG_ 2633832958 SpecialIgnitorLoop38Resistance 4865;
BA_ "SigType" SG_ 2633832958 SpecialIgnitorLoop38Resistance 1;
BA_ "SPN" SG_ 2633832958 SpecialIgnitorLoop37Resistance 4864;
BA_ "SigType" SG_ 2633832958 SpecialIgnitorLoop37Resistance 1;
BA_ "SPN" SG_ 2633832958 SpecialIgnitorLoop36Resistance 4863;
BA_ "SigType" SG_ 2633832958 SpecialIgnitorLoop36Resistance 1;
BA_ "SPN" SG_ 2633832958 SpecialIgnitorLoop35Resistance 4862;
BA_ "SigType" SG_ 2633832958 SpecialIgnitorLoop35Resistance 1;
BA_ "SPN" SG_ 2633832958 SpecialIgnitorLoop34Resistance 4861;
BA_ "SigType" SG_ 2633832958 SpecialIgnitorLoop34Resistance 1;
BA_ "SPN" SG_ 2633832958 SpecialIgnitorLoop33Resistance 4860;
BA_ "SigType" SG_ 2633832958 SpecialIgnitorLoop33Resistance 1;
BA_ "SPN" SG_ 2633832958 SpecialIgnitorLoop32Resistance 4859;
BA_ "SigType" SG_ 2633832958 SpecialIgnitorLoop32Resistance 1;
BA_ "SPN" SG_ 2633832958 SpecialIgnitorLoop31Resistance 4858;
BA_ "SigType" SG_ 2633832958 SpecialIgnitorLoop31Resistance 1;
BA_ "SPN" SG_ 2633832958 SpecialIgnitorLoop30Resistance 4857;
BA_ "SigType" SG_ 2633832958 SpecialIgnitorLoop30Resistance 1;
BA_ "SPN" SG_ 2633832958 SpecialIgnitorLoop29Resistance 4856;
BA_ "SigType" SG_ 2633832958 SpecialIgnitorLoop29Resistance 1;
BA_ "SPN" SG_ 2633832958 SpecialIgnitorLoop28Resistance 4855;
BA_ "SigType" SG_ 2633832958 SpecialIgnitorLoop28Resistance 1;
BA_ "SPN" SG_ 2633832958 SpecialIgnitorLoop27Resistance 4854;
BA_ "SigType" SG_ 2633832958 SpecialIgnitorLoop27Resistance 1;
BA_ "SPN" SG_ 2633832958 SpecialIgnitorLoop26Resistance 4853;
BA_ "SigType" SG_ 2633832958 SpecialIgnitorLoop26Resistance 1;
BA_ "SPN" SG_ 2633832958 SpecialIgnitorLoop25Resistance 4852;
BA_ "SigType" SG_ 2633832958 SpecialIgnitorLoop25Resistance 1;
BA_ "SPN" SG_ 2633832958 SpecialIgnitorLoop24Resistance 4851;
BA_ "SigType" SG_ 2633832958 SpecialIgnitorLoop24Resistance 1;
BA_ "SPN" SG_ 2633832958 SpecialIgnitorLoop23Resistance 4850;
BA_ "SigType" SG_ 2633832958 SpecialIgnitorLoop23Resistance 1;
BA_ "SPN" SG_ 2633832958 SpecialIgnitorLoop22Resistance 4849;
BA_ "SigType" SG_ 2633832958 SpecialIgnitorLoop22Resistance 1;
BA_ "SPN" SG_ 2633832958 SpecialIgnitorLoop21Resistance 4848;
BA_ "SigType" SG_ 2633832958 SpecialIgnitorLoop21Resistance 1;
BA_ "SPN" SG_ 2633832958 SpecialIgnitorLoop20Resistance 4847;
BA_ "SigType" SG_ 2633832958 SpecialIgnitorLoop20Resistance 1;
BA_ "SPN" SG_ 2633832958 SpecialIgnitorLoop19Resistance 4846;
BA_ "SigType" SG_ 2633832958 SpecialIgnitorLoop19Resistance 1;
BA_ "SPN" SG_ 2633832958 SpecialIgnitorLoop18Resistance 4845;
BA_ "SigType" SG_ 2633832958 SpecialIgnitorLoop18Resistance 1;
BA_ "SPN" SG_ 2633832958 SpecialIgnitorLoop17Resistance 4844;
BA_ "SigType" SG_ 2633832958 SpecialIgnitorLoop17Resistance 1;
BA_ "SPN" SG_ 2633832958 SpecialIgnitorLoop16Resistance 4843;
BA_ "SigType" SG_ 2633832958 SpecialIgnitorLoop16Resistance 1;
BA_ "SPN" SG_ 2633832958 SpecialIgnitorLoop15Resistance 4842;
BA_ "SigType" SG_ 2633832958 SpecialIgnitorLoop15Resistance 1;
BA_ "SPN" SG_ 2633832958 SpecialIgnitorLoop14Resistance 4841;
BA_ "SigType" SG_ 2633832958 SpecialIgnitorLoop14Resistance 1;
BA_ "SPN" SG_ 2633832958 SpecialIgnitorLoop13Resistance 4840;
BA_ "SigType" SG_ 2633832958 SpecialIgnitorLoop13Resistance 1;
BA_ "SPN" SG_ 2633832958 SpecialIgnitorLoop12Resistance 4839;
BA_ "SigType" SG_ 2633832958 SpecialIgnitorLoop12Resistance 1;
BA_ "SPN" SG_ 2633832958 SpecialIgnitorLoop11Resistance 4838;
BA_ "SigType" SG_ 2633832958 SpecialIgnitorLoop11Resistance 1;
BA_ "SPN" SG_ 2633832958 SpecialIgnitorLoop10Resistance 4837;
BA_ "SigType" SG_ 2633832958 SpecialIgnitorLoop10Resistance 1;
BA_ "SPN" SG_ 2633832958 SpecialIgnitorLoop9Resistance 4836;
BA_ "SigType" SG_ 2633832958 SpecialIgnitorLoop9Resistance 1;
BA_ "SPN" SG_ 2633832958 SpecialIgnitorLoop8Resistance 4835;
BA_ "SigType" SG_ 2633832958 SpecialIgnitorLoop8Resistance 1;
BA_ "SPN" SG_ 2633832958 SpecialIgnitorLoop7Resistance 4834;
BA_ "SigType" SG_ 2633832958 SpecialIgnitorLoop7Resistance 1;
BA_ "SPN" SG_ 2633832958 SpecialIgnitorLoop6Resistance 4833;
BA_ "SigType" SG_ 2633832958 SpecialIgnitorLoop6Resistance 1;
BA_ "SPN" SG_ 2633832958 SpecialIgnitorLoop5Resistance 4832;
BA_ "SigType" SG_ 2633832958 SpecialIgnitorLoop5Resistance 1;
BA_ "SPN" SG_ 2633832958 SpecialIgnitorLoop4Resistance 4831;
BA_ "SigType" SG_ 2633832958 SpecialIgnitorLoop4Resistance 1;
BA_ "SPN" SG_ 2633832958 SpecialIgnitorLoop3Resistance 4830;
BA_ "SigType" SG_ 2633832958 SpecialIgnitorLoop3Resistance 1;
BA_ "SPN" SG_ 2633832958 SpecialIgnitorLoop2Resistance 4829;
BA_ "SigType" SG_ 2633832958 SpecialIgnitorLoop2Resistance 1;
BA_ "SPN" SG_ 2633832958 SpecialIgnitorLoop1Resistance 4828;
BA_ "SigType" SG_ 2633832958 SpecialIgnitorLoop1Resistance 1;
BA_ "SPN" SG_ 2633832958 SdBgIgnitorLoop2RightResistance 4827;
BA_ "SigType" SG_ 2633832958 SdBgIgnitorLoop2RightResistance 1;
BA_ "SPN" SG_ 2633832958 SdBgIgnitorLoop1RightResistance 4826;
BA_ "SigType" SG_ 2633832958 SdBgIgnitorLoop1RightResistance 1;
BA_ "SPN" SG_ 2633832958 SdBagIgnitorLoop2LeftResistance 4825;
BA_ "SigType" SG_ 2633832958 SdBagIgnitorLoop2LeftResistance 1;
BA_ "SPN" SG_ 2633832958 SdBagIgnitorLoop1LeftResistance 4824;
BA_ "SigType" SG_ 2633832958 SdBagIgnitorLoop1LeftResistance 1;
BA_ "SPN" SG_ 2633832958 PssngrBltTnsnrIgntrLpResistance 4823;
BA_ "SigType" SG_ 2633832958 PssngrBltTnsnrIgntrLpResistance 1;
BA_ "SPN" SG_ 2633832958 DrvrBltTnsnrIgntrLoopResistance 4822;
BA_ "SigType" SG_ 2633832958 DrvrBltTnsnrIgntrLoopResistance 1;
BA_ "SPN" SG_ 2633832958 PssngrArbgIgntrLp2ndStgRsstance 4821;
BA_ "SigType" SG_ 2633832958 PssngrArbgIgntrLp2ndStgRsstance 1;
BA_ "SPN" SG_ 2633832958 DrvrArbgIgntrLp2ndStgResistance 4820;
BA_ "SigType" SG_ 2633832958 DrvrArbgIgntrLp2ndStgResistance 1;
BA_ "SPN" SG_ 2633832958 PssngrArbgIgntrLp1stStgRsstance 4819;
BA_ "SigType" SG_ 2633832958 PssngrArbgIgntrLp1stStgRsstance 1;
BA_ "SPN" SG_ 2633832958 DrvrArbgIgntrLp1stStgResistance 4818;
BA_ "SigType" SG_ 2633832958 DrvrArbgIgntrLp1stStgResistance 1;
BA_ "SPN" SG_ 2566719998 HighResolutionEngTotalFuelUsed 5054;
BA_ "SigType" SG_ 2566719998 HighResolutionEngTotalFuelUsed 1;
BA_ "SPN" SG_ 2566719998 HighResolutionEngTripFuel 5053;
BA_ "SigType" SG_ 2566719998 HighResolutionEngTripFuel 1;
BA_ "SPN" SG_ 2565877502 EngTurboWastegateActuator2Cmd 5387;
BA_ "SigType" SG_ 2565877502 EngTurboWastegateActuator2Cmd 1;
BA_ "SPN" SG_ 2565877502 EngTurboWastegateActuator1Cmd 5386;
BA_ "SigType" SG_ 2565877502 EngTurboWastegateActuator1Cmd 1;
BA_ "SPN" SG_ 2566713854 EngTrbWstgtActtr2OprationStatus 5452;
BA_ "SigType" SG_ 2566713854 EngTrbWstgtActtr2OprationStatus 4;
BA_ "SPN" SG_ 2566713854 EngTrbWstgtActtr1OprationStatus 5451;
BA_ "SigType" SG_ 2566713854 EngTrbWstgtActtr1OprationStatus 4;
BA_ "SPN" SG_ 2566713854 EngTrbWstgteActuator2TempStatus 5385;
BA_ "SigType" SG_ 2566713854 EngTrbWstgteActuator2TempStatus 4;
BA_ "SPN" SG_ 2566713854 EngTrbWstgtActtr2PreliminaryFMI 5384;
BA_ "SigType" SG_ 2566713854 EngTrbWstgtActtr2PreliminaryFMI 1;
BA_ "SPN" SG_ 2566714366 EngTrbCmprssrBypssActtr2OprtnStt 5450;
BA_ "SigType" SG_ 2566714366 EngTrbCmprssrBypssActtr2OprtnStt 4;
BA_ "SystemSignalLongSymbol" SG_ 2566714366 EngTrbCmprssrBypssActtr2OprtnStt "EngTrbCmprssrBypssActtr2OprtnStts";
BA_ "SPN" SG_ 2566714366 EngTrbCmprssrBypssActtr1OprtnStt 5449;
BA_ "SigType" SG_ 2566714366 EngTrbCmprssrBypssActtr1OprtnStt 4;
BA_ "SystemSignalLongSymbol" SG_ 2566714366 EngTrbCmprssrBypssActtr1OprtnStt "EngTrbCmprssrBypssActtr1OprtnStts";
BA_ "SPN" SG_ 2566714366 EngTrbCmprssrBypssActtr2TmpStts 5391;
BA_ "SigType" SG_ 2566714366 EngTrbCmprssrBypssActtr2TmpStts 4;
BA_ "SPN" SG_ 2566714366 EngTrbCmprssrBypssActtr2PrlmnryF 5390;
BA_ "SigType" SG_ 2566714366 EngTrbCmprssrBypssActtr2PrlmnryF 1;
BA_ "SystemSignalLongSymbol" SG_ 2566714366 EngTrbCmprssrBypssActtr2PrlmnryF "EngTrbCmprssrBypssActtr2PrlmnryFMI";
BA_ "SPN" SG_ 2566714366 EngDsrdTrbCmprssrBypssActtr2Pos 5389;
BA_ "SigType" SG_ 2566714366 EngDsrdTrbCmprssrBypssActtr2Pos 1;
BA_ "SPN" SG_ 2566714366 EngTrbCmprssrBypassActuator2Pos 5388;
BA_ "SigType" SG_ 2566714366 EngTrbCmprssrBypassActuator2Pos 1;
BA_ "SPN" SG_ 2566714110 EngFuelValve2OperationStatus 5448;
BA_ "SigType" SG_ 2566714110 EngFuelValve2OperationStatus 4;
BA_ "SPN" SG_ 2566714110 EngFuelValve1OperationStatus 5447;
BA_ "SigType" SG_ 2566714110 EngFuelValve1OperationStatus 4;
BA_ "SPN" SG_ 2566714110 EngThrttleValve2OperationStatus 5446;
BA_ "SigType" SG_ 2566714110 EngThrttleValve2OperationStatus 4;
BA_ "SPN" SG_ 2566714110 EngThrttleValve1OperationStatus 5445;
BA_ "SigType" SG_ 2566714110 EngThrttleValve1OperationStatus 4;
BA_ "SPN" SG_ 2566714110 EngFuelValve2TempStatus 5383;
BA_ "SigType" SG_ 2566714110 EngFuelValve2TempStatus 4;
BA_ "SPN" SG_ 2566714110 EngFuelValve2PreliminaryFMI 5382;
BA_ "SigType" SG_ 2566714110 EngFuelValve2PreliminaryFMI 1;
BA_ "SPN" SG_ 2566714110 EngFuelValve1TempStatus 5381;
BA_ "SigType" SG_ 2566714110 EngFuelValve1TempStatus 4;
BA_ "SPN" SG_ 2566714110 EngFuelValve1PreliminaryFMI 5380;
BA_ "SigType" SG_ 2566714110 EngFuelValve1PreliminaryFMI 1;
BA_ "SPN" SG_ 2566714110 EngThrottleValve2TempStatus 5379;
BA_ "SigType" SG_ 2566714110 EngThrottleValve2TempStatus 4;
BA_ "SPN" SG_ 2566714110 EngThrottleValve2PreliminaryFMI 5378;
BA_ "SigType" SG_ 2566714110 EngThrottleValve2PreliminaryFMI 1;
BA_ "SPN" SG_ 2566714110 EngDesiredThrottleValve2Pos 5377;
BA_ "SigType" SG_ 2566714110 EngDesiredThrottleValve2Pos 1;
BA_ "SPN" SG_ 2566714110 EngThrottleValve1TempStatus 5376;
BA_ "SigType" SG_ 2566714110 EngThrottleValve1TempStatus 4;
BA_ "SPN" SG_ 2566714110 EngThrottleValve1PreliminaryFMI 5375;
BA_ "SigType" SG_ 2566714110 EngThrottleValve1PreliminaryFMI 1;
BA_ "SPN" SG_ 2566714110 EngDesiredThrottleValve1Pos 5374;
BA_ "SigType" SG_ 2566714110 EngDesiredThrottleValve1Pos 1;
BA_ "SPN" SG_ 2566717438 EngExhstGsRcrcltn2MxrIntakeTemp 5256;
BA_ "SigType" SG_ 2566717438 EngExhstGsRcrcltn2MxrIntakeTemp 1;
BA_ "SPN" SG_ 2566717438 EngExhaustGasRecirculation2Temp 5255;
BA_ "SigType" SG_ 2566717438 EngExhaustGasRecirculation2Temp 1;
BA_ "SPN" SG_ 2633828606 EngOilRelativeDielectricity 5468;
BA_ "SigType" SG_ 2633828606 EngOilRelativeDielectricity 1;
BA_ "SPN" SG_ 2633828606 EngOilDensity 5056;
BA_ "SigType" SG_ 2633828606 EngOilDensity 1;
BA_ "SPN" SG_ 2633828606 EngOilViscosity 5055;
BA_ "SigType" SG_ 2633828606 EngOilViscosity 1;
BA_ "SPN" SG_ 2499607550 EngExhstMnfldBnk2FlwBlncVlvActtr 5279;
BA_ "SigType" SG_ 2499607550 EngExhstMnfldBnk2FlwBlncVlvActtr 1;
BA_ "SystemSignalLongSymbol" SG_ 2499607550 EngExhstMnfldBnk2FlwBlncVlvActtr "EngExhstMnfldBnk2FlwBlncVlvActtrPs";
BA_ "SPN" SG_ 2499607550 EngExhstMnfldBnk1FlwBlncVlvActtr 5277;
BA_ "SigType" SG_ 2499607550 EngExhstMnfldBnk1FlwBlncVlvActtr 1;
BA_ "SystemSignalLongSymbol" SG_ 2499607550 EngExhstMnfldBnk1FlwBlncVlvActtr "EngExhstMnfldBnk1FlwBlncVlvActtrPs";
BA_ "SPN" SG_ 2633825534 EngExhstMnfldBnk2FlwBlncVlv_0000 5278;
BA_ "SigType" SG_ 2633825534 EngExhstMnfldBnk2FlwBlncVlv_0000 1;
BA_ "SystemSignalLongSymbol" SG_ 2633825534 EngExhstMnfldBnk2FlwBlncVlv_0000 "EngExhstMnfldBnk2FlwBlncVlvActtrCtrl";
BA_ "SPN" SG_ 2633825534 EngExhstMnfldBnk1FlwBlncVlv_0000 5276;
BA_ "SigType" SG_ 2633825534 EngExhstMnfldBnk1FlwBlncVlv_0000 1;
BA_ "SystemSignalLongSymbol" SG_ 2633825534 EngExhstMnfldBnk1FlwBlncVlv_0000 "EngExhstMnfldBnk1FlwBlncVlvActtrCtrl";
BA_ "SPN" SG_ 2365400574 Jystck9GripXAxisDetentPosStatus 4712;
BA_ "SigType" SG_ 2365400574 Jystck9GripXAxisDetentPosStatus 4;
BA_ "SPN" SG_ 2365400574 Jystck9GripYAxisDetentPosStatus 4711;
BA_ "SigType" SG_ 2365400574 Jystck9GripYAxisDetentPosStatus 4;
BA_ "SPN" SG_ 2365400574 Jystck9ThetaAxisDetentPosStatus 4710;
BA_ "SigType" SG_ 2365400574 Jystck9ThetaAxisDetentPosStatus 4;
BA_ "SPN" SG_ 2365400574 Joystick9ThetaAxisPos 4709;
BA_ "SigType" SG_ 2365400574 Joystick9ThetaAxisPos 1;
BA_ "SPN" SG_ 2365400574 Jystck9ThtAxsClckwsPstvPsStatus 4708;
BA_ "SigType" SG_ 2365400574 Jystck9ThtAxsClckwsPstvPsStatus 4;
BA_ "SPN" SG_ 2365400574 Jystck9ThtAxsCntrClckwsNgtvPsStt 4707;
BA_ "SigType" SG_ 2365400574 Jystck9ThtAxsCntrClckwsNgtvPsStt 4;
BA_ "SystemSignalLongSymbol" SG_ 2365400574 Jystck9ThtAxsCntrClckwsNgtvPsStt "Jystck9ThtAxsCntrClckwsNgtvPsStts";
BA_ "SPN" SG_ 2365400574 Jystck9ThtaAxisNeutralPosStatus 4706;
BA_ "SigType" SG_ 2365400574 Jystck9ThtaAxisNeutralPosStatus 4;
BA_ "SPN" SG_ 2365400574 Joystick9GripYAxisPos 4705;
BA_ "SigType" SG_ 2365400574 Joystick9GripYAxisPos 1;
BA_ "SPN" SG_ 2365400574 Jystck9GrpYAxsLvrFrwrdPstvPsStts 4704;
BA_ "SigType" SG_ 2365400574 Jystck9GrpYAxsLvrFrwrdPstvPsStts 4;
BA_ "SPN" SG_ 2365400574 Jystck9GrpYAxsLvrBckNgtvPsSttus 4703;
BA_ "SigType" SG_ 2365400574 Jystck9GrpYAxsLvrBckNgtvPsSttus 4;
BA_ "SPN" SG_ 2365400574 Jystck9GrpYAxisNeutralPosStatus 4702;
BA_ "SigType" SG_ 2365400574 Jystck9GrpYAxisNeutralPosStatus 4;
BA_ "SPN" SG_ 2365400574 Joystick9GripXAxisPos 4701;
BA_ "SigType" SG_ 2365400574 Joystick9GripXAxisPos 1;
BA_ "SPN" SG_ 2365400574 Jystck9GrpXAxsLvrRghtPstvPsStts 4700;
BA_ "SigType" SG_ 2365400574 Jystck9GrpXAxsLvrRghtPstvPsStts 4;
BA_ "SPN" SG_ 2365400574 Jystck9GrpXAxsLvrLftNgtvPsSttus 4699;
BA_ "SigType" SG_ 2365400574 Jystck9GrpXAxsLvrLftNgtvPsSttus 4;
BA_ "SPN" SG_ 2365400574 Jystck9GrpXAxisNeutralPosStatus 4698;
BA_ "SigType" SG_ 2365400574 Jystck9GrpXAxisNeutralPosStatus 4;
BA_ "SPN" SG_ 2365401086 Jystck8GripXAxisDetentPosStatus 4675;
BA_ "SigType" SG_ 2365401086 Jystck8GripXAxisDetentPosStatus 4;
BA_ "SPN" SG_ 2365401086 Jystck8GripYAxisDetentPosStatus 4674;
BA_ "SigType" SG_ 2365401086 Jystck8GripYAxisDetentPosStatus 4;
BA_ "SPN" SG_ 2365401086 Jystck8ThetaAxisDetentPosStatus 4673;
BA_ "SigType" SG_ 2365401086 Jystck8ThetaAxisDetentPosStatus 4;
BA_ "SPN" SG_ 2365401086 Joystick8ThetaAxisPos 4672;
BA_ "SigType" SG_ 2365401086 Joystick8ThetaAxisPos 1;
BA_ "SPN" SG_ 2365401086 Jystck8ThtAxsClckwsPstvPsStatus 4671;
BA_ "SigType" SG_ 2365401086 Jystck8ThtAxsClckwsPstvPsStatus 4;
BA_ "SPN" SG_ 2365401086 Jystck8ThtAxsCntrClckwsNgtvPsStt 4670;
BA_ "SigType" SG_ 2365401086 Jystck8ThtAxsCntrClckwsNgtvPsStt 4;
BA_ "SystemSignalLongSymbol" SG_ 2365401086 Jystck8ThtAxsCntrClckwsNgtvPsStt "Jystck8ThtAxsCntrClckwsNgtvPsStts";
BA_ "SPN" SG_ 2365401086 Jystck8ThtaAxisNeutralPosStatus 4669;
BA_ "SigType" SG_ 2365401086 Jystck8ThtaAxisNeutralPosStatus 4;
BA_ "SPN" SG_ 2365401086 Joystick8GripYAxisPos 4668;
BA_ "SigType" SG_ 2365401086 Joystick8GripYAxisPos 1;
BA_ "SPN" SG_ 2365401086 Jystck8GrpYAxsLvrFrwrdPstvPsStts 4667;
BA_ "SigType" SG_ 2365401086 Jystck8GrpYAxsLvrFrwrdPstvPsStts 4;
BA_ "SPN" SG_ 2365401086 Jystck8GrpYAxsLvrBckNgtvPsSttus 4666;
BA_ "SigType" SG_ 2365401086 Jystck8GrpYAxsLvrBckNgtvPsSttus 4;
BA_ "SPN" SG_ 2365401086 Jystck8GrpYAxisNeutralPosStatus 4665;
BA_ "SigType" SG_ 2365401086 Jystck8GrpYAxisNeutralPosStatus 4;
BA_ "SPN" SG_ 2365401086 Joystick8GripXAxisPos 4664;
BA_ "SigType" SG_ 2365401086 Joystick8GripXAxisPos 1;
BA_ "SPN" SG_ 2365401086 Jystck8GrpXAxsLvrRghtPstvPsStts 4663;
BA_ "SigType" SG_ 2365401086 Jystck8GrpXAxsLvrRghtPstvPsStts 4;
BA_ "SPN" SG_ 2365401086 Jystck8GrpXAxsLvrLftNgtvPsSttus 4662;
BA_ "SigType" SG_ 2365401086 Jystck8GrpXAxsLvrLftNgtvPsSttus 4;
BA_ "SPN" SG_ 2365401086 Jystck8GrpXAxisNeutralPosStatus 4661;
BA_ "SigType" SG_ 2365401086 Jystck8GrpXAxisNeutralPosStatus 4;
BA_ "SPN" SG_ 2365401598 Jystck7GripXAxisDetentPosStatus 4638;
BA_ "SigType" SG_ 2365401598 Jystck7GripXAxisDetentPosStatus 4;
BA_ "SPN" SG_ 2365401598 Jystck7GripYAxisDetentPosStatus 4637;
BA_ "SigType" SG_ 2365401598 Jystck7GripYAxisDetentPosStatus 4;
BA_ "SPN" SG_ 2365401598 Jystck7ThetaAxisDetentPosStatus 4636;
BA_ "SigType" SG_ 2365401598 Jystck7ThetaAxisDetentPosStatus 4;
BA_ "SPN" SG_ 2365401598 Joystick7ThetaAxisPos 4635;
BA_ "SigType" SG_ 2365401598 Joystick7ThetaAxisPos 1;
BA_ "SPN" SG_ 2365401598 Jystck7ThtAxsClckwsPstvPsStatus 4634;
BA_ "SigType" SG_ 2365401598 Jystck7ThtAxsClckwsPstvPsStatus 4;
BA_ "SPN" SG_ 2365401598 Jystck7ThtAxsCntrClckwsNgtvPsStt 4633;
BA_ "SigType" SG_ 2365401598 Jystck7ThtAxsCntrClckwsNgtvPsStt 4;
BA_ "SystemSignalLongSymbol" SG_ 2365401598 Jystck7ThtAxsCntrClckwsNgtvPsStt "Jystck7ThtAxsCntrClckwsNgtvPsStts";
BA_ "SPN" SG_ 2365401598 Jystck7ThtaAxisNeutralPosStatus 4632;
BA_ "SigType" SG_ 2365401598 Jystck7ThtaAxisNeutralPosStatus 4;
BA_ "SPN" SG_ 2365401598 Joystick7GripYAxisPos 4631;
BA_ "SigType" SG_ 2365401598 Joystick7GripYAxisPos 1;
BA_ "SPN" SG_ 2365401598 Jystck7GrpYAxsLvrFrwrdPstvPsStts 4630;
BA_ "SigType" SG_ 2365401598 Jystck7GrpYAxsLvrFrwrdPstvPsStts 4;
BA_ "SPN" SG_ 2365401598 Jystck7GrpYAxsLvrBckNgtvPsSttus 4629;
BA_ "SigType" SG_ 2365401598 Jystck7GrpYAxsLvrBckNgtvPsSttus 4;
BA_ "SPN" SG_ 2365401598 Jystck7GrpYAxisNeutralPosStatus 4628;
BA_ "SigType" SG_ 2365401598 Jystck7GrpYAxisNeutralPosStatus 4;
BA_ "SPN" SG_ 2365401598 Joystick7GripXAxisPos 4627;
BA_ "SigType" SG_ 2365401598 Joystick7GripXAxisPos 1;
BA_ "SPN" SG_ 2365401598 Jystck7GrpXAxsLvrRghtPstvPsStts 4626;
BA_ "SigType" SG_ 2365401598 Jystck7GrpXAxsLvrRghtPstvPsStts 4;
BA_ "SPN" SG_ 2365401598 Jystck7GrpXAxsLvrLftNgtvPsSttus 4625;
BA_ "SigType" SG_ 2365401598 Jystck7GrpXAxsLvrLftNgtvPsSttus 4;
BA_ "SPN" SG_ 2365401598 Jystck7GrpXAxisNeutralPosStatus 4624;
BA_ "SigType" SG_ 2365401598 Jystck7GrpXAxisNeutralPosStatus 4;
BA_ "SPN" SG_ 2365402110 Jystck6GripXAxisDetentPosStatus 4601;
BA_ "SigType" SG_ 2365402110 Jystck6GripXAxisDetentPosStatus 4;
BA_ "SPN" SG_ 2365402110 Jystck6GripYAxisDetentPosStatus 4600;
BA_ "SigType" SG_ 2365402110 Jystck6GripYAxisDetentPosStatus 4;
BA_ "SPN" SG_ 2365402110 Jystck6ThetaAxisDetentPosStatus 4599;
BA_ "SigType" SG_ 2365402110 Jystck6ThetaAxisDetentPosStatus 4;
BA_ "SPN" SG_ 2365402110 Joystick6ThetaAxisPos 4598;
BA_ "SigType" SG_ 2365402110 Joystick6ThetaAxisPos 1;
BA_ "SPN" SG_ 2365402110 Jystck6ThtAxsClckwsPstvPsStatus 4597;
BA_ "SigType" SG_ 2365402110 Jystck6ThtAxsClckwsPstvPsStatus 4;
BA_ "SPN" SG_ 2365402110 Jystck6ThtAxsCntrClckwsNgtvPsStt 4596;
BA_ "SigType" SG_ 2365402110 Jystck6ThtAxsCntrClckwsNgtvPsStt 4;
BA_ "SystemSignalLongSymbol" SG_ 2365402110 Jystck6ThtAxsCntrClckwsNgtvPsStt "Jystck6ThtAxsCntrClckwsNgtvPsStts";
BA_ "SPN" SG_ 2365402110 Jystck6ThtaAxisNeutralPosStatus 4595;
BA_ "SigType" SG_ 2365402110 Jystck6ThtaAxisNeutralPosStatus 4;
BA_ "SPN" SG_ 2365402110 Joystick6GripYAxisPos 4594;
BA_ "SigType" SG_ 2365402110 Joystick6GripYAxisPos 1;
BA_ "SPN" SG_ 2365402110 Jystck6GrpYAxsLvrFrwrdPstvPsStts 4593;
BA_ "SigType" SG_ 2365402110 Jystck6GrpYAxsLvrFrwrdPstvPsStts 4;
BA_ "SPN" SG_ 2365402110 Jystck6GrpYAxsLvrBckNgtvPsSttus 4592;
BA_ "SigType" SG_ 2365402110 Jystck6GrpYAxsLvrBckNgtvPsSttus 4;
BA_ "SPN" SG_ 2365402110 Jystck6GrpYAxisNeutralPosStatus 4591;
BA_ "SigType" SG_ 2365402110 Jystck6GrpYAxisNeutralPosStatus 4;
BA_ "SPN" SG_ 2365402110 Joystick6GripXAxisPos 4590;
BA_ "SigType" SG_ 2365402110 Joystick6GripXAxisPos 1;
BA_ "SPN" SG_ 2365402110 Jystck6GrpXAxsLvrRghtPstvPsStts 4589;
BA_ "SigType" SG_ 2365402110 Jystck6GrpXAxsLvrRghtPstvPsStts 4;
BA_ "SPN" SG_ 2365402110 Jystck6GrpXAxsLvrLftNgtvPsSttus 4588;
BA_ "SigType" SG_ 2365402110 Jystck6GrpXAxsLvrLftNgtvPsSttus 4;
BA_ "SPN" SG_ 2365402110 Jystck6GrpXAxisNeutralPosStatus 4587;
BA_ "SigType" SG_ 2365402110 Jystck6GrpXAxisNeutralPosStatus 4;
BA_ "SPN" SG_ 2365402622 Jystck5GripXAxisDetentPosStatus 4564;
BA_ "SigType" SG_ 2365402622 Jystck5GripXAxisDetentPosStatus 4;
BA_ "SPN" SG_ 2365402622 Jystck5GripYAxisDetentPosStatus 4563;
BA_ "SigType" SG_ 2365402622 Jystck5GripYAxisDetentPosStatus 4;
BA_ "SPN" SG_ 2365402622 Jystck5ThetaAxisDetentPosStatus 4562;
BA_ "SigType" SG_ 2365402622 Jystck5ThetaAxisDetentPosStatus 4;
BA_ "SPN" SG_ 2365402622 Joystick5ThetaAxisPos 4561;
BA_ "SigType" SG_ 2365402622 Joystick5ThetaAxisPos 1;
BA_ "SPN" SG_ 2365402622 Jystck5ThtAxsClckwsPstvPsStatus 4560;
BA_ "SigType" SG_ 2365402622 Jystck5ThtAxsClckwsPstvPsStatus 4;
BA_ "SPN" SG_ 2365402622 Jystck5ThtAxsCntrClckwsNgtvPsStt 4559;
BA_ "SigType" SG_ 2365402622 Jystck5ThtAxsCntrClckwsNgtvPsStt 4;
BA_ "SystemSignalLongSymbol" SG_ 2365402622 Jystck5ThtAxsCntrClckwsNgtvPsStt "Jystck5ThtAxsCntrClckwsNgtvPsStts";
BA_ "SPN" SG_ 2365402622 Jystck5ThtaAxisNeutralPosStatus 4558;
BA_ "SigType" SG_ 2365402622 Jystck5ThtaAxisNeutralPosStatus 4;
BA_ "SPN" SG_ 2365402622 Joystick5GripYAxisPos 4557;
BA_ "SigType" SG_ 2365402622 Joystick5GripYAxisPos 1;
BA_ "SPN" SG_ 2365402622 Jystck5GrpYAxsLvrFrwrdPstvPsStts 4556;
BA_ "SigType" SG_ 2365402622 Jystck5GrpYAxsLvrFrwrdPstvPsStts 4;
BA_ "SPN" SG_ 2365402622 Jystck5GrpYAxsLvrBckNgtvPsSttus 4555;
BA_ "SigType" SG_ 2365402622 Jystck5GrpYAxsLvrBckNgtvPsSttus 4;
BA_ "SPN" SG_ 2365402622 Jystck5GrpYAxisNeutralPosStatus 4554;
BA_ "SigType" SG_ 2365402622 Jystck5GrpYAxisNeutralPosStatus 4;
BA_ "SPN" SG_ 2365402622 Joystick5GripXAxisPos 4553;
BA_ "SigType" SG_ 2365402622 Joystick5GripXAxisPos 1;
BA_ "SPN" SG_ 2365402622 Jystck5GrpXAxsLvrRghtPstvPsStts 4552;
BA_ "SigType" SG_ 2365402622 Jystck5GrpXAxsLvrRghtPstvPsStts 4;
BA_ "SPN" SG_ 2365402622 Jystck5GrpXAxsLvrLftNgtvPsSttus 4551;
BA_ "SigType" SG_ 2365402622 Jystck5GrpXAxsLvrLftNgtvPsSttus 4;
BA_ "SPN" SG_ 2365402622 Jystck5GrpXAxisNeutralPosStatus 4550;
BA_ "SigType" SG_ 2365402622 Jystck5GrpXAxisNeutralPosStatus 4;
BA_ "SPN" SG_ 2365403134 Jystck4GripXAxisDetentPosStatus 4527;
BA_ "SigType" SG_ 2365403134 Jystck4GripXAxisDetentPosStatus 4;
BA_ "SPN" SG_ 2365403134 Jystck4GripYAxisDetentPosStatus 4526;
BA_ "SigType" SG_ 2365403134 Jystck4GripYAxisDetentPosStatus 4;
BA_ "SPN" SG_ 2365403134 Jystck4ThetaAxisDetentPosStatus 4525;
BA_ "SigType" SG_ 2365403134 Jystck4ThetaAxisDetentPosStatus 4;
BA_ "SPN" SG_ 2365403134 Joystick4ThetaAxisPos 4524;
BA_ "SigType" SG_ 2365403134 Joystick4ThetaAxisPos 1;
BA_ "SPN" SG_ 2365403134 Jystck4ThtAxsClckwsPstvPsStatus 4523;
BA_ "SigType" SG_ 2365403134 Jystck4ThtAxsClckwsPstvPsStatus 4;
BA_ "SPN" SG_ 2365403134 Jystck4ThtAxsCntrClckwsNgtvPsStt 4522;
BA_ "SigType" SG_ 2365403134 Jystck4ThtAxsCntrClckwsNgtvPsStt 4;
BA_ "SystemSignalLongSymbol" SG_ 2365403134 Jystck4ThtAxsCntrClckwsNgtvPsStt "Jystck4ThtAxsCntrClckwsNgtvPsStts";
BA_ "SPN" SG_ 2365403134 Jystck4ThtaAxisNeutralPosStatus 4521;
BA_ "SigType" SG_ 2365403134 Jystck4ThtaAxisNeutralPosStatus 4;
BA_ "SPN" SG_ 2365403134 Joystick4GripYAxisPos 4520;
BA_ "SigType" SG_ 2365403134 Joystick4GripYAxisPos 1;
BA_ "SPN" SG_ 2365403134 Jystck4GrpYAxsLvrFrwrdPstvPsStts 4519;
BA_ "SigType" SG_ 2365403134 Jystck4GrpYAxsLvrFrwrdPstvPsStts 4;
BA_ "SPN" SG_ 2365403134 Jystck4GrpYAxsLvrBckNgtvPsSttus 4518;
BA_ "SigType" SG_ 2365403134 Jystck4GrpYAxsLvrBckNgtvPsSttus 4;
BA_ "SPN" SG_ 2365403134 Jystck4GrpYAxisNeutralPosStatus 4517;
BA_ "SigType" SG_ 2365403134 Jystck4GrpYAxisNeutralPosStatus 4;
BA_ "SPN" SG_ 2365403134 Joystick4GripXAxisPos 4516;
BA_ "SigType" SG_ 2365403134 Joystick4GripXAxisPos 1;
BA_ "SPN" SG_ 2365403134 Jystck4GrpXAxsLvrRghtPstvPsStts 4515;
BA_ "SigType" SG_ 2365403134 Jystck4GrpXAxsLvrRghtPstvPsStts 4;
BA_ "SPN" SG_ 2365403134 Jystck4GrpXAxsLvrLftNgtvPsSttus 4514;
BA_ "SigType" SG_ 2365403134 Jystck4GrpXAxsLvrLftNgtvPsSttus 4;
BA_ "SPN" SG_ 2365403134 Jystck4GrpXAxisNeutralPosStatus 4513;
BA_ "SigType" SG_ 2365403134 Jystck4GrpXAxisNeutralPosStatus 4;
BA_ "SPN" SG_ 2365400062 Jystck10GrpXAxisDetentPosStatus 4749;
BA_ "SigType" SG_ 2365400062 Jystck10GrpXAxisDetentPosStatus 4;
BA_ "SPN" SG_ 2365400062 Jystck10GrpYAxisDetentPosStatus 4748;
BA_ "SigType" SG_ 2365400062 Jystck10GrpYAxisDetentPosStatus 4;
BA_ "SPN" SG_ 2365400062 Jystck10ThtaAxisDetentPosStatus 4747;
BA_ "SigType" SG_ 2365400062 Jystck10ThtaAxisDetentPosStatus 4;
BA_ "SPN" SG_ 2365400062 Joystick10ThetaAxisPos 4746;
BA_ "SigType" SG_ 2365400062 Joystick10ThetaAxisPos 1;
BA_ "SPN" SG_ 2365400062 Jystck10ThtAxsClckwsPstvPsSttus 4745;
BA_ "SigType" SG_ 2365400062 Jystck10ThtAxsClckwsPstvPsSttus 4;
BA_ "SPN" SG_ 2365400062 Jystck10ThtAxsCntrClckwsNgtvPsSt 4744;
BA_ "SigType" SG_ 2365400062 Jystck10ThtAxsCntrClckwsNgtvPsSt 4;
BA_ "SystemSignalLongSymbol" SG_ 2365400062 Jystck10ThtAxsCntrClckwsNgtvPsSt "Jystck10ThtAxsCntrClckwsNgtvPsStts";
BA_ "SPN" SG_ 2365400062 Jystck10ThtAxisNeutralPosStatus 4743;
BA_ "SigType" SG_ 2365400062 Jystck10ThtAxisNeutralPosStatus 4;
BA_ "SPN" SG_ 2365400062 Joystick10GripYAxisPos 4742;
BA_ "SigType" SG_ 2365400062 Joystick10GripYAxisPos 1;
BA_ "SPN" SG_ 2365400062 Jystck10GrpYAxsLvrFrwrdPstvPsStt 4741;
BA_ "SigType" SG_ 2365400062 Jystck10GrpYAxsLvrFrwrdPstvPsStt 4;
BA_ "SystemSignalLongSymbol" SG_ 2365400062 Jystck10GrpYAxsLvrFrwrdPstvPsStt "Jystck10GrpYAxsLvrFrwrdPstvPsStts";
BA_ "SPN" SG_ 2365400062 Jystck10GrpYAxsLvrBckNgtvPsStts 4740;
BA_ "SigType" SG_ 2365400062 Jystck10GrpYAxsLvrBckNgtvPsStts 4;
BA_ "SPN" SG_ 2365400062 Jystck10GrpYAxsNeutralPosStatus 4739;
BA_ "SigType" SG_ 2365400062 Jystck10GrpYAxsNeutralPosStatus 4;
BA_ "SPN" SG_ 2365400062 Joystick10GripXAxisPos 4738;
BA_ "SigType" SG_ 2365400062 Joystick10GripXAxisPos 1;
BA_ "SPN" SG_ 2365400062 Jystck10GrpXAxsLvrRghtPstvPsStts 4737;
BA_ "SigType" SG_ 2365400062 Jystck10GrpXAxsLvrRghtPstvPsStts 4;
BA_ "SPN" SG_ 2365400062 Jystck10GrpXAxsLvrLftNgtvPsStts 4736;
BA_ "SigType" SG_ 2365400062 Jystck10GrpXAxsLvrLftNgtvPsStts 4;
BA_ "SPN" SG_ 2365400062 Jystck10GrpXAxsNeutralPosStatus 4735;
BA_ "SigType" SG_ 2365400062 Jystck10GrpXAxsNeutralPosStatus 4;
BA_ "SPN" SG_ 2566713598 EngFuelFilterIntakeAbsPress 5417;
BA_ "SigType" SG_ 2566713598 EngFuelFilterIntakeAbsPress 1;
BA_ "SPN" SG_ 2499604478 EngExhstGsRcrcltn1IntkeAbsPress 5430;
BA_ "SigType" SG_ 2499604478 EngExhstGsRcrcltn1IntkeAbsPress 1;
BA_ "SPN" SG_ 2499608830 EngExhstGsRcrcltn2IntkeAbsPress 5429;
BA_ "SigType" SG_ 2499608830 EngExhstGsRcrcltn2IntkeAbsPress 1;
BA_ "SPN" SG_ 2499608830 EngExhstGsRcrcltn2OtletAbsPress 5254;
BA_ "SigType" SG_ 2499608830 EngExhstGsRcrcltn2OtletAbsPress 1;
BA_ "SPN" SG_ 2499608830 EngExhstGsRcrcltion2IntakePress 5253;
BA_ "SigType" SG_ 2499608830 EngExhstGsRcrcltion2IntakePress 1;
BA_ "SPN" SG_ 2499608830 EngExhstGsRcrculation2DiffPress 5252;
BA_ "SigType" SG_ 2499608830 EngExhstGsRcrculation2DiffPress 1;
BA_ "SPN" SG_ 2432499198 CmdedEngFuelInjectionCtrlPress 5314;
BA_ "SigType" SG_ 2432499198 CmdedEngFuelInjectionCtrlPress 1;
BA_ "SPN" SG_ 2432499198 CmdedEngFuelRailPress 5313;
BA_ "SigType" SG_ 2432499198 CmdedEngFuelRailPress 1;
BA_ "SPN" SG_ 2432499198 EngExhstGsRcrculation2Valve2Pos 5263;
BA_ "SigType" SG_ 2432499198 EngExhstGsRcrculation2Valve2Pos 1;
BA_ "SPN" SG_ 2432499198 EngExhstGsRcirculation2ValvePos 5262;
BA_ "SigType" SG_ 2432499198 EngExhstGsRcirculation2ValvePos 1;
BA_ "SPN" SG_ 2633825022 EngExhstGsRcrclation2Valve2Ctrl 5265;
BA_ "SigType" SG_ 2633825022 EngExhstGsRcrclation2Valve2Ctrl 1;
BA_ "SPN" SG_ 2633825022 EngExhstGsRcrculation2ValveCtrl 5264;
BA_ "SigType" SG_ 2633825022 EngExhstGsRcrculation2ValveCtrl 1;
BA_ "SPN" SG_ 2633826046 EGR2CoolerBypassActuatorPos 5261;
BA_ "SigType" SG_ 2633826046 EGR2CoolerBypassActuatorPos 1;
BA_ "SPN" SG_ 2633826046 EngExhstGsRcrcltn2ClrEfficiency 5260;
BA_ "SigType" SG_ 2633826046 EngExhstGsRcrcltn2ClrEfficiency 1;
BA_ "SPN" SG_ 2633826046 EngExhstGsRcrcltn2ClrIntkGsAbsPr 5259;
BA_ "SigType" SG_ 2633826046 EngExhstGsRcrcltn2ClrIntkGsAbsPr 1;
BA_ "SystemSignalLongSymbol" SG_ 2633826046 EngExhstGsRcrcltn2ClrIntkGsAbsPr "EngExhstGsRcrcltn2ClrIntkGsAbsPrss";
BA_ "SPN" SG_ 2633826046 EngExhstGsRcrcltn2ClrIntakeTemp 5258;
BA_ "SigType" SG_ 2633826046 EngExhstGsRcrcltn2ClrIntakeTemp 1;
BA_ "SPN" SG_ 2566711294 EngFrctnPrcntTorqueAtIdlePoint7 5477;
BA_ "SigType" SG_ 2566711294 EngFrctnPrcntTorqueAtIdlePoint7 1;
BA_ "SPN" SG_ 2566711294 EngFrctnPrcntTorqueAtIdlePoint6 5476;
BA_ "SigType" SG_ 2566711294 EngFrctnPrcntTorqueAtIdlePoint6 1;
BA_ "SPN" SG_ 2566711294 EngFrctnPrcntTorqueAtIdlePoint5 5475;
BA_ "SigType" SG_ 2566711294 EngFrctnPrcntTorqueAtIdlePoint5 1;
BA_ "SPN" SG_ 2566711294 EngFrctnPrcntTorqueAtIdlePoint4 5474;
BA_ "SigType" SG_ 2566711294 EngFrctnPrcntTorqueAtIdlePoint4 1;
BA_ "SPN" SG_ 2566711294 EngFrctnPrcntTorqueAtIdlePoint3 5473;
BA_ "SigType" SG_ 2566711294 EngFrctnPrcntTorqueAtIdlePoint3 1;
BA_ "SPN" SG_ 2566711294 EngFrctnPrcntTorqueAtIdlePoint2 5472;
BA_ "SigType" SG_ 2566711294 EngFrctnPrcntTorqueAtIdlePoint2 1;
BA_ "SPN" SG_ 2566711294 EngFrctnPrcntTorqueAtIdlePoint1 5471;
BA_ "SigType" SG_ 2566711294 EngFrctnPrcntTorqueAtIdlePoint1 1;
BA_ "SPN" SG_ 2566749438 DslPrtcltFltrActvRgnrtnFrcdStts 4175;
BA_ "SigType" SG_ 2566749438 DslPrtcltFltrActvRgnrtnFrcdStts 4;
BA_ "SPN" SG_ 2566749438 ExhaustSystemHighTempLampCmd 3698;
BA_ "SigType" SG_ 2566749438 ExhaustSystemHighTempLampCmd 4;
BA_ "SPN" SG_ 2566749438 DslPrtcltFltrAtmtcActvRgnrtnIntt 3718;
BA_ "SigType" SG_ 2566749438 DslPrtcltFltrAtmtcActvRgnrtnIntt 4;
BA_ "SystemSignalLongSymbol" SG_ 2566749438 DslPrtcltFltrAtmtcActvRgnrtnIntt "DslPrtcltFltrAtmtcActvRgnrtnInttnCnfg";
BA_ "SPN" SG_ 2566749438 DslPrtcltFltrActvRgnrtnInhbtdDTV 3717;
BA_ "SigType" SG_ 2566749438 DslPrtcltFltrActvRgnrtnInhbtdDTV 4;
BA_ "SystemSignalLongSymbol" SG_ 2566749438 DslPrtcltFltrActvRgnrtnInhbtdDTV "DslPrtcltFltrActvRgnrtnInhbtdDTVhclSpdBlwAllwd";
BA_ "SPN" SG_ 2566749438 DslPrtcltFltrActvRgnrtnInhbtdDTE 3716;
BA_ "SigType" SG_ 2566749438 DslPrtcltFltrActvRgnrtnInhbtdDTE 4;
BA_ "SystemSignalLongSymbol" SG_ 2566749438 DslPrtcltFltrActvRgnrtnInhbtdDTE "DslPrtcltFltrActvRgnrtnInhbtdDTEngNtWrmdUp";
BA_ "SPN" SG_ 2566749438 DslPrtcltFltrActvRgnrtnInhbtdDTP 3715;
BA_ "SigType" SG_ 2566749438 DslPrtcltFltrActvRgnrtnInhbtdDTP 4;
BA_ "SystemSignalLongSymbol" SG_ 2566749438 DslPrtcltFltrActvRgnrtnInhbtdDTP "DslPrtcltFltrActvRgnrtnInhbtdDTPrmnntSystmLckt";
BA_ "SPN" SG_ 2566749438 DslPrtcltFltrActvRgnrtnInhbtdDTT 3714;
BA_ "SigType" SG_ 2566749438 DslPrtcltFltrActvRgnrtnInhbtdDTT 4;
BA_ "SystemSignalLongSymbol" SG_ 2566749438 DslPrtcltFltrActvRgnrtnInhbtdDTT "DslPrtcltFltrActvRgnrtnInhbtdDTTmprrySystmLckt";
BA_ "SPN" SG_ 2566749438 DslPrtcltFltrActvRgnrtnInhbtdDTS 3713;
BA_ "SigType" SG_ 2566749438 DslPrtcltFltrActvRgnrtnInhbtdDTS 4;
BA_ "SystemSignalLongSymbol" SG_ 2566749438 DslPrtcltFltrActvRgnrtnInhbtdDTS "DslPrtcltFltrActvRgnrtnInhbtdDTSystmTmt";
BA_ "SPN" SG_ 2566749438 DslPrtcltFltrActvRgnrtnInhb_0000 3712;
BA_ "SigType" SG_ 2566749438 DslPrtcltFltrActvRgnrtnInhb_0000 4;
BA_ "SystemSignalLongSymbol" SG_ 2566749438 DslPrtcltFltrActvRgnrtnInhb_0000 "DslPrtcltFltrActvRgnrtnInhbtdDTSystmFltActv";
BA_ "SPN" SG_ 2566749438 DslPrtcltFltrActvRgnrtnInhbtdDTL 3711;
BA_ "SigType" SG_ 2566749438 DslPrtcltFltrActvRgnrtnInhbtdDTL 4;
BA_ "SystemSignalLongSymbol" SG_ 2566749438 DslPrtcltFltrActvRgnrtnInhbtdDTL "DslPrtcltFltrActvRgnrtnInhbtdDTLwExhstGsTmp";
BA_ "SPN" SG_ 2566749438 DslPrtcltFltrActvRgnrtnInhb_0001 3710;
BA_ "SigType" SG_ 2566749438 DslPrtcltFltrActvRgnrtnInhb_0001 4;
BA_ "SystemSignalLongSymbol" SG_ 2566749438 DslPrtcltFltrActvRgnrtnInhb_0001 "DslPrtcltFltrActvRgnrtnInhbtdDTPrkngBrkNtSt";
BA_ "SPN" SG_ 2566749438 DslPrtcltFltrActvRgnrtnInhb_0002 3709;
BA_ "SigType" SG_ 2566749438 DslPrtcltFltrActvRgnrtnInhb_0002 4;
BA_ "SystemSignalLongSymbol" SG_ 2566749438 DslPrtcltFltrActvRgnrtnInhb_0002 "DslPrtcltFltrActvRgnrtnInhbtdDTVhclSpdAbvAllwd";
BA_ "SPN" SG_ 2566749438 DslPrtcltFltrActvRgnrtnInhbtdDTO 3708;
BA_ "SigType" SG_ 2566749438 DslPrtcltFltrActvRgnrtnInhbtdDTO 4;
BA_ "SystemSignalLongSymbol" SG_ 2566749438 DslPrtcltFltrActvRgnrtnInhbtdDTO "DslPrtcltFltrActvRgnrtnInhbtdDTOtOfNtrl";
BA_ "SPN" SG_ 2566749438 DslPrtcltFltrActvRgnrtnInhbtdDTA 3707;
BA_ "SigType" SG_ 2566749438 DslPrtcltFltrActvRgnrtnInhbtdDTA 4;
BA_ "SystemSignalLongSymbol" SG_ 2566749438 DslPrtcltFltrActvRgnrtnInhbtdDTA "DslPrtcltFltrActvRgnrtnInhbtdDTAcclPdlOffIdl";
BA_ "SPN" SG_ 2566749438 DslPrtcltFltrActvRgnrtnInhb_0003 3706;
BA_ "SigType" SG_ 2566749438 DslPrtcltFltrActvRgnrtnInhb_0003 4;
BA_ "SystemSignalLongSymbol" SG_ 2566749438 DslPrtcltFltrActvRgnrtnInhb_0003 "DslPrtcltFltrActvRgnrtnInhbtdDTPTOActv";
BA_ "SPN" SG_ 2566749438 DslPrtcltFltrActvRgnrtnInhb_0004 3705;
BA_ "SigType" SG_ 2566749438 DslPrtcltFltrActvRgnrtnInhb_0004 4;
BA_ "SystemSignalLongSymbol" SG_ 2566749438 DslPrtcltFltrActvRgnrtnInhb_0004 "DslPrtcltFltrActvRgnrtnInhbtdDTSrvcBrkActv";
BA_ "SPN" SG_ 2566749438 DslPrtcltFltrActvRgnrtnInhbtdDTC 3704;
BA_ "SigType" SG_ 2566749438 DslPrtcltFltrActvRgnrtnInhbtdDTC 4;
BA_ "SystemSignalLongSymbol" SG_ 2566749438 DslPrtcltFltrActvRgnrtnInhbtdDTC "DslPrtcltFltrActvRgnrtnInhbtdDTCltchDsnggd";
BA_ "SPN" SG_ 2566749438 DslPrtcltFltrActvRgnrtnInhbtdDTI 3703;
BA_ "SigType" SG_ 2566749438 DslPrtcltFltrActvRgnrtnInhbtdDTI 4;
BA_ "SystemSignalLongSymbol" SG_ 2566749438 DslPrtcltFltrActvRgnrtnInhbtdDTI "DslPrtcltFltrActvRgnrtnInhbtdDTInhbtSwtch";
BA_ "SPN" SG_ 2566749438 DslPrtcltFltrActvRgnrtnInhbtdStt 3702;
BA_ "SigType" SG_ 2566749438 DslPrtcltFltrActvRgnrtnInhbtdStt 4;
BA_ "SystemSignalLongSymbol" SG_ 2566749438 DslPrtcltFltrActvRgnrtnInhbtdStt "DslPrtcltFltrActvRgnrtnInhbtdStts";
BA_ "SPN" SG_ 2566749438 DieselParticulateFilterStatus 3701;
BA_ "SigType" SG_ 2566749438 DieselParticulateFilterStatus 4;
BA_ "SPN" SG_ 2566749438 DslPrtcltFltrActvRgnrtionStatus 3700;
BA_ "SigType" SG_ 2566749438 DslPrtcltFltrActvRgnrtionStatus 4;
BA_ "SPN" SG_ 2566749438 DslPrtcltFltrPssvRgnrtionStatus 3699;
BA_ "SigType" SG_ 2566749438 DslPrtcltFltrPssvRgnrtionStatus 4;
BA_ "SPN" SG_ 2566749438 DieselParticulateFilterLampCmd 3697;
BA_ "SigType" SG_ 2566749438 DieselParticulateFilterLampCmd 4;
BA_ "SPN" SG_ 2566715646 DslPrtclateFilter2SootSignalMin 5271;
BA_ "SigType" SG_ 2566715646 DslPrtclateFilter2SootSignalMin 1;
BA_ "SPN" SG_ 2566715646 DslPrtclateFilter2SootSignalMax 5270;
BA_ "SigType" SG_ 2566715646 DslPrtclateFilter2SootSignalMax 1;
BA_ "SPN" SG_ 2566715646 DslPrtcltFltr2StSgnlStndrdDvton 5269;
BA_ "SigType" SG_ 2566715646 DslPrtcltFltr2StSgnlStndrdDvton 1;
BA_ "SPN" SG_ 2566724606 DslPrtcltFltr2StSnsrPrlmnaryFMI 4790;
BA_ "SigType" SG_ 2566724606 DslPrtcltFltr2StSnsrPrlmnaryFMI 1;
BA_ "SPN" SG_ 2566724606 DslPrtcltFlter2MedianSootSignal 4789;
BA_ "SigType" SG_ 2566724606 DslPrtcltFlter2MedianSootSignal 1;
BA_ "SPN" SG_ 2566724606 DslPrtclteFilter2MeanSootSignal 4788;
BA_ "SigType" SG_ 2566724606 DslPrtclteFilter2MeanSootSignal 1;
BA_ "SPN" SG_ 2566724606 DslPrticulateFilter2SootDensity 4787;
BA_ "SigType" SG_ 2566724606 DslPrticulateFilter2SootDensity 1;
BA_ "SPN" SG_ 2566724606 DeselParticulateFilter2SootMass 4786;
BA_ "SigType" SG_ 2566724606 DeselParticulateFilter2SootMass 1;
BA_ "SPN" SG_ 2566715902 DslPrtclateFilter1SootSignalMin 5268;
BA_ "SigType" SG_ 2566715902 DslPrtclateFilter1SootSignalMin 1;
BA_ "SPN" SG_ 2566715902 DslPrtclateFilter1SootSignalMax 5267;
BA_ "SigType" SG_ 2566715902 DslPrtclateFilter1SootSignalMax 1;
BA_ "SPN" SG_ 2566715902 DslPrtcltFltr1StSgnlStndrdDvton 5266;
BA_ "SigType" SG_ 2566715902 DslPrtcltFltr1StSgnlStndrdDvton 1;
BA_ "SPN" SG_ 2566724862 DslPrtcltFltr1StSnsrPrlmnaryFMI 4785;
BA_ "SigType" SG_ 2566724862 DslPrtcltFltr1StSnsrPrlmnaryFMI 1;
BA_ "SPN" SG_ 2566724862 DslPrtcltFlter1MedianSootSignal 4784;
BA_ "SigType" SG_ 2566724862 DslPrtcltFlter1MedianSootSignal 1;
BA_ "SPN" SG_ 2566724862 DslPrtclteFilter1MeanSootSignal 4783;
BA_ "SigType" SG_ 2566724862 DslPrtclteFilter1MeanSootSignal 1;
BA_ "SPN" SG_ 2566724862 DslPrticulateFilter1SootDensity 4782;
BA_ "SigType" SG_ 2566724862 DslPrticulateFilter1SootDensity 1;
BA_ "SPN" SG_ 2566724862 DeselParticulateFilter1SootMass 4781;
BA_ "SigType" SG_ 2566724862 DeselParticulateFilter1SootMass 1;
BA_ "SPN" SG_ 2566718718 VehicleBatteryChargingLampData 5108;
BA_ "SigType" SG_ 2566718718 VehicleBatteryChargingLampData 4;
BA_ "SPN" SG_ 2566718718 VhicleHVACRecirculationLampData 5107;
BA_ "SigType" SG_ 2566718718 VhicleHVACRecirculationLampData 4;
BA_ "SPN" SG_ 2566718718 VehicleAirPressLowLampData 5106;
BA_ "SigType" SG_ 2566718718 VehicleAirPressLowLampData 4;
BA_ "SPN" SG_ 2566718718 VehicleFuelLevelLowLampData 5105;
BA_ "SigType" SG_ 2566718718 VehicleFuelLevelLowLampData 4;
BA_ "SPN" SG_ 2566718718 VhicleBatteryVoltageLowLampData 5104;
BA_ "SigType" SG_ 2566718718 VhicleBatteryVoltageLowLampData 4;
BA_ "SPN" SG_ 2566718974 EngWaitToStartLampData 5416;
BA_ "SigType" SG_ 2566718974 EngWaitToStartLampData 4;
BA_ "SPN" SG_ 2566718974 EngFuelFilterRestrictedLampData 5470;
BA_ "SigType" SG_ 2566718974 EngFuelFilterRestrictedLampData 4;
BA_ "SPN" SG_ 2566718974 EngAirFilterRestrictionLampData 5103;
BA_ "SigType" SG_ 2566718974 EngAirFilterRestrictionLampData 4;
BA_ "SPN" SG_ 2566718974 EngIdleManagementActiveLampData 5102;
BA_ "SigType" SG_ 2566718974 EngIdleManagementActiveLampData 4;
BA_ "SPN" SG_ 2566718974 EngCoolantLevelLowLampData 5101;
BA_ "SigType" SG_ 2566718974 EngCoolantLevelLowLampData 4;
BA_ "SPN" SG_ 2566718974 EngCoolantTempHighLampData 5100;
BA_ "SigType" SG_ 2566718974 EngCoolantTempHighLampData 4;
BA_ "SPN" SG_ 2566718974 EngOilPressLowLampData 5099;
BA_ "SigType" SG_ 2566718974 EngOilPressLowLampData 4;
BA_ "SPN" SG_ 2566718974 CmprssnBrkEnblSwtchIndctrLmpDta 5098;
BA_ "SigType" SG_ 2566718974 CmprssnBrkEnblSwtchIndctrLmpDta 4;
BA_ "SPN" SG_ 2566718974 EngBrakeActiveLampData 5097;
BA_ "SigType" SG_ 2566718974 EngBrakeActiveLampData 4;
BA_ "SPN" SG_ 2566718974 OBDMalfunctionIndicatorLampData 5096;
BA_ "SigType" SG_ 2566718974 OBDMalfunctionIndicatorLampData 4;
BA_ "SPN" SG_ 2566718974 EngRedStopLampData 5095;
BA_ "SigType" SG_ 2566718974 EngRedStopLampData 4;
BA_ "SPN" SG_ 2566718974 EngAmberWarningLampData 5094;
BA_ "SigType" SG_ 2566718974 EngAmberWarningLampData 4;
BA_ "SPN" SG_ 2566718974 EngProtectLampData 5093;
BA_ "SigType" SG_ 2566718974 EngProtectLampData 4;
BA_ "SPN" SG_ 2566719230 VehicleBatteryChargingLampCmd 5091;
BA_ "SigType" SG_ 2566719230 VehicleBatteryChargingLampCmd 4;
BA_ "SPN" SG_ 2566719230 VehicleHVACRecirculationLampCmd 5090;
BA_ "SigType" SG_ 2566719230 VehicleHVACRecirculationLampCmd 4;
BA_ "SPN" SG_ 2566719230 VehicleAirPressLowLampCmd 5089;
BA_ "SigType" SG_ 2566719230 VehicleAirPressLowLampCmd 4;
BA_ "SPN" SG_ 2566719230 VehicleFuelLevelLowLampCmd 5088;
BA_ "SigType" SG_ 2566719230 VehicleFuelLevelLowLampCmd 4;
BA_ "SPN" SG_ 2566719230 VehicleBatteryVoltageLowLampCmd 5087;
BA_ "SigType" SG_ 2566719230 VehicleBatteryVoltageLowLampCmd 4;
BA_ "SPN" SG_ 2560818942 DTCTimeUntilDerate 4123;
BA_ "SigType" SG_ 2560818942 DTCTimeUntilDerate 1;
BA_ "SPN" SG_ 2560818942 DTCTotalPreviouslyActiveTime 4122;
BA_ "SigType" SG_ 2560818942 DTCTotalPreviouslyActiveTime 1;
BA_ "SPN" SG_ 2560818942 DTCTotalActiveTime 4121;
BA_ "SigType" SG_ 2560818942 DTCTotalActiveTime 1;
BA_ "SPN" SG_ 2560818942 FailureModeIdentifier1 1215;
BA_ "SPN" SG_ 2560818942 SPN1High 1214;
BA_ "SPN" SG_ 2560818942 SPN1 1214;
VAL_ 3221225472 TirePressThresholdDetection 7 "NotAvailable" 6 "ErrorIndicator" 5 "NotDefined" 4 "ExtrmUndrPrssTrPrssrIsAtALvlWhr" 3 "UndrPrssTrPrssrIsLwrThnThPrssrD" 2 "NWrnngPrssTrPrssrIsWthnThThrshl" 1 "OvrPrssTrPrssrIsHghrThnThPrssrD" 0 "ExtrmOvrPrssTrPrssrIsAtALvlWhrT" ;
VAL_ 3221225472 CTIWheelEndElectricalFault 3 "NotSupported" 2 "Error" 1 "NotDefined" 0 "Ok" ;
VAL_ 3221225472 CTITireStatus 3 "NotSupported" 2 "Error" 1 "TireLeakDetected" 0 "Ok" ;
VAL_ 3221225472 CTIWheelSensorStatus 3 "NotSupported" 2 "NotDefined" 1 "On" 0 "Off_IsolatedFromCTIPressCtrl" ;
VAL_ 2297441790 SpprtVrblTrnsRpttnRtFrAcclrtnSns 1 "MsTransRate" ;
VAL_ 2297441790 VrtclAcclrtnExRngeFigureOfMerit 3 "NotAvailable" 2 "Error" 1 "VrtclcclrtnIsDgrddDtIsSspctDTEn" 0 "VrtclAcclrtnIsFllyFnctnlDtIsWth" ;
VAL_ 2297441790 LngtdnlAcclrtnExRngFgureOfMerit 3 "NotAvailable" 2 "Error" 1 "LngtdnlAcclrtnIsDgrddDtIsSspctD" 0 "LngtdnlAcclrtnIsFllyFnctnlDtIsW" ;
VAL_ 2297441790 LtrlAcclrtnExRangeFigureOfMerit 3 "NotAvailable" 2 "Error" 1 "LtrlAcclrtnIsDgrddDtIsSspctDTEn" 0 "LtrlAcclrtnIsFllyFnctnlDtIsWthn" ;
VAL_ 2364549630 RollAngleExRangeFigureOfMerit 3 "NotAvailable" 2 "Error" 1 "RllRtDgrddDtIsSspctDTEnvrnmntlC" 0 "RllRtFllyFnctnlDtIsWthnSnsrSpcf" ;
VAL_ 2364549630 RollAngleExRangeCompensation 3 "NotAvailable" 2 "Error" 1 "Off" 0 "On" ;
VAL_ 2364549630 PitchAngleExRangeFigureOfMerit 3 "NotAvailable" 2 "Error" 1 "PtchRtDgrddDtIsSspctDTEnvrnmntl" 0 "PtchRtFllyFnctnlDtIsWthnSnsrSpc" ;
VAL_ 2364549630 PitchAngleExRangeCompensation 3 "NotAvailable" 2 "Error" 1 "Off" 0 "On" ;
VAL_ 2499614462 OccpntClssfcationSystem10Status 3 "NotAvailable" 2 "ErrrClssfctonCannotBeDetermined" 1 "Occupied" 0 "Empty" ;
VAL_ 2499614462 OccpntClssficationSystem9Status 3 "NotAvailable" 2 "ErrrClssfctonCannotBeDetermined" 1 "Occupied" 0 "Empty" ;
VAL_ 2499614462 OccpntClssficationSystem8Status 3 "NotAvailable" 2 "ErrrClssfctonCannotBeDetermined" 1 "Occupied" 0 "Empty" ;
VAL_ 2499614462 OccpntClssficationSystem7Status 3 "NotAvailable" 2 "ErrrClssfctonCannotBeDetermined" 1 "Occupied" 0 "Empty" ;
VAL_ 2499614462 OccpntClssficationSystem6Status 3 "NotAvailable" 2 "ErrrClssfctonCannotBeDetermined" 1 "Occupied" 0 "Empty" ;
VAL_ 2499614462 OccpntClssficationSystem5Status 3 "NotAvailable" 2 "ErrrClssfctonCannotBeDetermined" 1 "Occupied" 0 "Empty" ;
VAL_ 2499614462 OccpntClssficationSystem4Status 3 "NotAvailable" 2 "ErrrClssfctonCannotBeDetermined" 1 "Occupied" 0 "Empty" ;
VAL_ 2499614462 OccpntClssficationSystem3Status 3 "NotAvailable" 2 "ErrrClssfctonCannotBeDetermined" 1 "Occupied" 0 "Empty" ;
VAL_ 2499614462 PssngrOccpntClssfctnSystmStatus 7 "NotAvailable" 5 "ErrrClssfctnOfOccpntCnntBDtrmnd" 3 "Adult" 4 "LargeAdult" 2 "SmallAdult" 1 "Child" 0 "Empty" ;
VAL_ 2499614462 DrvrOccpntClssfctonSystemStatus 7 "NotAvailable" 6 "ErrrClssfctnOfOccpntCnntBDtrmnd" 5 "Reserved" 4 "LargeAdult" 3 "Adult" 2 "SmallAdult" 1 "Child" 0 "Empty" ;
VAL_ 2560098046 CabNoiseCtrlTuningStatus 15 "NotAvailable_NotTuning_NotRqed" 14 "TuningModeError" 10 "AutomaticTuningModeSavingData" 9 "AutomaticTuningModeCmdComplete" 8 "AutomaticTuningMode" 7 "MnlTnngDndRqrsScrtyVerification" 13 "Reserved" 2 "ManualTuningModeSavingData" 1 "ManualTuningModeCmdComplete" 0 "ManualTuningMode" ;
VAL_ 2560098046 CabNoiseCtrlStatus 3 "NotAvailable_NotRqed" 2 "ErrorIndicator" 1 "CabNoiseCtrlSystemOFFLine" 0 "CabNoiseCtrlSystemONLine" ;
VAL_ 2560163582 CabNoiseCtrlTuningState 7 "DontCareNOTCmded" 6 "Reserved" 5 "ExitTuningSavingParameters" 4 "ExitTuningNotSavingParameters" 3 "RmnInTningSaveCurrentParameters" 2 "ActvtAtmtcTnngSttSvngPrmtrsExtO" 1 "ActvtAtmtcTnngWtFrSvAndExitCmds" 0 "ActvtMnlTnngWtFrSaveAndExitCmds" ;
VAL_ 2560163582 CabNoiseCtrlState 3 "DontCare_NotCmded" 2 "Reserved" 1 "BringCabNoiseCtrlSystemOnLine" 0 "TakeCabNoiseCtrlSystemOffLine" ;
VAL_ 2297441534 DropRelayCtrl 3 "TakeNoAction" 2 "Reserved" 1 "OnEnableDropRelayRq" 0 "OffDisableDropRelayRq" ;
VAL_ 2297441534 LiftRelayCtrl 3 "TakeNoAction" 2 "Reserved" 1 "OnEnableLiftRelayRq" 0 "OffDisableLiftRelayRq" ;
VAL_ 2297441534 MaterialDropActiveStatus 3 "NotAvailable" 2 "Error" 1 "On" 0 "Off" ;
VAL_ 2297441534 MaterialLiftActiveStatus 3 "NotAvailable" 2 "Error" 1 "On" 0 "Off" ;
VAL_ 2297441534 GnratorCurrentBoostActiveStatus 3 "NotAvailable" 2 "Error" 1 "On" 0 "Off" ;
VAL_ 2297441534 MaterialDropSwitch 3 "NotAvailable" 2 "Error" 1 "Drop" 0 "DontDrop" ;
VAL_ 2297441534 MaterialLiftSwitch 3 "NotAvailable" 2 "Error" 1 "Lift" 0 "DontLift" ;
VAL_ 2566722302 GneratorDutyCycleExceededStatus 3 "NotAvaiable" 2 "Error" 1 "DutyCycleExceed" 0 "DutyCycleNotExceed" ;
VAL_ 2566722302 VoltageMonitorActiveStatus 3 "NotAvailable" 2 "Error" 1 "MonitorIsOn" 0 "MonitorIsOff" ;
VAL_ 2566722302 GensetEnableActiveStatus 3 "NotAvaialble" 2 "Error" 1 "Enabled" 0 "NotEnabled" ;
VAL_ 2566722302 ReverseCurrentRangeSetting 31 "NotAvailable" 30 "Error" 16 "11101NotUsed" 15 "16" 14 "15" 13 "14" 12 "13" 11 "12" 10 "11" 9 "10" 8 "9" 7 "8" 6 "7" 5 "6" 4 "5" 3 "4" 2 "3" 1 "2" 0 "1" ;
VAL_ 2566722302 GensetSoftstartActiveStatus 3 "NotAvailable" 2 "Error" 1 "On" 0 "Off" ;
VAL_ 2566722302 Grapple_MagnetSelectionSwitch 3 "NotAvailable" 2 "Error" 1 "MagnetSelected" 0 "GrappleSelected" ;
VAL_ 2566722302 GnstSystmOtptVoltageRangeStatus 3 "NotAvailable" 2 "Error" 1 "InRange" 0 "OutOfRange" ;
VAL_ 2566722302 GeneratorOverheatStatus 3 "NotAvailable" 2 "Error" 1 "Overheat" 0 "NotOverheat" ;
VAL_ 2560032510 LwVltgDscnnctDsredOperatingMode 15 "NoChange" 6 "1110Reserved" 5 "ManualConnect" 4 "ManualDisconnect" 1 "0011Reserved" 0 "Automatic" ;
VAL_ 2566717950 LwVltgDisconnectVoutOutputState 15 "NotAvailableNotInstalled" 14 "OutputFault" 5 "1101Reserved" 4 "ConnectPendingAlarmActive" 3 "DisconnectPendingAlarmActive" 2 "DscnnctAlrmExprdOtptOffDscnnctd" 1 "OutputOnConnected" 0 "OutputOffDisconnected" ;
VAL_ 2566717950 LwVoltageDisconnectOutput1State 15 "NotAvailableNotInstalled" 14 "OutputFault" 5 "1101Reserved" 4 "ConnectPendingAlarmActive" 3 "DisconnectPendingAlarmActive" 2 "DscnnctAlrmExprdOtptOffDscnnctd" 1 "OutputOnConnected" 0 "OutputOffDisconnected" ;
VAL_ 2566717950 LwVoltageDisconnectOutput2State 15 "NotAvailableNotInstalled" 14 "OutputFault" 5 "1101Reserved" 4 "ConnectPendingAlarmActive" 3 "DisconnectPendingAlarmActive" 2 "DscnnctAlrmExprdOtptOffDscnnctd" 1 "OutputOnConnected" 0 "OutputOffDisconnected" ;
VAL_ 2566717950 LwVoltageDisconnectOutput3State 15 "NotAvailableNotInstalled" 14 "OutputFault" 5 "1101Reserved" 4 "ConnectPendingAlarmActive" 3 "DisconnectPendingAlarmActive" 2 "DscnnctAlrmExprdOtptOffDscnnctd" 1 "OutputOnConnected" 0 "OutputOffDisconnected" ;
VAL_ 2566717950 LwVltgDscnnctCrrntOperatingMode 15 "NotAvailable" 10 "1110Reserved" 9 "ManualConnectViaHardwiredInput" 8 "MnalDisconnectViaHardwiredInput" 6 "0111Reserved" 5 "ManualConnectViaJ1939Rq" 4 "ManualDisconnectViaJ1939Rq" 1 "0011Reserved" 0 "Automatic" ;
VAL_ 2566717950 LwVltgDscnnctManualConnectState 3 "NotInstalled" 2 "Error" 1 "InputOn" 0 "InputOff" ;
VAL_ 2566717950 LwVltgDscnnctMnlDisconnectState 3 "NotInstalled" 2 "Error" 1 "InputOn" 0 "InputOff" ;
VAL_ 2358902526 Joystick3Lamp10Cmd 3 "NotAvailableNotInstalled" 2 "Blinking" 1 "On" 0 "Off" ;
VAL_ 2358902526 Joystick3Lamp9Cmd 3 "NotAvailableNotInstalled" 2 "Blinking" 1 "On" 0 "Off" ;
VAL_ 2358902526 Joystick3Lamp8Cmd 3 "NotAvailableNotInstalled" 2 "Blinking" 1 "On" 0 "Off" ;
VAL_ 2358902526 Joystick3Lamp7Cmd 3 "NotAvailableNotInstalled" 2 "Blinking" 1 "On" 0 "Off" ;
VAL_ 2358902526 Joystick3Lamp6Cmd 3 "NotAvailableNotInstalled" 2 "Blinking" 1 "On" 0 "Off" ;
VAL_ 2358902526 Joystick3Lamp5Cmd 3 "NotAvailableNotInstalled" 2 "Blinking" 1 "On" 0 "Off" ;
VAL_ 2358902526 Joystick3Lamp4Cmd 3 "NotAvailableNotInstalled" 2 "Blinking" 1 "On" 0 "Off" ;
VAL_ 2358902526 Joystick3Lamp3Cmd 3 "NotAvailableNotInstalled" 2 "Blinking" 1 "On" 0 "Off" ;
VAL_ 2358902526 Joystick3Lamp2Cmd 3 "NotAvailableNotInstalled" 2 "Blinking" 1 "On" 0 "Off" ;
VAL_ 2358902526 Joystick3Lamp1Cmd 3 "NotAvailableNotInstalled" 2 "Blinking" 1 "On" 0 "Off" ;
VAL_ 2358902526 Joystick2Lamp10Cmd 3 "NotAvailableNotInstalled" 2 "Blinking" 1 "On" 0 "Off" ;
VAL_ 2358902526 Joystick2Lamp9Cmd 3 "NotAvailableNotInstalled" 2 "Blinking" 1 "On" 0 "Off" ;
VAL_ 2358902526 Joystick2Lamp8Cmd 3 "NotAvailableNotInstalled" 2 "Blinking" 1 "On" 0 "Off" ;
VAL_ 2358902526 Joystick2Lamp7Cmd 3 "NotAvailableNotInstalled" 2 "Blinking" 1 "On" 0 "Off" ;
VAL_ 2358902526 Joystick2Lamp6Cmd 3 "NotAvailableNotInstalled" 2 "Blinking" 1 "On" 0 "Off" ;
VAL_ 2358902526 Joystick2Lamp5Cmd 3 "NotAvailableNotInstalled" 2 "Blinking" 1 "On" 0 "Off" ;
VAL_ 2358902526 Joystick2Lamp4Cmd 3 "NotAvailableNotInstalled" 2 "Blinking" 1 "On" 0 "Off" ;
VAL_ 2358902526 Joystick2Lamp3Cmd 3 "NotAvailableNotInstalled" 2 "Blinking" 1 "On" 0 "Off" ;
VAL_ 2358902526 Joystick2Lamp2Cmd 3 "NotAvailableNotInstalled" 2 "Blinking" 1 "On" 0 "Off" ;
VAL_ 2358902526 Joystick2Lamp1Cmd 3 "NotAvailableNotInstalled" 2 "Blinking" 1 "On" 0 "Off" ;
VAL_ 2358902526 Joystick1Lamp10Cmd 3 "NotAvailableNotInstalled" 2 "Blinking" 1 "On" 0 "Off" ;
VAL_ 2358902526 Joystick1Lamp9Cmd 3 "NotAvailableNotInstalled" 2 "Blinking" 1 "On" 0 "Off" ;
VAL_ 2358902526 Joystick1Lamp8Cmd 3 "NotAvailableNotInstalled" 2 "Blinking" 1 "On" 0 "Off" ;
VAL_ 2358902526 Joystick1Lamp7Cmd 3 "NotAvailableNotInstalled" 2 "Blinking" 1 "On" 0 "Off" ;
VAL_ 2358902526 Joystick1Lamp6Cmd 3 "NotAvailableNotInstalled" 2 "Blinking" 1 "On" 0 "Off" ;
VAL_ 2358902526 Joystick1Lamp5Cmd 3 "NotAvailableNotInstalled" 2 "Blinking" 1 "On" 0 "Off" ;
VAL_ 2358902526 Joystick1Lamp4Cmd 3 "NotAvailableNotInstalled" 2 "Blinking" 1 "On" 0 "Off" ;
VAL_ 2358902526 Joystick1Lamp3Cmd 3 "NotAvailableNotInstalled" 2 "Blinking" 1 "On" 0 "Off" ;
VAL_ 2358902526 Joystick1Lamp2Cmd 3 "NotAvailableNotInstalled" 2 "Blinking" 1 "On" 0 "Off" ;
VAL_ 2358902526 Joystick1Lamp1Cmd 3 "NotAvailableNotInstalled" 2 "Blinking" 1 "On" 0 "Off" ;
VAL_ 2566711550 IntkVlvActtnSystmOlPrss2SlndCtrl 3 "notAvailable" 2 "reservedForSAEAssignment" 1 "on" 0 "off" ;
VAL_ 2566711550 IntkVlvActtnSystmOlPrss1SlndCtrl 3 "notAvailable" 2 "reservedForSAEAssignment" 1 "on" 0 "off" ;
VAL_ 2566713854 EngTrbWstgtActtr2OprationStatus 14 "Error" 6 "1101ReservedForFutureAssignment" 5 "UnCtrlledShutdownActive" 4 "CtrlledShutdownActive" 3 "DerateActive" 2 "AlarmHighSeverity" 1 "Alarm" 0 "Normal" ;
VAL_ 2566713854 EngTrbWstgtActtr1OprationStatus 14 "Error" 6 "1101ReservedForFutureAssignment" 5 "UnCtrlledShutdownActive" 4 "CtrlledShutdownActive" 3 "DerateActive" 2 "AlarmHighSeverity" 1 "Alarm" 0 "Normal" ;
VAL_ 2566713854 EngTrbWstgteActuator2TempStatus 7 "NotAvailable" 6 "Error" 5 "NotDefined" 4 "LowMostSevere" 3 "LowLeastSevere" 2 "InRange" 1 "HighLeastSevere" 0 "HighMostSevere" ;
VAL_ 2566714366 EngTrbCmprssrBypssActtr2OprtnStt 14 "Error" 6 "1101ReservedForFutureAssignment" 5 "UnCtrlledShutdownActive" 4 "CtrlledShutdownActive" 3 "DerateActive" 2 "AlarmHighSeverity" 1 "Alarm" 0 "Normal" ;
VAL_ 2566714366 EngTrbCmprssrBypssActtr1OprtnStt 14 "Error" 6 "1101ReservedForFutureAssignment" 5 "UnCtrlledShutdownActive" 4 "CtrlledShutdownActive" 3 "DerateActive" 2 "AlarmHighSeverity" 1 "Alarm" 0 "Normal" ;
VAL_ 2566714366 EngTrbCmprssrBypssActtr2TmpStts 7 "NotAvailable" 6 "Error" 5 "NotDefined" 4 "LowMostSevere" 3 "LowLeastSevere" 2 "InRange" 1 "HighLeastSevere" 0 "HighMostSevere" ;
VAL_ 2566714366 EngTrbCmprssrBypassActuator2Pos 4 "RprsntsBypssFllyOpnTypcllyCmprs" ;
VAL_ 2566714110 EngFuelValve2OperationStatus 14 "Error" 6 "1101ReservedForFutureAssignment" 5 "UnCtrlledShutdownActive" 4 "CtrlledShutdownActive" 3 "DerateActive" 2 "AlarmHighSeverity" 1 "Alarm" 0 "Normal" ;
VAL_ 2566714110 EngFuelValve1OperationStatus 14 "Error" 6 "1101ReservedForFutureAssignment" 5 "UnCtrlledShutdownActive" 4 "CtrlledShutdownActive" 3 "DerateActive" 2 "AlarmHighSeverity" 1 "Alarm" 0 "Normal" ;
VAL_ 2566714110 EngThrttleValve2OperationStatus 14 "Error" 6 "1101ReservedForFutureAssignment" 5 "UnCtrlledShutdownActive" 4 "CtrlledShutdownActive" 3 "DerateActive" 2 "AlarmHighSeverity" 1 "Alarm" 0 "Normal" ;
VAL_ 2566714110 EngThrttleValve1OperationStatus 15 "NotAvailable" 14 "Error" 6 "1101ReservedForFutureAssignment" 5 "UnCtrlledShutdownActive" 4 "CtrlledShutdownActive" 3 "DerateActive" 2 "AlarmHighSeverity" 1 "Alarm" 0 "Normal" ;
VAL_ 2566714110 EngFuelValve2TempStatus 7 "NotAvailable" 6 "Error" 5 "NotDefined" 4 "LowMostSevere" 3 "LowLeastSevere" 2 "InRange" 1 "HighLeastSevere" 0 "HighMostSevere" ;
VAL_ 2566714110 EngFuelValve1TempStatus 7 "NotAvailable" 6 "Error" 5 "NotDefined" 4 "LowMostSevere" 3 "LowLeastSevere" 2 "InRange" 1 "HighLeastSevere" 0 "HighMostSevere" ;
VAL_ 2566714110 EngThrottleValve2TempStatus 7 "NotAvailable" 6 "Error" 5 "NotDefined" 4 "LowMostSevere" 3 "LowLeastSevere" 2 "InRange" 1 "HighLeastSevere" 0 "HighMostSevere" ;
VAL_ 2566714110 EngThrottleValve1TempStatus 7 "NotAvailable" 6 "Error" 5 "NotDefined" 4 "LowMostSevere" 3 "LowLeastSevere" 2 "InRange" 1 "HighLeastSevere" 0 "HighMostSevere" ;
VAL_ 2499607550 EngExhstMnfldBnk1FlwBlncVlvActtr 4 "MeansMaxValveOpening" ;
VAL_ 2633825534 EngExhstMnfldBnk2FlwBlncVlv_0000 4 "MeansMaxValveOpening" ;
VAL_ 2365400574 Jystck9GripXAxisDetentPosStatus 3 "NotAvailable" 2 "ErrorIndicator" 1 "InDetentPos" 0 "NotInDetentPos" ;
VAL_ 2365400574 Jystck9GripYAxisDetentPosStatus 3 "NotAvailable" 2 "ErrorIndicator" 1 "InDetentPos" 0 "NotInDetentPos" ;
VAL_ 2365400574 Jystck9ThetaAxisDetentPosStatus 3 "NotAvailable" 2 "ErrorIndicator" 1 "InDetentPos" 0 "NotInDetentPos" ;
VAL_ 2365400574 Jystck9ThtAxsClckwsPstvPsStatus 3 "NotAvailable" 2 "ErrorIndicator" 1 "OnPositiveSideOfNeutral" 0 "NotOnPositiveSideOfNeutral" ;
VAL_ 2365400574 Jystck9ThtAxsCntrClckwsNgtvPsStt 3 "NotAvailable" 2 "ErrorIndicator" 1 "OnNegativeSideOfNeutral" 0 "NotOnNegativeSideOfNeutral" ;
VAL_ 2365400574 Jystck9ThtaAxisNeutralPosStatus 3 "NotAvailable" 2 "ErrorIndicator" 1 "InNeutralPos" 0 "NotInNeutralPos" ;
VAL_ 2365400574 Jystck9GrpYAxsLvrFrwrdPstvPsStts 3 "NotAvailable" 2 "ErrorIndicator" 1 "OnPositiveSideOfNeutral" 0 "NotOnPositiveSideOfNeutral" ;
VAL_ 2365400574 Jystck9GrpYAxsLvrBckNgtvPsSttus 3 "NotAvailable" 2 "ErrorIndicator" 1 "OnNegativeSideOfNeutral" 0 "NotOnNegativeSideOfNeutral" ;
VAL_ 2365400574 Jystck9GrpYAxisNeutralPosStatus 3 "NotAvailable" 2 "ErrorIndicator" 1 "InNeutralPos" 0 "NotInNeutralPos" ;
VAL_ 2365400574 Jystck9GrpXAxsLvrRghtPstvPsStts 3 "NotAvailable" 2 "ErrorIndicator" 1 "OnPositiveSideOfNeutral" 0 "NotOnPositiveSideOfNeutral" ;
VAL_ 2365400574 Jystck9GrpXAxsLvrLftNgtvPsSttus 3 "NotAvailable" 2 "ErrorIndicator" 1 "OnNegativeSideOfNeutral" 0 "NotOnNegativeSideOfNeutral" ;
VAL_ 2365400574 Jystck9GrpXAxisNeutralPosStatus 3 "NotAvailable" 2 "ErrorIndicator" 1 "InNeutralPos" 0 "NotInNeutralPos" ;
VAL_ 2365401086 Jystck8GripXAxisDetentPosStatus 3 "NotAvailable" 2 "ErrorIndicator" 1 "InDetentPos" 0 "NotInDetentPos" ;
VAL_ 2365401086 Jystck8GripYAxisDetentPosStatus 3 "NotAvailable" 2 "ErrorIndicator" 1 "InDetentPos" 0 "NotInDetentPos" ;
VAL_ 2365401086 Jystck8ThetaAxisDetentPosStatus 3 "NotAvailable" 2 "ErrorIndicator" 1 "InDetentPos" 0 "NotInDetentPos" ;
VAL_ 2365401086 Jystck8ThtAxsClckwsPstvPsStatus 3 "NotAvailable" 2 "ErrorIndicator" 1 "OnPositiveSideOfNeutral" 0 "NotOnPositiveSideOfNeutral" ;
VAL_ 2365401086 Jystck8ThtAxsCntrClckwsNgtvPsStt 3 "NotAvailable" 2 "ErrorIndicator" 1 "OnNegativeSideOfNeutral" 0 "NotOnNegativeSideOfNeutral" ;
VAL_ 2365401086 Jystck8ThtaAxisNeutralPosStatus 3 "NotAvailable" 2 "ErrorIndicator" 1 "InNeutralPos" 0 "NotInNeutralPos" ;
VAL_ 2365401086 Jystck8GrpYAxsLvrFrwrdPstvPsStts 3 "NotAvailable" 2 "ErrorIndicator" 1 "OnPositiveSideOfNeutral" 0 "NotOnPositiveSideOfNeutral" ;
VAL_ 2365401086 Jystck8GrpYAxsLvrBckNgtvPsSttus 3 "NotAvailable" 2 "ErrorIndicator" 1 "OnNegativeSideOfNeutral" 0 "NotOnNegativeSideOfNeutral" ;
VAL_ 2365401086 Jystck8GrpYAxisNeutralPosStatus 3 "NotAvailable" 2 "ErrorIndicator" 1 "InNeutralPos" 0 "NotInNeutralPos" ;
VAL_ 2365401086 Jystck8GrpXAxsLvrRghtPstvPsStts 3 "NotAvailable" 2 "ErrorIndicator" 1 "OnPositiveSideOfNeutral" 0 "NotOnPositiveSideOfNeutral" ;
VAL_ 2365401086 Jystck8GrpXAxsLvrLftNgtvPsSttus 3 "NotAvailable" 2 "ErrorIndicator" 1 "OnNegativeSideOfNeutral" 0 "NotOnNegativeSideOfNeutral" ;
VAL_ 2365401086 Jystck8GrpXAxisNeutralPosStatus 3 "NotAvailable" 2 "ErrorIndicator" 1 "InNeutralPos" 0 "NotInNeutralPos" ;
VAL_ 2365401598 Jystck7GripXAxisDetentPosStatus 3 "NotAvailable" 2 "ErrorIndicator" 1 "InDetentPos" 0 "NotInDetentPos" ;
VAL_ 2365401598 Jystck7GripYAxisDetentPosStatus 3 "NotAvailable" 2 "ErrorIndicator" 1 "InDetentPos" 0 "NotInDetentPos" ;
VAL_ 2365401598 Jystck7ThetaAxisDetentPosStatus 3 "NotAvailable" 2 "ErrorIndicator" 1 "InDetentPos" 0 "NotInDetentPos" ;
VAL_ 2365401598 Jystck7ThtAxsClckwsPstvPsStatus 3 "NotAvailable" 2 "ErrorIndicator" 1 "OnPositiveSideOfNeutral" 0 "NotOnPositiveSideOfNeutral" ;
VAL_ 2365401598 Jystck7ThtAxsCntrClckwsNgtvPsStt 3 "NotAvailable" 2 "ErrorIndicator" 1 "OnNegativeSideOfNeutral" 0 "NotOnNegativeSideOfNeutral" ;
VAL_ 2365401598 Jystck7ThtaAxisNeutralPosStatus 3 "NotAvailable" 2 "ErrorIndicator" 1 "InNeutralPos" 0 "NotInNeutralPos" ;
VAL_ 2365401598 Jystck7GrpYAxsLvrFrwrdPstvPsStts 3 "NotAvailable" 2 "ErrorIndicator" 1 "OnPositiveSideOfNeutral" 0 "NotOnPositiveSideOfNeutral" ;
VAL_ 2365401598 Jystck7GrpYAxsLvrBckNgtvPsSttus 3 "NotAvailable" 2 "ErrorIndicator" 1 "OnNegativeSideOfNeutral" 0 "NotOnNegativeSideOfNeutral" ;
VAL_ 2365401598 Jystck7GrpYAxisNeutralPosStatus 3 "NotAvailable" 2 "ErrorIndicator" 1 "InNeutralPos" 0 "NotInNeutralPos" ;
VAL_ 2365401598 Jystck7GrpXAxsLvrRghtPstvPsStts 3 "NotAvailable" 2 "ErrorIndicator" 1 "OnPositiveSideOfNeutral" 0 "NotOnPositiveSideOfNeutral" ;
VAL_ 2365401598 Jystck7GrpXAxsLvrLftNgtvPsSttus 3 "NotAvailable" 2 "ErrorIndicator" 1 "OnNegativeSideOfNeutral" 0 "NotOnNegativeSideOfNeutral" ;
VAL_ 2365401598 Jystck7GrpXAxisNeutralPosStatus 3 "NotAvailable" 2 "ErrorIndicator" 1 "InNeutralPos" 0 "NotInNeutralPos" ;
VAL_ 2365402110 Jystck6GripXAxisDetentPosStatus 3 "NotAvailable" 2 "ErrorIndicator" 1 "InDetentPos" 0 "NotInDetentPos" ;
VAL_ 2365402110 Jystck6GripYAxisDetentPosStatus 3 "NotAvailable" 2 "ErrorIndicator" 1 "InDetentPos" 0 "NotInDetentPos" ;
VAL_ 2365402110 Jystck6ThetaAxisDetentPosStatus 3 "NotAvailable" 2 "ErrorIndicator" 1 "InDetentPos" 0 "NotInDetentPos" ;
VAL_ 2365402110 Jystck6ThtAxsClckwsPstvPsStatus 3 "NotAvailable" 2 "ErrorIndicator" 1 "OnPositiveSideOfNeutral" 0 "NotOnPositiveSideOfNeutral" ;
VAL_ 2365402110 Jystck6ThtAxsCntrClckwsNgtvPsStt 3 "NotAvailable" 2 "ErrorIndicator" 1 "OnNegativeSideOfNeutral" 0 "NotOnNegativeSideOfNeutral" ;
VAL_ 2365402110 Jystck6ThtaAxisNeutralPosStatus 3 "NotAvailable" 2 "ErrorIndicator" 1 "InNeutralPos" 0 "NotInNeutralPos" ;
VAL_ 2365402110 Jystck6GrpYAxsLvrFrwrdPstvPsStts 3 "NotAvailable" 2 "ErrorIndicator" 1 "OnPositiveSideOfNeutral" 0 "NotOnPositiveSideOfNeutral" ;
VAL_ 2365402110 Jystck6GrpYAxsLvrBckNgtvPsSttus 3 "NotAvailable" 2 "ErrorIndicator" 1 "OnNegativeSideOfNeutral" 0 "NotOnNegativeSideOfNeutral" ;
VAL_ 2365402110 Jystck6GrpYAxisNeutralPosStatus 3 "NotAvailable" 2 "ErrorIndicator" 1 "InNeutralPos" 0 "NotInNeutralPos" ;
VAL_ 2365402110 Jystck6GrpXAxsLvrRghtPstvPsStts 3 "NotAvailable" 2 "ErrorIndicator" 1 "OnPositiveSideOfNeutral" 0 "NotOnPositiveSideOfNeutral" ;
VAL_ 2365402110 Jystck6GrpXAxsLvrLftNgtvPsSttus 3 "NotAvailable" 2 "ErrorIndicator" 1 "OnNegativeSideOfNeutral" 0 "NotOnNegativeSideOfNeutral" ;
VAL_ 2365402110 Jystck6GrpXAxisNeutralPosStatus 3 "NotAvailable" 2 "ErrorIndicator" 1 "InNeutralPos" 0 "NotInNeutralPos" ;
VAL_ 2365402622 Jystck5GripXAxisDetentPosStatus 3 "NotAvailable" 2 "ErrorIndicator" 1 "InDetentPos" 0 "NotInDetentPos" ;
VAL_ 2365402622 Jystck5GripYAxisDetentPosStatus 3 "NotAvailable" 2 "ErrorIndicator" 1 "InDetentPos" 0 "NotInDetentPos" ;
VAL_ 2365402622 Jystck5ThetaAxisDetentPosStatus 3 "NotAvailable" 2 "ErrorIndicator" 1 "InDetentPos" 0 "NotInDetentPos" ;
VAL_ 2365402622 Jystck5ThtAxsClckwsPstvPsStatus 3 "NotAvailable" 2 "ErrorIndicator" 1 "OnPositiveSideOfNeutral" 0 "NotOnPositiveSideOfNeutral" ;
VAL_ 2365402622 Jystck5ThtAxsCntrClckwsNgtvPsStt 3 "NotAvailable" 2 "ErrorIndicator" 1 "OnNegativeSideOfNeutral" 0 "NotOnNegativeSideOfNeutral" ;
VAL_ 2365402622 Jystck5ThtaAxisNeutralPosStatus 3 "NotAvailable" 2 "ErrorIndicator" 1 "InNeutralPos" 0 "NotInNeutralPos" ;
VAL_ 2365402622 Jystck5GrpYAxsLvrFrwrdPstvPsStts 3 "NotAvailable" 2 "ErrorIndicator" 1 "OnPositiveSideOfNeutral" 0 "NotOnPositiveSideOfNeutral" ;
VAL_ 2365402622 Jystck5GrpYAxsLvrBckNgtvPsSttus 3 "NotAvailable" 2 "ErrorIndicator" 1 "OnNegativeSideOfNeutral" 0 "NotOnNegativeSideOfNeutral" ;
VAL_ 2365402622 Jystck5GrpYAxisNeutralPosStatus 3 "NotAvailable" 2 "ErrorIndicator" 1 "InNeutralPos" 0 "NotInNeutralPos" ;
VAL_ 2365402622 Jystck5GrpXAxsLvrRghtPstvPsStts 3 "NotAvailable" 2 "ErrorIndicator" 1 "OnPositiveSideOfNeutral" 0 "NotOnPositiveSideOfNeutral" ;
VAL_ 2365402622 Jystck5GrpXAxsLvrLftNgtvPsSttus 3 "NotAvailable" 2 "ErrorIndicator" 1 "OnNegativeSideOfNeutral" 0 "NotOnNegativeSideOfNeutral" ;
VAL_ 2365402622 Jystck5GrpXAxisNeutralPosStatus 3 "NotAvailable" 2 "ErrorIndicator" 1 "InNeutralPos" 0 "NotInNeutralPos" ;
VAL_ 2365403134 Jystck4GripXAxisDetentPosStatus 3 "NotAvailable" 2 "ErrorIndicator" 1 "InDetentPos" 0 "NotInDetentPos" ;
VAL_ 2365403134 Jystck4GripYAxisDetentPosStatus 3 "NotAvailable" 2 "ErrorIndicator" 1 "InDetentPos" 0 "NotInDetentPos" ;
VAL_ 2365403134 Jystck4ThetaAxisDetentPosStatus 3 "NotAvailable" 2 "ErrorIndicator" 1 "InDetentPos" 0 "NotInDetentPos" ;
VAL_ 2365403134 Jystck4ThtAxsClckwsPstvPsStatus 3 "NotAvailable" 2 "ErrorIndicator" 1 "OnPositiveSideOfNeutral" 0 "NotOnPositiveSideOfNeutral" ;
VAL_ 2365403134 Jystck4ThtAxsCntrClckwsNgtvPsStt 3 "NotAvailable" 2 "ErrorIndicator" 1 "OnNegativeSideOfNeutral" 0 "NotOnNegativeSideOfNeutral" ;
VAL_ 2365403134 Jystck4ThtaAxisNeutralPosStatus 3 "NotAvailable" 2 "ErrorIndicator" 1 "InNeutralPos" 0 "NotInNeutralPos" ;
VAL_ 2365403134 Jystck4GrpYAxsLvrFrwrdPstvPsStts 3 "NotAvailable" 2 "ErrorIndicator" 1 "OnPositiveSideOfNeutral" 0 "NotOnPositiveSideOfNeutral" ;
VAL_ 2365403134 Jystck4GrpYAxsLvrBckNgtvPsSttus 3 "NotAvailable" 2 "ErrorIndicator" 1 "OnNegativeSideOfNeutral" 0 "NotOnNegativeSideOfNeutral" ;
VAL_ 2365403134 Jystck4GrpYAxisNeutralPosStatus 3 "NotAvailable" 2 "ErrorIndicator" 1 "InNeutralPos" 0 "NotInNeutralPos" ;
VAL_ 2365403134 Jystck4GrpXAxsLvrRghtPstvPsStts 3 "NotAvailable" 2 "ErrorIndicator" 1 "OnPositiveSideOfNeutral" 0 "NotOnPositiveSideOfNeutral" ;
VAL_ 2365403134 Jystck4GrpXAxsLvrLftNgtvPsSttus 3 "NotAvailable" 2 "ErrorIndicator" 1 "OnNegativeSideOfNeutral" 0 "NotOnNegativeSideOfNeutral" ;
VAL_ 2365403134 Jystck4GrpXAxisNeutralPosStatus 3 "NotAvailable" 2 "ErrorIndicator" 1 "InNeutralPos" 0 "NotInNeutralPos" ;
VAL_ 2365400062 Jystck10GrpXAxisDetentPosStatus 3 "NotAvailable" 2 "ErrorIndicator" 1 "InDetentPos" 0 "NotInDetentPos" ;
VAL_ 2365400062 Jystck10GrpYAxisDetentPosStatus 3 "NotAvailable" 2 "ErrorIndicator" 1 "InDetentPos" 0 "NotInDetentPos" ;
VAL_ 2365400062 Jystck10ThtaAxisDetentPosStatus 3 "NotAvailable" 2 "ErrorIndicator" 1 "InDetentPos" 0 "NotInDetentPos" ;
VAL_ 2365400062 Jystck10ThtAxsClckwsPstvPsSttus 3 "NotAvailable" 2 "ErrorIndicator" 1 "OnPositiveSideOfNeutral" 0 "NotOnPositiveSideOfNeutral" ;
VAL_ 2365400062 Jystck10ThtAxsCntrClckwsNgtvPsSt 3 "NotAvailable" 2 "ErrorIndicator" 1 "OnNegativeSideOfNeutral" 0 "NotOnNegativeSideOfNeutral" ;
VAL_ 2365400062 Jystck10ThtAxisNeutralPosStatus 3 "NotAvailable" 2 "ErrorIndicator" 1 "InNeutralPos" 0 "NotInNeutralPos" ;
VAL_ 2365400062 Jystck10GrpYAxsLvrFrwrdPstvPsStt 3 "NotAvailable" 2 "ErrorIndicator" 1 "OnPositiveSideOfNeutral" 0 "NotOnPositiveSideOfNeutral" ;
VAL_ 2365400062 Jystck10GrpYAxsLvrBckNgtvPsStts 3 "NotAvailable" 2 "ErrorIndicator" 1 "OnNegativeSideOfNeutral" 0 "NotOnNegativeSideOfNeutral" ;
VAL_ 2365400062 Jystck10GrpYAxsNeutralPosStatus 3 "NotAvailable" 2 "ErrorIndicator" 1 "InNeutralPos" 0 "NotInNeutralPos" ;
VAL_ 2365400062 Jystck10GrpXAxsLvrRghtPstvPsStts 3 "NotAvailable" 2 "ErrorIndicator" 1 "OnPositiveSideOfNeutral" 0 "NotOnPositiveSideOfNeutral" ;
VAL_ 2365400062 Jystck10GrpXAxsLvrLftNgtvPsStts 3 "NotAvailable" 2 "ErrorIndicator" 1 "OnNegativeSideOfNeutral" 0 "NotOnNegativeSideOfNeutral" ;
VAL_ 2365400062 Jystck10GrpXAxsNeutralPosStatus 3 "NotAvailable" 2 "ErrorIndicator" 1 "InNeutralPos" 0 "NotInNeutralPos" ;
VAL_ 2633825022 EngExhstGsRcrclation2Valve2Ctrl 4 "MeansMaxOpening" ;
VAL_ 2633825022 EngExhstGsRcrculation2ValveCtrl 4 "MeansMaxOpening" ;
VAL_ 2566749438 DslPrtcltFltrActvRgnrtnFrcdStts 7 "notAvailable" 6 "ReservedForSAEAssignment" 2 "ActiveForcedByServiceTool" 1 "ActiveForcedBySwitch" 0 "NotActive" ;
VAL_ 2566749438 ExhaustSystemHighTempLampCmd 7 "notAvailable" 6 "reservedForSAEAssignment" 1 "OnSolid" 0 "Off" ;
VAL_ 2566749438 DslPrtcltFltrAtmtcActvRgnrtnIntt 3 "notAvailable" 2 "reservedForSAEAssignment" 1 "enabled" 0 "notEnabled" ;
VAL_ 2566749438 DslPrtcltFltrActvRgnrtnInhbtdDTV 3 "notAvailable" 2 "reservedForSAEAssignment" 1 "inhibited" 0 "notInhibited" ;
VAL_ 2566749438 DslPrtcltFltrActvRgnrtnInhbtdDTE 3 "notAvailable" 2 "reservedForSAEAssignment" 1 "inhibited" 0 "notInhibited" ;
VAL_ 2566749438 DslPrtcltFltrActvRgnrtnInhbtdDTP 3 "notAvailable" 2 "reservedForSAEAssignment" 1 "inhibited" 0 "notInhibited" ;
VAL_ 2566749438 DslPrtcltFltrActvRgnrtnInhbtdDTT 3 "notAvailable" 2 "reservedForSAEAssignment" 1 "inhibited" 0 "notInhibited" ;
VAL_ 2566749438 DslPrtcltFltrActvRgnrtnInhbtdDTS 3 "notAvailable" 2 "reservedForSAEAssignment" 1 "inhibited" 0 "notInhibited" ;
VAL_ 2566749438 DslPrtcltFltrActvRgnrtnInhb_0000 3 "notAvailable" 2 "reservedForSAEAssignment" 1 "inhibited" 0 "notInhibited" ;
VAL_ 2566749438 DslPrtcltFltrActvRgnrtnInhbtdDTL 3 "notAvailable" 2 "reservedForSAEAssignment" 1 "inhibited" 0 "notInhibited" ;
VAL_ 2566749438 DslPrtcltFltrActvRgnrtnInhb_0001 3 "notAvailable" 2 "reservedForSAEAssignment" 1 "inhibited" 0 "notInhibited" ;
VAL_ 2566749438 DslPrtcltFltrActvRgnrtnInhb_0002 3 "notAvailable" 2 "reservedForSAEAssignment" 1 "inhibited" 0 "notInhibited" ;
VAL_ 2566749438 DslPrtcltFltrActvRgnrtnInhbtdDTO 3 "notAvailable" 2 "reservedForSAEAssignment" 1 "inhibited" 0 "notInhibited" ;
VAL_ 2566749438 DslPrtcltFltrActvRgnrtnInhbtdDTA 3 "notAvailable" 2 "reservedForSAEAssignment" 1 "inhibited" 0 "notInhibited" ;
VAL_ 2566749438 DslPrtcltFltrActvRgnrtnInhb_0003 3 "notAvailable" 2 "reservedForSAEAssignment" 1 "inhibited" 0 "notInhibited" ;
VAL_ 2566749438 DslPrtcltFltrActvRgnrtnInhb_0004 3 "notAvailable" 2 "reservedForSAEAssignment" 1 "inhibited" 0 "notInhibited" ;
VAL_ 2566749438 DslPrtcltFltrActvRgnrtnInhbtdDTC 3 "notAvailable" 2 "reservedForSAEAssignment" 1 "inhibited" 0 "notInhibited" ;
VAL_ 2566749438 DslPrtcltFltrActvRgnrtnInhbtdDTI 3 "notAvailable" 2 "reservedForSAEAssignment" 1 "inhibited" 0 "notInhibited" ;
VAL_ 2566749438 DslPrtcltFltrActvRgnrtnInhbtdStt 3 "notAvailable" 2 "reservedForSAEAssignment" 1 "inhibited" 0 "notInhibited" ;
VAL_ 2566749438 DieselParticulateFilterStatus 7 "notAvailable" 6 "reservedForSAEAssignment" 3 "RegenerationNeededHighestLevel" 2 "RegenerationNeededModerateLevel" 1 "RegenerationNeededLowestLevel" 0 "RegenerationNotNeeded" ;
VAL_ 2566749438 DslPrtcltFltrActvRgnrtionStatus 3 "notAvailable" 2 "rgnrtnNddAtmtcllyInttdActvRgnrt" 1 "active" 0 "notActive" ;
VAL_ 2566749438 DslPrtcltFltrPssvRgnrtionStatus 3 "notAvailable" 2 "reservedForSAEAssignment" 1 "active" 0 "notActive" ;
VAL_ 2566749438 DieselParticulateFilterLampCmd 7 "notAvailable" 4 "OnFastBlink" 6 "reservedForSAEAssignment" 1 "OnSolid" 0 "Off" ;
VAL_ 2566718718 VehicleBatteryChargingLampData 3 "NotAvailable" 2 "Error" 1 "LampActivated" 0 "LampDeactivated" ;
VAL_ 2566718718 VhicleHVACRecirculationLampData 3 "NotAvailable" 2 "Error" 1 "LampActivated" 0 "LampDeactivated" ;
VAL_ 2566718718 VehicleAirPressLowLampData 3 "NotAvailable" 2 "Error" 1 "LampActivated" 0 "LampDeactivated" ;
VAL_ 2566718718 VehicleFuelLevelLowLampData 3 "NotAvailable" 2 "Error" 1 "LampActivated" 0 "LampDeactivated" ;
VAL_ 2566718718 VhicleBatteryVoltageLowLampData 3 "NotAvailable" 2 "Error" 1 "LampActivated" 0 "LampDeactivated" ;
VAL_ 2566718974 EngWaitToStartLampData 3 "NotAvailable" 2 "Error" 1 "LampActive" 0 "LampDeactive" ;
VAL_ 2566718974 EngFuelFilterRestrictedLampData 3 "NotAvailable" 2 "Error" 1 "LampActivated" 0 "LampDeactivated" ;
VAL_ 2566718974 EngAirFilterRestrictionLampData 3 "NotAvailable" 2 "Error" 1 "LampActivated" 0 "LampDeactivated" ;
VAL_ 2566718974 EngIdleManagementActiveLampData 3 "NotAvailable" 2 "Error" 1 "LampActivated" 0 "LampDeactivated" ;
VAL_ 2566718974 EngCoolantLevelLowLampData 3 "NotAvailable" 2 "Error" 1 "LampActivated" 0 "LampDeactivated" ;
VAL_ 2566718974 EngCoolantTempHighLampData 3 "NotAvailable" 2 "Error" 1 "LampActivated" 0 "LampDeactivated" ;
VAL_ 2566718974 EngOilPressLowLampData 3 "NotAvailable" 2 "Error" 1 "LampActivated" 0 "LampDeactivated" ;
VAL_ 2566718974 CmprssnBrkEnblSwtchIndctrLmpDta 3 "NotAvailable" 2 "Error" 1 "LampActivated" 0 "LampDeactivated" ;
VAL_ 2566718974 EngBrakeActiveLampData 3 "NotAvailable" 2 "Error" 1 "LampActivated" 0 "LampDeactivated" ;
VAL_ 2566718974 OBDMalfunctionIndicatorLampData 3 "NotAvailable" 2 "Error" 1 "LampActivated" 0 "LampDeactivated" ;
VAL_ 2566718974 EngRedStopLampData 3 "NotAvailable" 2 "Error" 1 "LampActivated" 0 "LampDeactivated" ;
VAL_ 2566718974 EngAmberWarningLampData 3 "NotAvailable" 2 "Error" 1 "LampActivated" 0 "LampDeactivated" ;
VAL_ 2566718974 EngProtectLampData 3 "NotAvailable" 2 "Error" 1 "LampActivated" 0 "LampDeactivated" ;
VAL_ 2566719230 VehicleBatteryChargingLampCmd 3 "NotAvailable" 2 "Reserved" 1 "LampOn" 0 "LampOff" ;
VAL_ 2566719230 VehicleHVACRecirculationLampCmd 3 "NotAvailable" 2 "Reserved" 1 "LampOn" 0 "LampOff" ;
VAL_ 2566719230 VehicleAirPressLowLampCmd 3 "NotAvailable" 2 "Reserved" 1 "LampOn" 0 "LampOff" ;
VAL_ 2566719230 VehicleFuelLevelLowLampCmd 3 "NotAvailable" 2 "Reserved" 1 "LampOn" 0 "LampOff" ;
VAL_ 2566719230 VehicleBatteryVoltageLowLampCmd 3 "NotAvailable" 2 "Reserved" 1 "LampOn" 0 "LampOff" ;
VAL_ 2560818942 FailureModeIdentifier1 31 "Not available" 19 "Received network data in error" 18 "Below normal (moderately severe)" 17 "Below normal (least severe)" 16 "Above normal (moderately severe)" 15 "Above normal (least severe)" 14 "Special intstructions" 13 "Out of calibration" 12 "Bad intelligent device" 11 "Root cause not known" 10 "Abnormal rate of change" 9 "Abnormal update rate" 8 "Abnormal frequency" 7 "Mechanical system not responding" 6 "Current above normal" 5 "Current below normal" 4 "Voltage below normal" 3 "Voltage above normal" 2 "Data erratic" 1 "Below normal (most severe)" 0 "Above normal (most severe)" ;
